[part 6 of 23: package /Cluster]
AUTOSAR XML (schema 4-3-0)
package /Cluster  (continued)
  can cluster E3V_EVCANFD: baudrate=500000, protocol-name=CAN, protocol-version=2.0, bus-off-recovery={bor-counter-l-1-to-l-2=1, bor-time-l-1=0.05, bor-time-l-2=0.2}, can-fd-baudrate=2000000  (continued)
    can physical channel CHNL: comm-connectors=CN_E3V_EVCANFD  (continued)
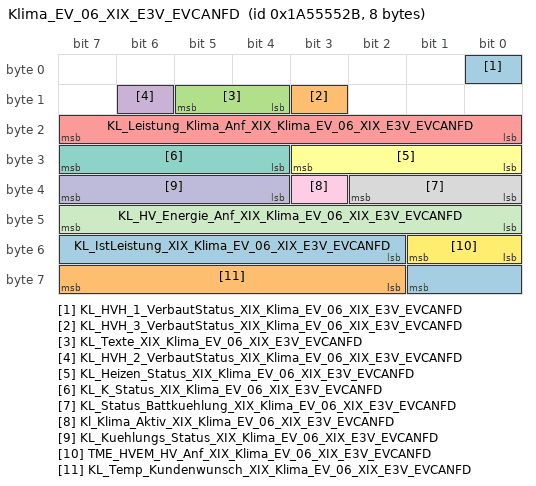
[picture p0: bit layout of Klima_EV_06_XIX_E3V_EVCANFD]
      frame Klima_EV_06_XIX_E3V_EVCANFD: id 0x1A55552B, from Klima, frame-length=8, can-addressing-mode=EXTENDED, can-frame-rx-behavior=CAN-FD, can-frame-tx-behavior=CAN-FD
        pdu Klima_EV_06_XIX_E3V_EVCANFD: length=8, transmission-mode-true-timing=cyclic-timing={time-offset=0.0, time-period=0.5}, unused-bit-pattern=0
          signal KL_HVH_1_VerbautStatus_XIX_Klima_EV_06_XIX_E3V_EVCANFD: start 0, 1 bit, little-endian, data-type-policy=OVERRIDE, i-signal-type=PRIMITIVE, init-value=0, base-type=BT_KL_HVH_1_VerbautStatus, compu {0=Cx0_nicht_verbaut (CM_KL_HVH_1_VerbautStatus_Cx0_nicht_verbaut), 1=Cx1_verbaut (CM_KL_HVH_1_VerbautStatus_Cx1_verbaut)}, range raw 0..1, transfer-property=PENDING  # Verbau Information HV_Heizer1
          signal KL_HVH_3_VerbautStatus_XIX_Klima_EV_06_XIX_E3V_EVCANFD: start 11, 1 bit, little-endian, data-type-policy=OVERRIDE, i-signal-type=PRIMITIVE, base-type=BT_KL_HVH_3_VerbautStatus, compu {0=Cx0_nicht_verbaut (CM_KL_HVH_3_VerbautStatus_Cx0_nicht_verbaut), 1=Cx1_verbaut (CM_KL_HVH_3_VerbautStatus_Cx1_verbaut)}, range raw 0..1, transfer-property=PENDING  # Verbauinformation für 3. HV-Heizer (Wasserheizer im MEB)
          signal KL_Texte_XIX_Klima_EV_06_XIX_E3V_EVCANFD: start 12, 2 bit, little-endian, data-type-policy=OVERRIDE, i-signal-type=PRIMITIVE, base-type=BT_KL_Texte, compu {0=Cx0_keine_Anzeige (CM_KL_Texte_Cx0_keine_Anzeige), 1=Cx1_Heizleistung_zu_gering (CM_KL_Texte_Cx1_Heizleistung_zu_gering), 2=Cx2_Kuehlleistung_zu_gering (CM_KL_Texte_Cx2_Kuehlleistung_zu_gering), 3=Cx3_Text_3 (CM_KL_Texte_Cx3_Text_3)}, range raw 0..3, transfer-property=PENDING  # Ein Defizit in Heizleistung bzw. Kühlleistung soll dem Kunden angezeigt werden
          signal KL_HVH_2_VerbautStatus_XIX_Klima_EV_06_XIX_E3V_EVCANFD: start 14, 1 bit, little-endian, data-type-policy=OVERRIDE, i-signal-type=PRIMITIVE, init-value=0, base-type=BT_KL_HVH_2_VerbautStatus, compu {0=Cx0_nicht_verbaut (CM_KL_HVH_2_VerbautStatus_Cx0_nicht_verbaut), 1=Cx1_verbaut (CM_KL_HVH_2_VerbautStatus_Cx1_verbaut)}, range raw 0..1, transfer-property=PENDING  # Verbau Information zusaetzlicher Heizer
          signal KL_Leistung_Klima_Anf_XIX_Klima_EV_06_XIX_E3V_EVCANFD: start 16, 8 bit, little-endian, data-type-policy=OVERRIDE, i-signal-type=PRIMITIVE, init-value=254, base-type=BT_KL_Leistung_Klima_Anf, compu {phys=raw*50 for raw 0..253, 254=Cxfe_Init (CM_KL_Leistung_Klima_Anf_Cxfe_Init); unit Unit_Watt}, range phys 0..12650 Unit_Watt, raw 0..254, unit=Unit_Watt, transfer-property=PENDING  # Leistungsanforderung ans HVEM von Klima
          signal KL_Heizen_Status_XIX_Klima_EV_06_XIX_E3V_EVCANFD: start 24, 4 bit, little-endian, data-type-policy=OVERRIDE, i-signal-type=PRIMITIVE, init-value=14, base-type=BT_KL_Heizen_Status, invalid-value=Invalid_KL_Heizen_Status_XIX_Klima_EV_06_XIX_E3V_EVCANFD:15, compu {0=Cx0_Keine_Heizleistung_Anfgefordert (CM_KL_Heizen_Status_Cx0_Keine_Heizleistung_Anfgefordert), 1=Cx1_Max_Defrost (CM_KL_Heizen_Status_Cx1_Max_Defrost), 2=Cx2_Kaltstart (CM_KL_Heizen_Status_Cx2_Kaltstart), 3=Cx3_Eingeschwungen_hohe_Last (CM_KL_Heizen_Status_Cx3_Eingeschwungen_hohe_Last), 4=Cx4_Eingeschwungen_niedrige_Last (CM_KL_Heizen_Status_Cx4_Eingeschwungen_niedrige_Last), 14=Cxe_Init (CM_KL_Heizen_Status_Cxe_Init), 15=Cxf_Fehler (CM_KL_Heizen_Status_Cxf_Fehler)}, range raw 0..15, transfer-property=PENDING  # Anforderungspriorität Unterkomponente zur Priorisierung und Leistungsverteilung im HV-EM
          signal KL_K_Status_XIX_Klima_EV_06_XIX_E3V_EVCANFD: start 28, 4 bit, little-endian, data-type-policy=OVERRIDE, i-signal-type=PRIMITIVE, init-value=0, base-type=BT_KL_K_Status, invalid-value=Invalid_KL_K_Status_XIX_Klima_EV_06_XIX_E3V_EVCANFD:14, compu {0=Cx0_Init (CM_KL_K_Status_Cx0_Init), 1=Cx1_Lueften (CM_KL_K_Status_Cx1_Lueften), 2=Cx2_Kuehlen_Innenraum (CM_KL_K_Status_Cx2_Kuehlen_Innenraum), 3=Cx3_Kuehlen_Chiller (CM_KL_K_Status_Cx3_Kuehlen_Chiller), 4=Cx4_Kuehlen_kombiniert (CM_KL_K_Status_Cx4_Kuehlen_kombiniert), 5=Cx5_Heizen_Luft_WP (CM_KL_K_Status_Cx5_Heizen_Luft_WP), 6=Cx6_Heizen_kombiniert_WP (CM_KL_K_Status_Cx6_Heizen_kombiniert_WP), 7=Cx7_Kuehlen_Innenraum_mit_HGK (CM_KL_K_Status_Cx7_Kuehlen_Innenraum_mit_HGK), 8=Cx8_Kuehlen_kombiniert_mit_HGK (CM_KL_K_Status_Cx8_Kuehlen_kombiniert_mit_HGK), 9=Cx9_Heizen_Wasser_WP (CM_KL_K_Status_Cx9_Heizen_Wasser_WP), 10=Cxa_Shutdown (CM_KL_K_Status_Cxa_Shutdown), 11=Cxb_Enteisen (CM_KL_K_Status_Cxb_Enteisen), 14=Cxe_Fehler (CM_KL_K_Status_Cxe_Fehler)}, range raw 0..14, transfer-property=PENDING  # Satus der Klimatisierung und Wärmepumpe wird ausgegeben.
          signal KL_Status_Battkuehlung_XIX_Klima_EV_06_XIX_E3V_EVCANFD: start 32, 3 bit, little-endian, data-type-policy=OVERRIDE, i-signal-type=PRIMITIVE, init-value=0, base-type=BT_KL_Status_Battkuehlung, compu {0=Cx0_Init (CM_KL_Status_Battkuehlung_Cx0_Init), 1=Cx1_Keine_Kuehlanforderung (CM_KL_Status_Battkuehlung_Cx1_Keine_Kuehlanforderung), 2=Cx2_Kuehlung_in_Ordnung (CM_KL_Status_Battkuehlung_Cx2_Kuehlung_in_Ordnung), 3=Cx3_Kuehlung_temporaer_nicht_aktiv (CM_KL_Status_Battkuehlung_Cx3_Kuehlung_temporaer_nicht_aktiv), 4=Cx4_Kuehlung_inaktiv_fuer_Komfort (CM_KL_Status_Battkuehlung_Cx4_Kuehlung_inaktiv_fuer_Komfort), 5=Cx5_Kuehlung_nicht_moeglich (CM_KL_Status_Battkuehlung_Cx5_Kuehlung_nicht_moeglich)}, range raw 0..5, transfer-property=PENDING  # Statusinformation über den akuellen Zustand der aktiven Batteriekühlung durch die Klimaanlage
          signal Kl_Klima_Aktiv_XIX_Klima_EV_06_XIX_E3V_EVCANFD: start 35, 1 bit, little-endian, data-type-policy=OVERRIDE, i-signal-type=PRIMITIVE, init-value=0, base-type=BT_Kl_Klima_Aktiv, compu {0=Cx0_Nicht_aktiv_oder_Init (CM_Kl_Klima_Aktiv_Cx0_Nicht_aktiv_oder_Init), 1=Cx1_Klima_aktiv (CM_Kl_Klima_Aktiv_Cx1_Klima_aktiv)}, range raw 0..1, transfer-property=PENDING  # Rückmeldung über HV Klimaaktivität durch Klimasteuergerät für BEV/PHEV
          signal KL_Kuehlungs_Status_XIX_Klima_EV_06_XIX_E3V_EVCANFD: start 36, 4 bit, little-endian, data-type-policy=OVERRIDE, i-signal-type=PRIMITIVE, init-value=14, base-type=BT_KL_Kuehlungs_Status, invalid-value=Invalid_KL_Kuehlungs_Status_XIX_Klima_EV_06_XIX_E3V_EVCANFD:15, compu {0=Cx0_Klimatisierung_ausgeschaltet (CM_KL_Kuehlungs_Status_Cx0_Klimatisierung_ausgeschaltet), 1=Cx1_Pulldown (CM_KL_Kuehlungs_Status_Cx1_Pulldown), 2=Cx2_Eingeschwungen_hohe_Last (CM_KL_Kuehlungs_Status_Cx2_Eingeschwungen_hohe_Last), 3=Cx3_Eingeschwungen_niedrige_Last (CM_KL_Kuehlungs_Status_Cx3_Eingeschwungen_niedrige_Last), 4=Cx4_Eingeschwungen_mit_Drehzahlbegre (CM_KL_Kuehlungs_Status_Cx4_Eingeschwungen_mit_Drehzahlbegre), 5=Cx5_BattK_nicht_moeglich (CM_KL_Kuehlungs_Status_Cx5_BattK_nicht_moeglich), 6=Cx6_BattK_temporaer_nicht_moeglich (CM_KL_Kuehlungs_Status_Cx6_BattK_temporaer_nicht_moeglich), 14=Cxe_Init (CM_KL_Kuehlungs_Status_Cxe_Init), 15=Cxf_Fehler (CM_KL_Kuehlungs_Status_Cxf_Fehler)}, range raw 0..15, transfer-property=PENDING  # Anforderungspriorität Unterkomponente zur Priorisierung und Leistungsverteilung im HV-EM
          signal KL_HV_Energie_Anf_XIX_Klima_EV_06_XIX_E3V_EVCANFD: start 40, 8 bit, little-endian, data-type-policy=OVERRIDE, i-signal-type=PRIMITIVE, init-value=254, base-type=BT_KL_HV_Energie_Anf, invalid-value=Invalid_KL_HV_Energie_Anf_XIX_Klima_EV_06_XIX_E3V_EVCANFD:255, compu {phys=raw*50 for raw 0..252, 253=Cxfd_nicht_berechnet (CM_KL_HV_Energie_Anf_Cxfd_nicht_berechnet), 254=Cxfe_Init (CM_KL_HV_Energie_Anf_Cxfe_Init), 255=Cxff_Fehler (CM_KL_HV_Energie_Anf_Cxff_Fehler); unit Unit_WattHour}, range phys 0..12600 Unit_WattHour, raw 0..255, unit=Unit_WattHour, transfer-property=PENDING  # Anforderung HV - Energiebedarf, für VoKo
          signal TME_HVEM_HV_Anf_XIX_Klima_EV_06_XIX_E3V_EVCANFD: start 48, 2 bit, little-endian, data-type-policy=OVERRIDE, i-signal-type=PRIMITIVE, init-value=0, base-type=BT_TME_HVEM_HV_Anf, invalid-value=Invalid_TME_HVEM_HV_Anf_XIX_Klima_EV_06_XIX_E3V_EVCANFD:3, compu {0=Cx0_INIT (CM_TME_HVEM_HV_Anf_Cx0_INIT), 1=Cx1_HV_Netz_nicht_angefordert (CM_TME_HVEM_HV_Anf_Cx1_HV_Netz_nicht_angefordert), 2=Cx2_HV_Netz_angefordert (CM_TME_HVEM_HV_Anf_Cx2_HV_Netz_angefordert), 3=Cx3_Fehler (CM_TME_HVEM_HV_Anf_Cx3_Fehler)}, range raw 0..3, transfer-property=PENDING  # Anforderung "HV-Netz aktivieren" wegen Innenraumkonditionierung mit HV-Komponente
          signal KL_IstLeistung_XIX_Klima_EV_06_XIX_E3V_EVCANFD: start 50, 8 bit, little-endian, data-type-policy=OVERRIDE, i-signal-type=PRIMITIVE, init-value=254, base-type=BT_KL_IstLeistung, invalid-value=Invalid_KL_IstLeistung_XIX_Klima_EV_06_XIX_E3V_EVCANFD:255, compu {phys=raw*50 for raw 0..253, 254=Cxfe_Init (CM_KL_IstLeistung_Cxfe_Init), 255=Cxff_Fehler (CM_KL_IstLeistung_Cxff_Fehler); unit Unit_Watt}, range phys 0..12650 Unit_Watt, raw 0..255, unit=Unit_Watt, transfer-property=PENDING  # Gesamt-Ist-Leistung für Komfort- und Thermomanagement
          signal KL_Temp_Kundenwunsch_XIX_Klima_EV_06_XIX_E3V_EVCANFD: start 58, 6 bit, little-endian, data-type-policy=OVERRIDE, i-signal-type=PRIMITIVE, init-value=0, base-type=BT_KL_Temp_Kundenwunsch, invalid-value=Invalid_KL_Temp_Kundenwunsch_XIX_Klima_EV_06_XIX_E3V_EVCANFD:63, compu {0=Cx0_Init (CM_KL_Temp_Kundenwunsch_Cx0_Init), 1=Cx1_LO (CM_KL_Temp_Kundenwunsch_Cx1_LO), phys=raw*0.5+15 for raw 2..29, 30=Cx1e_HI (CM_KL_Temp_Kundenwunsch_Cx1e_HI), 63=Cx3f_Fehler (CM_KL_Temp_Kundenwunsch_Cx3f_Fehler); unit Unit_DegreCelsi}, range phys 16..29.5 Unit_DegreCelsi, raw 0..63, unit=Unit_DegreCelsi, transfer-property=PENDING  # Temeratur, die auf der Fahrerseite der Climatronic vom Kunden vorgegeben wird.
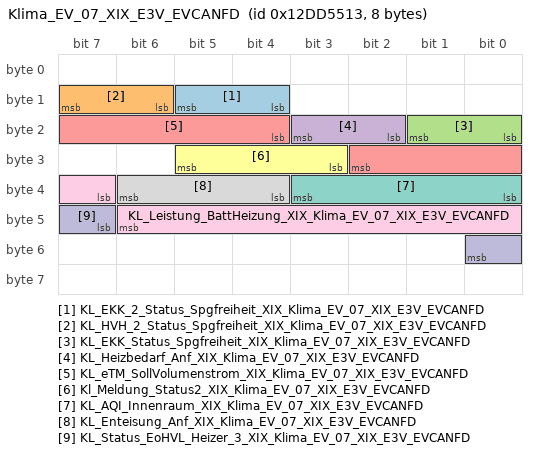
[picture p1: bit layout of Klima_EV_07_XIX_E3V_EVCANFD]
      frame Klima_EV_07_XIX_E3V_EVCANFD: id 0x12DD5513, from Klima, frame-length=8, can-addressing-mode=EXTENDED, can-frame-rx-behavior=CAN-FD, can-frame-tx-behavior=CAN-FD
        pdu Klima_EV_07_XIX_E3V_EVCANFD: length=8, transmission-mode-true-timing=cyclic-timing={time-offset=0.0, time-period=0.1}, unused-bit-pattern=0
          signal KL_EKK_2_Status_Spgfreiheit_XIX_Klima_EV_07_XIX_E3V_EVCANFD: start 12, 2 bit, little-endian, data-type-policy=OVERRIDE, i-signal-type=PRIMITIVE, init-value=0, base-type=BT_KL_EKK_2_Status_Spgfreiheit, invalid-value=Invalid_KL_EKK_2_Status_Spgfreiheit_XIX_Klima_EV_07_XIX_E3V_EVCANFD:3, compu {0=Cx0_Init (CM_KL_EKK_2_Status_Spgfreiheit_Cx0_Init), 1=Cx1_Komponente_spannungsfrei (CM_KL_EKK_2_Status_Spgfreiheit_Cx1_Komponente_spannungsfrei), 2=Cx2_Kompomente_nicht_spannungsfrei (CM_KL_EKK_2_Status_Spgfreiheit_Cx2_Kompomente_nicht_spannungsfrei), 3=Cx3_Fehler (CM_KL_EKK_2_Status_Spgfreiheit_Cx3_Fehler)}, range raw 0..3, transfer-property=PENDING  # Status Spannungsfreiheit des EKK
          signal KL_HVH_2_Status_Spgfreiheit_XIX_Klima_EV_07_XIX_E3V_EVCANFD: start 14, 2 bit, little-endian, data-type-policy=OVERRIDE, i-signal-type=PRIMITIVE, init-value=0, base-type=BT_KL_HVH_2_Status_Spgfreiheit, invalid-value=Invalid_KL_HVH_2_Status_Spgfreiheit_XIX_Klima_EV_07_XIX_E3V_EVCANFD:3, compu {0=Cx0_Init (CM_KL_HVH_2_Status_Spgfreiheit_Cx0_Init), 1=Cx1_Komponente_spannungsfrei (CM_KL_HVH_2_Status_Spgfreiheit_Cx1_Komponente_spannungsfrei), 2=Cx2_Kompomente_nicht_spannungsfrei (CM_KL_HVH_2_Status_Spgfreiheit_Cx2_Kompomente_nicht_spannungsfrei), 3=Cx3_Fehler (CM_KL_HVH_2_Status_Spgfreiheit_Cx3_Fehler)}, range raw 0..3, transfer-property=PENDING  # Status Spannungsfreiheit des zusätzlichen PTC Heizer
          signal KL_EKK_Status_Spgfreiheit_XIX_Klima_EV_07_XIX_E3V_EVCANFD: start 16, 2 bit, little-endian, data-type-policy=OVERRIDE, i-signal-type=PRIMITIVE, init-value=0, base-type=BT_KL_EKK_Status_Spgfreiheit, invalid-value=Invalid_KL_EKK_Status_Spgfreiheit_XIX_Klima_EV_07_XIX_E3V_EVCANFD:3, compu {0=Cx0_Init (CM_KL_EKK_Status_Spgfreiheit_Cx0_Init), 1=Cx1_Komponente_spannungsfrei (CM_KL_EKK_Status_Spgfreiheit_Cx1_Komponente_spannungsfrei), 2=Cx2_Kompomente_nicht_spannungsfrei (CM_KL_EKK_Status_Spgfreiheit_Cx2_Kompomente_nicht_spannungsfrei), 3=Cx3_Fehler (CM_KL_EKK_Status_Spgfreiheit_Cx3_Fehler)}, range raw 0..3, transfer-property=PENDING  # Status Spannungsfreiheit des EKK1
          signal KL_Heizbedarf_Anf_XIX_Klima_EV_07_XIX_E3V_EVCANFD: start 18, 2 bit, little-endian, data-type-policy=OVERRIDE, i-signal-type=PRIMITIVE, init-value=2, base-type=BT_KL_Heizbedarf_Anf, invalid-value=Invalid_KL_Heizbedarf_Anf_XIX_Klima_EV_07_XIX_E3V_EVCANFD:3, compu {0=Cx0_keine_Anforderung (CM_KL_Heizbedarf_Anf_Cx0_keine_Anforderung), 1=Cx1_Anforderung (CM_KL_Heizbedarf_Anf_Cx1_Anforderung), 2=Cx2_Init (CM_KL_Heizbedarf_Anf_Cx2_Init), 3=Cx3_Fehler (CM_KL_Heizbedarf_Anf_Cx3_Fehler)}, range raw 0..3, transfer-property=PENDING  # Das Klima SG fordert von der Batterie Heizbedarf aus dem Kühlkreislauf an
          signal KL_eTM_SollVolumenstrom_XIX_Klima_EV_07_XIX_E3V_EVCANFD: start 20, 7 bit, little-endian, data-type-policy=OVERRIDE, i-signal-type=PRIMITIVE, init-value=127, base-type=BT_KL_eTM_SollVolumenstrom, compu {phys=raw*0.125 for raw 0..120, 127=Cx7f_Init (CM_KL_eTM_SollVolumenstrom_Cx7f_Init); unit Unit_LiterPerMinut}, range phys 0..15 Unit_LiterPerMinut, raw 0..127, unit=Unit_LiterPerMinut, transfer-property=PENDING  # Wasservolumenstrom Anforderung von Klima an das ASG
          signal Kl_Meldung_Status2_XIX_Klima_EV_07_XIX_E3V_EVCANFD: start 27, 3 bit, little-endian, data-type-policy=OVERRIDE, i-signal-type=PRIMITIVE, init-value=0, base-type=BT_Kl_Meldung_Status2, compu {0=Cx0_Klima_funktioniert (CM_Kl_Meldung_Status2_Cx0_Klima_funktioniert), 1=Cx1_Klima_eingeschraenkt (CM_Kl_Meldung_Status2_Cx1_Klima_eingeschraenkt), 2=Cx2_Klima_defekt (CM_Kl_Meldung_Status2_Cx2_Klima_defekt), 3=Cx3_Klima_Reserve (CM_Kl_Meldung_Status2_Cx3_Klima_Reserve), 7=Cx7_Init (CM_Kl_Meldung_Status2_Cx7_Init)}, range raw 0..7, transfer-property=PENDING  # Meldung zum Zustand des Klima Systems
          signal KL_AQI_Innenraum_XIX_Klima_EV_07_XIX_E3V_EVCANFD: start 32, 4 bit, little-endian, data-type-policy=OVERRIDE, i-signal-type=PRIMITIVE, init-value=14, base-type=BT_KL_AQI_Innenraum, invalid-value=Invalid_KL_AQI_Innenraum_XIX_Klima_EV_07_XIX_E3V_EVCANFD:15, compu {0=Cx0_Saubere_Luft (CM_KL_AQI_Innenraum_Cx0_Saubere_Luft), 1=Cx1_Luftverschmutzung_10_Prozent (CM_KL_AQI_Innenraum_Cx1_Luftverschmutzung_10_Prozent), 2=Cx2_Luftverschmutzung_20_Prozent (CM_KL_AQI_Innenraum_Cx2_Luftverschmutzung_20_Prozent), 3=Cx3_Luftverschmutzung_30_Prozent (CM_KL_AQI_Innenraum_Cx3_Luftverschmutzung_30_Prozent), 4=Cx4_Luftverschmutzung_40_Prozent (CM_KL_AQI_Innenraum_Cx4_Luftverschmutzung_40_Prozent), 5=Cx5_Luftverschmutzung_50_Prozent (CM_KL_AQI_Innenraum_Cx5_Luftverschmutzung_50_Prozent), 6=Cx6_Luftverschmutzung_60_Prozent (CM_KL_AQI_Innenraum_Cx6_Luftverschmutzung_60_Prozent), 7=Cx7_Luftverschmutzung_70_Prozent (CM_KL_AQI_Innenraum_Cx7_Luftverschmutzung_70_Prozent), 8=Cx8_Luftverschmutzung_80_Prozent (CM_KL_AQI_Innenraum_Cx8_Luftverschmutzung_80_Prozent), 9=Cx9_Luftverschmutzung_90_Prozent (CM_KL_AQI_Innenraum_Cx9_Luftverschmutzung_90_Prozent), 10=Cxa_Luftverschmutzung_100_Prozent (CM_KL_AQI_Innenraum_Cxa_Luftverschmutzung_100_Prozent), 14=Cxe_Init (CM_KL_AQI_Innenraum_Cxe_Init), 15=Cxf_Fehler (CM_KL_AQI_Innenraum_Cxf_Fehler)}, range raw 0..15, transfer-property=PENDING  # Weiterleitung der Luftgüte im Innenraum auf den CAN
          signal KL_Enteisung_Anf_XIX_Klima_EV_07_XIX_E3V_EVCANFD: start 36, 3 bit, little-endian, data-type-policy=OVERRIDE, i-signal-type=PRIMITIVE, init-value=6, base-type=BT_KL_Enteisung_Anf, invalid-value=Invalid_KL_Enteisung_Anf_XIX_Klima_EV_07_XIX_E3V_EVCANFD:7, compu {0=Cx0_Keine_Enteisung_angefordert (CM_KL_Enteisung_Anf_Cx0_Keine_Enteisung_angefordert), 1=Cx1_Enteisung_UmgWT_angefordert (CM_KL_Enteisung_Anf_Cx1_Enteisung_UmgWT_angefordert), 2=Cx2_Enteisung_NTK_angefordert (CM_KL_Enteisung_Anf_Cx2_Enteisung_NTK_angefordert), 6=Cx6_Init (CM_KL_Enteisung_Anf_Cx6_Init), 7=Cx7_Fehler (CM_KL_Enteisung_Anf_Cx7_Fehler)}, range raw 0..7, transfer-property=PENDING  # Enteisung des NTK/WT von Klima angefordert
          signal KL_Leistung_BattHeizung_XIX_Klima_EV_07_XIX_E3V_EVCANFD: start 39, 8 bit, little-endian, data-type-policy=OVERRIDE, i-signal-type=PRIMITIVE, init-value=254, base-type=BT_KL_Leistung_BattHeizung, invalid-value=Invalid_KL_Leistung_BattHeizung_XIX_Klima_EV_07_XIX_E3V_EVCANFD:255, compu {phys=raw*50 for raw 0..250, 253=Cxfd_nicht_verbaut (CM_KL_Leistung_BattHeizung_Cxfd_nicht_verbaut), 254=Cxfe_Init (CM_KL_Leistung_BattHeizung_Cxfe_Init), 255=Cxff_Fehler (CM_KL_Leistung_BattHeizung_Cxff_Fehler); unit Unit_Watt}, range phys 0..12500 Unit_Watt, raw 0..255, unit=Unit_Watt, transfer-property=PENDING  # aktuelle elektrische Leistung des vom CCM angesteuerten Batterieheizers
          signal KL_Status_EoHVL_Heizer_3_XIX_Klima_EV_07_XIX_E3V_EVCANFD: start 47, 2 bit, little-endian, data-type-policy=OVERRIDE, i-signal-type=PRIMITIVE, init-value=0, base-type=BT_KL_Status_EoHVL_Heizer_3, invalid-value=Invalid_KL_Status_EoHVL_Heizer_3_XIX_Klima_EV_07_XIX_E3V_EVCANFD:3, compu {0=Cx0_Init (CM_KL_Status_EoHVL_Heizer_3_Cx0_Init), 1=Cx1_Keine_offene_HV_Leitung_erkannt (CM_KL_Status_EoHVL_Heizer_3_Cx1_Keine_offene_HV_Leitung_erkannt), 2=Cx2_offene_HV_Leitung_erkannt (CM_KL_Status_EoHVL_Heizer_3_Cx2_offene_HV_Leitung_erkannt), 3=Cx3_Fehler (CM_KL_Status_EoHVL_Heizer_3_Cx3_Fehler)}, range raw 0..3, transfer-property=PENDING  # Erkennung einer offenen HV-Leitung (EoHVL) für 3. HV-Heizer (Wasserheizer im MEB). Bewertet anhand einer Spannungsgrenze.
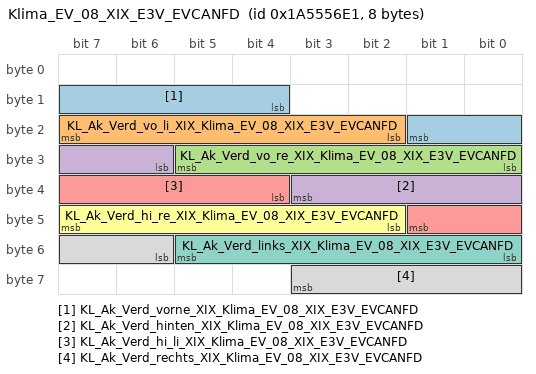
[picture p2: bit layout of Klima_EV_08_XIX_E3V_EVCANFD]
      frame Klima_EV_08_XIX_E3V_EVCANFD: id 0x1A5556E1, from Klima, frame-length=8, can-addressing-mode=EXTENDED, can-frame-rx-behavior=CAN-FD, can-frame-tx-behavior=CAN-FD
        pdu Klima_EV_08_XIX_E3V_EVCANFD: length=8, transmission-mode-true-timing=cyclic-timing={time-offset=0.0, time-period=1.0}, unused-bit-pattern=0  # Akustikgrenze Verdampfer
          signal KL_Ak_Verd_vorne_XIX_Klima_EV_08_XIX_E3V_EVCANFD: start 12, 6 bit, little-endian, data-type-policy=OVERRIDE, i-signal-type=PRIMITIVE, init-value=0, base-type=BT_KL_Ak_Verd_vorne, compu {phys=raw+20 for raw 0..63; unit Unit_DeziBel}, range phys 20..83 Unit_DeziBel, raw 0..63, unit=Unit_DeziBel, transfer-property=PENDING  # Akustik Grenze Verdampfer
          signal KL_Ak_Verd_vo_li_XIX_Klima_EV_08_XIX_E3V_EVCANFD: start 18, 6 bit, little-endian, data-type-policy=OVERRIDE, i-signal-type=PRIMITIVE, init-value=0, base-type=BT_KL_Ak_Verd_vo_li, compu {phys=raw+20 for raw 0..63; unit Unit_DeziBel}, range phys 20..83 Unit_DeziBel, raw 0..63, unit=Unit_DeziBel, transfer-property=PENDING  # Akustik Grenze Verdampfer
          signal KL_Ak_Verd_vo_re_XIX_Klima_EV_08_XIX_E3V_EVCANFD: start 24, 6 bit, little-endian, data-type-policy=OVERRIDE, i-signal-type=PRIMITIVE, init-value=0, base-type=BT_KL_Ak_Verd_vo_re, compu {phys=raw+20 for raw 0..63; unit Unit_DeziBel}, range phys 20..83 Unit_DeziBel, raw 0..63, unit=Unit_DeziBel, transfer-property=PENDING  # Akustik Grenze Verdampfer
          signal KL_Ak_Verd_hinten_XIX_Klima_EV_08_XIX_E3V_EVCANFD: start 30, 6 bit, little-endian, data-type-policy=OVERRIDE, i-signal-type=PRIMITIVE, init-value=0, base-type=BT_KL_Ak_Verd_hinten, compu {phys=raw+20 for raw 0..63; unit Unit_DeziBel}, range phys 20..83 Unit_DeziBel, raw 0..63, unit=Unit_DeziBel, transfer-property=PENDING  # Akustik Grenze Verdampfer
          signal KL_Ak_Verd_hi_li_XIX_Klima_EV_08_XIX_E3V_EVCANFD: start 36, 6 bit, little-endian, data-type-policy=OVERRIDE, i-signal-type=PRIMITIVE, init-value=0, base-type=BT_KL_Ak_Verd_hi_li, compu {phys=raw+20 for raw 0..63; unit Unit_DeziBel}, range phys 20..83 Unit_DeziBel, raw 0..63, unit=Unit_DeziBel, transfer-property=PENDING  # Akustik Grenze Verdampfer
          signal KL_Ak_Verd_hi_re_XIX_Klima_EV_08_XIX_E3V_EVCANFD: start 42, 6 bit, little-endian, data-type-policy=OVERRIDE, i-signal-type=PRIMITIVE, init-value=0, base-type=BT_KL_Ak_Verd_hi_re, compu {phys=raw+20 for raw 0..63; unit Unit_DeziBel}, range phys 20..83 Unit_DeziBel, raw 0..63, unit=Unit_DeziBel, transfer-property=PENDING  # Akustik Grenze Verdampfer
          signal KL_Ak_Verd_links_XIX_Klima_EV_08_XIX_E3V_EVCANFD: start 48, 6 bit, little-endian, data-type-policy=OVERRIDE, i-signal-type=PRIMITIVE, init-value=0, base-type=BT_KL_Ak_Verd_links, compu {phys=raw+20 for raw 0..63; unit Unit_DeziBel}, range phys 20..83 Unit_DeziBel, raw 0..63, unit=Unit_DeziBel, transfer-property=PENDING  # Akustik Grenze Verdampfer
          signal KL_Ak_Verd_rechts_XIX_Klima_EV_08_XIX_E3V_EVCANFD: start 54, 6 bit, little-endian, data-type-policy=OVERRIDE, i-signal-type=PRIMITIVE, init-value=0, base-type=BT_KL_Ak_Verd_rechts, compu {phys=raw+20 for raw 0..63; unit Unit_DeziBel}, range phys 20..83 Unit_DeziBel, raw 0..63, unit=Unit_DeziBel, transfer-property=PENDING  # Akustik Grenze Verdampfer
      frame Klima_EV_09_XIX_E3V_EVCANFD: id 0x16A955D9, from Klima, frame-length=16, can-addressing-mode=EXTENDED, can-frame-rx-behavior=CAN-FD, can-frame-tx-behavior=CAN-FD
        pdu Klima_EV_09_XIX_E3V_EVCANFD: length=16, transmission-mode-true-timing=cyclic-timing={time-offset=0, time-period=0.2}, unused-bit-pattern=0
          signal KL_Wasserheizer_Ansteuerung_XIX_Klima_EV_09_XIX_E3V_EVCANFD: start 16, 8 bit, little-endian, data-type-policy=OVERRIDE, i-signal-type=PRIMITIVE, init-value=254, base-type=BT_KL_Wasserheizer_Ansteuerung, invalid-value=Invalid_KL_Wasserheizer_Ansteuerung_XIX_Klima_EV_09_XIX_E3V_EVCANFD:255, compu {phys=raw for raw 0..100, 254=Cxfe_Init (CM_KL_Wasserheizer_Ansteuerung_Cxfe_Init), 255=Cxff_Fehler (CM_KL_Wasserheizer_Ansteuerung_Cxff_Fehler); unit Unit_PerCent}, range phys 0..100 Unit_PerCent, raw 0..255, unit=Unit_PerCent, transfer-property=PENDING  # Ansteuerung des HV-Wasserheizers HVH6 in %
          signal KL_Wasserheizer_Status_XIX_Klima_EV_09_XIX_E3V_EVCANFD: start 24, 3 bit, little-endian, data-type-policy=OVERRIDE, i-signal-type=PRIMITIVE, init-value=6, base-type=BT_KL_Wasserheizer_Status, invalid-value=Invalid_KL_Wasserheizer_Status_XIX_Klima_EV_09_XIX_E3V_EVCANFD:7, compu {0=Cx0_Aus (CM_KL_Wasserheizer_Status_Cx0_Aus), 1=Cx1_Volle_Heizleistung (CM_KL_Wasserheizer_Status_Cx1_Volle_Heizleistung), 2=Cx2_Mangel_Energiekontingent (CM_KL_Wasserheizer_Status_Cx2_Mangel_Energiekontingent), 3=Cx3_reserved (CM_KL_Wasserheizer_Status_Cx3_reserved), 4=Cx4_reserved (CM_KL_Wasserheizer_Status_Cx4_reserved), 5=Cx5_reserved (CM_KL_Wasserheizer_Status_Cx5_reserved), 6=Cx6_Init (CM_KL_Wasserheizer_Status_Cx6_Init), 7=Cx7_Fehler (CM_KL_Wasserheizer_Status_Cx7_Fehler)}, range raw 0..7, transfer-property=PENDING  # Zustand des von Klima angesteuerten Wasserheizers
          signal KL_Batterieheizen_Freigabe_XIX_Klima_EV_09_XIX_E3V_EVCANFD: start 27, 3 bit, little-endian, data-type-policy=OVERRIDE, i-signal-type=PRIMITIVE, init-value=6, base-type=BT_KL_Batterieheizen_Freigabe, invalid-value=Invalid_KL_Batterieheizen_Freigabe_XIX_Klima_EV_09_XIX_E3V_EVCANFD:7, compu {0=Cx0_Keine_Freigabe (CM_KL_Batterieheizen_Freigabe_Cx0_Keine_Freigabe), 1=Cx1_Freigabe (CM_KL_Batterieheizen_Freigabe_Cx1_Freigabe), 2=Cx2_Leistungsreserve_Stufe_1 (CM_KL_Batterieheizen_Freigabe_Cx2_Leistungsreserve_Stufe_1), 3=Cx3_Leistungsreserve_Stufe_2 (CM_KL_Batterieheizen_Freigabe_Cx3_Leistungsreserve_Stufe_2), 4=Cx4_Leistungsreserve_Stufe_3 (CM_KL_Batterieheizen_Freigabe_Cx4_Leistungsreserve_Stufe_3), 5=Cx5_PTC_Leistungsgrenze_erreicht (CM_KL_Batterieheizen_Freigabe_Cx5_PTC_Leistungsgrenze_erreicht), 6=Cx6_Init (CM_KL_Batterieheizen_Freigabe_Cx6_Init), 7=Cx7_Fehler (CM_KL_Batterieheizen_Freigabe_Cx7_Fehler)}, range raw 0..7, transfer-property=PENDING  # Freigabe für Batterieheizen und Heizleistungserhöhung für Batterie in einem gemeinsamen von Batterie und Klima genutzten HV-Wasserheizer.
          signal KL_Reheat_Innenraum_XIX_Klima_EV_09_XIX_E3V_EVCANFD: start 30, 2 bit, little-endian, data-type-policy=OVERRIDE, i-signal-type=PRIMITIVE, init-value=2, base-type=BT_KL_Reheat_Innenraum, invalid-value=Invalid_KL_Reheat_Innenraum_XIX_Klima_EV_09_XIX_E3V_EVCANFD:3, compu {0=Cx0_off (CM_KL_Reheat_Innenraum_Cx0_off), 1=Cx1_Reheat_angefordert (CM_KL_Reheat_Innenraum_Cx1_Reheat_angefordert), 2=Cx2_Init (CM_KL_Reheat_Innenraum_Cx2_Init), 3=Cx3_Fehler (CM_KL_Reheat_Innenraum_Cx3_Fehler)}, range raw 0..3, transfer-property=PENDING  # Mitteilung zum Betriebsmodus Reheat für die Innenraumklimatisierung
          signal KL_Temp_vor_NTK_XIX_Klima_EV_09_XIX_E3V_EVCANFD: start 32, 8 bit, little-endian, data-type-policy=OVERRIDE, i-signal-type=PRIMITIVE, init-value=254, base-type=BT_KL_Temp_vor_NTK, invalid-value=Invalid_KL_Temp_vor_NTK_XIX_Klima_EV_09_XIX_E3V_EVCANFD:255, compu {phys=raw-50 for raw 0..220, 253=Cxfd_Sensor_nicht_verbaut (CM_KL_Temp_vor_NTK_Cxfd_Sensor_nicht_verbaut), 254=Cxfe_Init (CM_KL_Temp_vor_NTK_Cxfe_Init), 255=Cxff_Fehler (CM_KL_Temp_vor_NTK_Cxff_Fehler); unit Unit_DegreCelsi}, range phys -50..170 Unit_DegreCelsi, raw 0..255, unit=Unit_DegreCelsi, transfer-property=PENDING  # Messwert der Wassertemperatur vor dem NTK
          signal KL_Wasserheizer_IstTemp_Ausgang_XIX_Klima_EV_09_XIX_E3V_EVCANFD: start 40, 8 bit, little-endian, data-type-policy=OVERRIDE, i-signal-type=PRIMITIVE, init-value=254, base-type=BT_KL_Wasserheizer_IstTemp_Ausgang, invalid-value=Invalid_KL_Wasserheizer_IstTemp_Ausgang_XIX_Klima_EV_09_XIX_E3V_EVCANFD:255, compu {phys=raw-50 for raw 0..220, 254=Cxfe_Init (CM_KL_Wasserheizer_IstTemp_Ausgang_Cxfe_Init), 255=Cxff_Fehler (CM_KL_Wasserheizer_IstTemp_Ausgang_Cxff_Fehler); unit Unit_DegreCelsi}, range phys -50..170 Unit_DegreCelsi, raw 0..255, unit=Unit_DegreCelsi, transfer-property=PENDING  # Vom Wasserheizer gemessene Ausgangstemperatur (in Standard Durchflussrichtung)
          signal KL_Wasserheizer_IstTemp_Eingang_XIX_Klima_EV_09_XIX_E3V_EVCANFD: start 48, 8 bit, little-endian, data-type-policy=OVERRIDE, i-signal-type=PRIMITIVE, init-value=254, base-type=BT_KL_Wasserheizer_IstTemp_Eingang, invalid-value=Invalid_KL_Wasserheizer_IstTemp_Eingang_XIX_Klima_EV_09_XIX_E3V_EVCANFD:255, compu {phys=raw-50 for raw 0..220, 254=Cxfe_Init (CM_KL_Wasserheizer_IstTemp_Eingang_Cxfe_Init), 255=Cxff_Fehler (CM_KL_Wasserheizer_IstTemp_Eingang_Cxff_Fehler); unit Unit_DegreCelsi}, range phys -50..170 Unit_DegreCelsi, raw 0..255, unit=Unit_DegreCelsi, transfer-property=PENDING  # Vom Wasserheizer gemessene Eingangstemperatur (in Standard Durchflussrichtung)
          signal KL_Wasserheizer_SollTemp_Ausgang_XIX_Klima_EV_09_XIX_E3V_EVCANFD: start 56, 8 bit, little-endian, data-type-policy=OVERRIDE, i-signal-type=PRIMITIVE, init-value=254, base-type=BT_KL_Wasserheizer_SollTemp_Ausgang, invalid-value=Invalid_KL_Wasserheizer_SollTemp_Ausgang_XIX_Klima_EV_09_XIX_E3V_EVCANFD:255, compu {phys=raw-50 for raw 0..220, 254=Cxfe_Init (CM_KL_Wasserheizer_SollTemp_Ausgang_Cxfe_Init), 255=Cxff_Fehler (CM_KL_Wasserheizer_SollTemp_Ausgang_Cxff_Fehler); unit Unit_DegreCelsi}, range phys -50..170 Unit_DegreCelsi, raw 0..255, unit=Unit_DegreCelsi, transfer-property=PENDING  # Von Klima angestrebte Sollwassertemperatur nach dem HV-Wasserheizer
          signal KL_Anf_rLM_XIX_Klima_EV_09_XIX_E3V_EVCANFD: start 64, 7 bit, little-endian, data-type-policy=OVERRIDE, i-signal-type=PRIMITIVE, init-value=126, base-type=BT_KL_Anf_rLM, invalid-value=Invalid_KL_Anf_rLM_XIX_Klima_EV_09_XIX_E3V_EVCANFD:127, compu {phys=raw for raw 0..100, 126=Cx7e_Init (CM_KL_Anf_rLM_Cx7e_Init), 127=Cx7f_Fehler (CM_KL_Anf_rLM_Cx7f_Fehler); unit Unit_PerCent}, range phys 0..100 Unit_PerCent, raw 0..127, unit=Unit_PerCent, transfer-property=PENDING  # Durch Klima angeforderter relativer Luftmassenstrom über Kühlerpaket
          signal KL_HWT_Sollvolumenstrom_XIX_Klima_EV_09_XIX_E3V_EVCANFD: start 71, 7 bit, little-endian, data-type-policy=OVERRIDE, i-signal-type=PRIMITIVE, init-value=126, base-type=BT_KL_HWT_Sollvolumenstrom, invalid-value=Invalid_KL_HWT_Sollvolumenstrom_XIX_Klima_EV_09_XIX_E3V_EVCANFD:127, compu {phys=raw*0.1 for raw 0..100, 126=Cx7e_Init (CM_KL_HWT_Sollvolumenstrom_Cx7e_Init), 127=Cx7f_Fehler (CM_KL_HWT_Sollvolumenstrom_Cx7f_Fehler); unit Unit_LiterPerMinut}, range phys 0..10 Unit_LiterPerMinut, raw 0..127, unit=Unit_LiterPerMinut, transfer-property=PENDING  # Sollvolumenstrom über den Heizungswärmetauscher für das Erwärmen des Innenraums.
      frame Klima_EV_10_SOK_XIX_E3V_EVCANFD: id 0x1A5554F6, from Klima, frame-length=16, can-addressing-mode=EXTENDED, can-frame-rx-behavior=CAN-FD, can-frame-tx-behavior=CAN-FD
        secured i pdu Klima_EV_10_SOK_XIX_E3V_EVCANFD:
          length=16
          authentication-props=SecureCommunicationAuthenticationProps_XIX_64
          freshness-props=SecureCommunicationFreshnessProps
          payload=PT_Klima_EV_10
          secure-communication-props={auth-data-freshness-length=0, auth-data-freshness-start-position=0, auth-info-tx-length=64, authentication-build-attempts=1, authentication-retries=4, data-id=842, freshness-value-id=1, freshness-value-length=64, freshness-value-tx-length=0}
          use-as-cryptographic-i-pdu=false
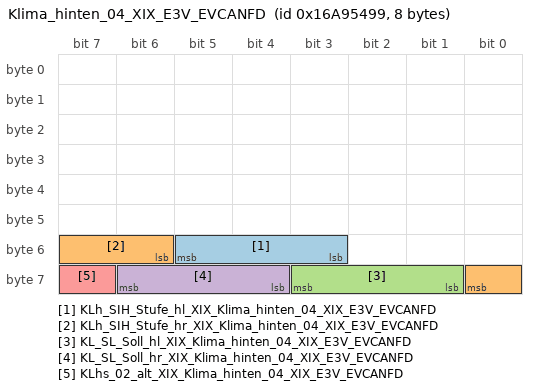
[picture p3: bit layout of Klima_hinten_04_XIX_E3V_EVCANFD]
      frame Klima_hinten_04_XIX_E3V_EVCANFD: id 0x16A95499, from Klima, frame-length=8, can-addressing-mode=EXTENDED, can-frame-rx-behavior=CAN-FD, can-frame-tx-behavior=CAN-FD
        pdu Klima_hinten_04_XIX_E3V_EVCANFD: length=8, minimum-delay=0.1, transmission-mode-true-timing={cyclic-timing={time-offset=0.0, time-period=1.0}, event-controlled-timing={number-of-repetitions=0, repetition-period=0.0}}, unused-bit-pattern=0
          signal KLh_SIH_Stufe_hl_XIX_Klima_hinten_04_XIX_E3V_EVCANFD: start 51, 3 bit, little-endian, data-type-policy=OVERRIDE, i-signal-type=PRIMITIVE, base-type=BT_KLh_SIH_Stufe_hl, compu {0=Cx0_Stufe_0 (CM_KLh_SIH_Stufe_hl_Cx0_Stufe_0), 1=Cx1_Stufe_1 (CM_KLh_SIH_Stufe_hl_Cx1_Stufe_1), 2=Cx2_Stufe_2 (CM_KLh_SIH_Stufe_hl_Cx2_Stufe_2), 3=Cx3_Stufe_3 (CM_KLh_SIH_Stufe_hl_Cx3_Stufe_3), 4=Cx4_Stufe_4 (CM_KLh_SIH_Stufe_hl_Cx4_Stufe_4), 5=Cx5_Stufe_5 (CM_KLh_SIH_Stufe_hl_Cx5_Stufe_5), 6=Cx6_Stufe_6 (CM_KLh_SIH_Stufe_hl_Cx6_Stufe_6)}, range raw 0..6, transfer-property=TRIGGERED-ON-CHANGE-WITHOUT-REPETITION  # Aktive Stufe Sitzheizung Heck links, auf deren Basis die Sitzheizungsmatten bestromt werden. Bei dreistufigen Sitzheizungen wird Stufe 0/2/4/6 verwendet.
          signal KLh_SIH_Stufe_hr_XIX_Klima_hinten_04_XIX_E3V_EVCANFD: start 54, 3 bit, little-endian, data-type-policy=OVERRIDE, i-signal-type=PRIMITIVE, base-type=BT_KLh_SIH_Stufe_hr, compu {0=Cx0_Stufe_0 (CM_KLh_SIH_Stufe_hr_Cx0_Stufe_0), 1=Cx1_Stufe_1 (CM_KLh_SIH_Stufe_hr_Cx1_Stufe_1), 2=Cx2_Stufe_2 (CM_KLh_SIH_Stufe_hr_Cx2_Stufe_2), 3=Cx3_Stufe_3 (CM_KLh_SIH_Stufe_hr_Cx3_Stufe_3), 4=Cx4_Stufe_4 (CM_KLh_SIH_Stufe_hr_Cx4_Stufe_4), 5=Cx5_Stufe_5 (CM_KLh_SIH_Stufe_hr_Cx5_Stufe_5), 6=Cx6_Stufe_6 (CM_KLh_SIH_Stufe_hr_Cx6_Stufe_6)}, range raw 0..6, transfer-property=TRIGGERED-ON-CHANGE-WITHOUT-REPETITION  # Aktive Stufe Sitzheizung Heck rechts, auf deren Basis die Sitzheizungsmatten bestromt werden. Bei dreistufigen Sitzheizungen wird Stufe 0/2/4/6 verwendet.
          signal KL_SL_Soll_hl_XIX_Klima_hinten_04_XIX_E3V_EVCANFD: start 57, 3 bit, little-endian, data-type-policy=OVERRIDE, i-signal-type=PRIMITIVE, init-value=0, base-type=BT_KL_SL_Soll_hl, compu {0=Cx0_Stufe_0 (CM_KL_SL_Soll_hl_Cx0_Stufe_0), 1=Cx1_Stufe_1 (CM_KL_SL_Soll_hl_Cx1_Stufe_1), 2=Cx2_Stufe_2 (CM_KL_SL_Soll_hl_Cx2_Stufe_2), 3=Cx3_Stufe_3 (CM_KL_SL_Soll_hl_Cx3_Stufe_3), 4=Cx4_Stufe_4 (CM_KL_SL_Soll_hl_Cx4_Stufe_4), 5=Cx5_Stufe_5 (CM_KL_SL_Soll_hl_Cx5_Stufe_5), 6=Cx6_Stufe_6 (CM_KL_SL_Soll_hl_Cx6_Stufe_6)}, range raw 0..6, transfer-property=TRIGGERED-ON-CHANGE-WITHOUT-REPETITION  # Einstellung Sitzlüftung hinten links (0...6)
          signal KL_SL_Soll_hr_XIX_Klima_hinten_04_XIX_E3V_EVCANFD: start 60, 3 bit, little-endian, data-type-policy=OVERRIDE, i-signal-type=PRIMITIVE, init-value=0, base-type=BT_KL_SL_Soll_hr, compu {0=Cx0_Stufe_0 (CM_KL_SL_Soll_hr_Cx0_Stufe_0), 1=Cx1_Stufe_1 (CM_KL_SL_Soll_hr_Cx1_Stufe_1), 2=Cx2_Stufe_2 (CM_KL_SL_Soll_hr_Cx2_Stufe_2), 3=Cx3_Stufe_3 (CM_KL_SL_Soll_hr_Cx3_Stufe_3), 4=Cx4_Stufe_4 (CM_KL_SL_Soll_hr_Cx4_Stufe_4), 5=Cx5_Stufe_5 (CM_KL_SL_Soll_hr_Cx5_Stufe_5), 6=Cx6_Stufe_6 (CM_KL_SL_Soll_hr_Cx6_Stufe_6)}, range raw 0..6, transfer-property=TRIGGERED-ON-CHANGE-WITHOUT-REPETITION  # Einstellung Sitzlüftung hinten rechts (0...6)
          signal KLhs_02_alt_XIX_Klima_hinten_04_XIX_E3V_EVCANFD: start 63, 1 bit, little-endian, data-type-policy=OVERRIDE, i-signal-type=PRIMITIVE, init-value=1, base-type=BT_KLhs_02_alt, compu {0=Cx0_aktuell (CM_KLhs_02_alt_Cx0_aktuell), 1=Cx1_veraltet (CM_KLhs_02_alt_Cx1_veraltet)}, range raw 0..1, transfer-property=PENDING  # Veraltet Bit für die LIN-Botschaft KLhs_02
      frame Klima_SDA_01_XIX_E3V_EVCANFD: id 0x1A555590, from Klima, frame-length=8, can-addressing-mode=EXTENDED, can-frame-rx-behavior=CAN-FD, can-frame-tx-behavior=CAN-FD
        pdu Klima_SDA_01_XIX_E3V_EVCANFD: length=8, transmission-mode-true-timing=cyclic-timing={time-offset=0.0, time-period=1.0}, unused-bit-pattern=0
          signal KL_SDA_Sonderfunktionen_Sprache_XIX_Klima_SDA_01_XIX_E3V_EVCANFD: start 0, 5 bit, little-endian, data-type-policy=OVERRIDE, i-signal-type=PRIMITIVE, init-value=30, base-type=BT_KL_SDA_Sonderfunktionen_Sprache, invalid-value=Invalid_KL_SDA_Sonderfunktionen_Sprache_XIX_Klima_SDA_01_XIX_E3V_EVCANFD:31, compu {0=Cx0_Befehl_1 (CM_KL_SDA_Sonderfunktionen_Sprache_Cx0_Befehl_1), 1=Cx1_Befehl_2 (CM_KL_SDA_Sonderfunktionen_Sprache_Cx1_Befehl_2), 2=Cx2_Befehl_3 (CM_KL_SDA_Sonderfunktionen_Sprache_Cx2_Befehl_3), 3=Cx3_Befehl_4 (CM_KL_SDA_Sonderfunktionen_Sprache_Cx3_Befehl_4), 4=Cx4_Befehl_5 (CM_KL_SDA_Sonderfunktionen_Sprache_Cx4_Befehl_5), 5=Cx5_Befehl_6 (CM_KL_SDA_Sonderfunktionen_Sprache_Cx5_Befehl_6), 6=Cx6_Befehl_7 (CM_KL_SDA_Sonderfunktionen_Sprache_Cx6_Befehl_7), 7=Cx7_Befehl_8 (CM_KL_SDA_Sonderfunktionen_Sprache_Cx7_Befehl_8), 8=Cx8_Befehl_9 (CM_KL_SDA_Sonderfunktionen_Sprache_Cx8_Befehl_9), 9=Cx9_Befehl_10 (CM_KL_SDA_Sonderfunktionen_Sprache_Cx9_Befehl_10), 10=Cxa_Befehl_11 (CM_KL_SDA_Sonderfunktionen_Sprache_Cxa_Befehl_11), 11=Cxb_Befehl_12 (CM_KL_SDA_Sonderfunktionen_Sprache_Cxb_Befehl_12), 12=Cxc_Befehl_13 (CM_KL_SDA_Sonderfunktionen_Sprache_Cxc_Befehl_13), 13=Cxd_Befehl_14 (CM_KL_SDA_Sonderfunktionen_Sprache_Cxd_Befehl_14), 14=Cxe_Befehl_15 (CM_KL_SDA_Sonderfunktionen_Sprache_Cxe_Befehl_15), 15=Cxf_Befehl_16 (CM_KL_SDA_Sonderfunktionen_Sprache_Cxf_Befehl_16), 16=Cx10_Befehl_17 (CM_KL_SDA_Sonderfunktionen_Sprache_Cx10_Befehl_17), 17=Cx11_Befehl_18 (CM_KL_SDA_Sonderfunktionen_Sprache_Cx11_Befehl_18), 18=Cx12_Befehl_19 (CM_KL_SDA_Sonderfunktionen_Sprache_Cx12_Befehl_19), 19=Cx13_Befehl_20 (CM_KL_SDA_Sonderfunktionen_Sprache_Cx13_Befehl_20), 20=Cx14_Befehl_21 (CM_KL_SDA_Sonderfunktionen_Sprache_Cx14_Befehl_21), 21=Cx15_Befehl_22 (CM_KL_SDA_Sonderfunktionen_Sprache_Cx15_Befehl_22), 22=Cx16_Befehl_23 (CM_KL_SDA_Sonderfunktionen_Sprache_Cx16_Befehl_23), 23=Cx17_Befehl_24 (CM_KL_SDA_Sonderfunktionen_Sprache_Cx17_Befehl_24), 24=Cx18_Befehl_25 (CM_KL_SDA_Sonderfunktionen_Sprache_Cx18_Befehl_25), 25=Cx19_Befehl_26 (CM_KL_SDA_Sonderfunktionen_Sprache_Cx19_Befehl_26), 26=Cx1a_Befehl_27 (CM_KL_SDA_Sonderfunktionen_Sprache_Cx1a_Befehl_27), 27=Cx1b_Befehl_28 (CM_KL_SDA_Sonderfunktionen_Sprache_Cx1b_Befehl_28), 28=Cx1c_Befehl_29 (CM_KL_SDA_Sonderfunktionen_Sprache_Cx1c_Befehl_29), 29=Cx1d_Befehl_30 (CM_KL_SDA_Sonderfunktionen_Sprache_Cx1d_Befehl_30), 30=Cx1e_Init (CM_KL_SDA_Sonderfunktionen_Sprache_Cx1e_Init), 31=Cx1f_Fehler (CM_KL_SDA_Sonderfunktionen_Sprache_Cx1f_Fehler)}, range raw 0..31, transfer-property=PENDING  # Sprachbefehle und Funktionen für Klimasteuerung
          signal KL_SDA_Menutaste_XIX_Klima_SDA_01_XIX_E3V_EVCANFD: start 5, 1 bit, little-endian, data-type-policy=OVERRIDE, i-signal-type=PRIMITIVE, init-value=0, base-type=BT_KL_SDA_Menutaste, compu {0=Cx0_nicht_aktiv (CM_KL_SDA_Menutaste_Cx0_nicht_aktiv), 1=Cx1_aktiv (CM_KL_SDA_Menutaste_Cx1_aktiv)}, range raw 0..1, transfer-property=PENDING  # Tasten Status
          signal KL_SDA_Luft_Qualitaet_XIX_Klima_SDA_01_XIX_E3V_EVCANFD: start 6, 4 bit, little-endian, data-type-policy=OVERRIDE, i-signal-type=PRIMITIVE, init-value=14, base-type=BT_KL_SDA_Luft_Qualitaet, invalid-value=Invalid_KL_SDA_Luft_Qualitaet_XIX_Klima_SDA_01_XIX_E3V_EVCANFD:15, compu {0=Cx0_Level0 (CM_KL_SDA_Luft_Qualitaet_Cx0_Level0), 1=Cx1_Level1 (CM_KL_SDA_Luft_Qualitaet_Cx1_Level1), 2=Cx2_Level2 (CM_KL_SDA_Luft_Qualitaet_Cx2_Level2), 3=Cx3_Level3 (CM_KL_SDA_Luft_Qualitaet_Cx3_Level3), 4=Cx4_Level4 (CM_KL_SDA_Luft_Qualitaet_Cx4_Level4), 5=Cx5_Level5 (CM_KL_SDA_Luft_Qualitaet_Cx5_Level5), 6=Cx6_Level6 (CM_KL_SDA_Luft_Qualitaet_Cx6_Level6), 7=Cx7_Level7 (CM_KL_SDA_Luft_Qualitaet_Cx7_Level7), 8=Cx8_Level8 (CM_KL_SDA_Luft_Qualitaet_Cx8_Level8), 9=Cx9_Level9 (CM_KL_SDA_Luft_Qualitaet_Cx9_Level9), 10=Cxa_Level10 (CM_KL_SDA_Luft_Qualitaet_Cxa_Level10), 13=Cxd_nicht_verbaut (CM_KL_SDA_Luft_Qualitaet_Cxd_nicht_verbaut), 14=Cxe_Init (CM_KL_SDA_Luft_Qualitaet_Cxe_Init), 15=Cxf_Fehler (CM_KL_SDA_Luft_Qualitaet_Cxf_Fehler)}, range raw 0..15, transfer-property=PENDING  # Qualität der Luft
          signal KL_SDA_Luft_Feinstaub_XIX_Klima_SDA_01_XIX_E3V_EVCANFD: start 10, 8 bit, little-endian, data-type-policy=OVERRIDE, i-signal-type=PRIMITIVE, init-value=254, base-type=BT_KL_SDA_Luft_Feinstaub, invalid-value=Invalid_KL_SDA_Luft_Feinstaub_XIX_Klima_SDA_01_XIX_E3V_EVCANFD:255, compu {phys=raw*5 for raw 0..240, 254=Cxfe_Init (CM_KL_SDA_Luft_Feinstaub_Cxfe_Init), 255=Cxff_Fehler (CM_KL_SDA_Luft_Feinstaub_Cxff_Fehler)}, range phys 0..1200, raw 0..255, transfer-property=PENDING  # Feinstaubbelastung der Luft (ug/m3)
          signal KL_SDA_AQS_VOZBereich_XIX_Klima_SDA_01_XIX_E3V_EVCANFD: start 18, 2 bit, little-endian, data-type-policy=OVERRIDE, i-signal-type=PRIMITIVE, init-value=0, base-type=BT_KL_SDA_AQS_VOZBereich, compu {0=Cx0_Messbereich_0 (CM_KL_SDA_AQS_VOZBereich_Cx0_Messbereich_0), 1=Cx1_Messbereich_1 (CM_KL_SDA_AQS_VOZBereich_Cx1_Messbereich_1), 2=Cx2_Messbereich_2 (CM_KL_SDA_AQS_VOZBereich_Cx2_Messbereich_2), 3=Cx3_Messbereich_3 (CM_KL_SDA_AQS_VOZBereich_Cx3_Messbereich_3)}, range raw 0..3, transfer-property=PENDING  # VOZ-Bereich (Alle Werte möglich, auch in der INIT-Phase)
          signal KL_SDA_AQS_Traffic_XIX_Klima_SDA_01_XIX_E3V_EVCANFD: start 20, 2 bit, little-endian, data-type-policy=OVERRIDE, i-signal-type=PRIMITIVE, init-value=0, base-type=BT_KL_SDA_AQS_Traffic, compu {0=Cx0_unbekannt (CM_KL_SDA_AQS_Traffic_Cx0_unbekannt), 1=Cx1_City_Mode (CM_KL_SDA_AQS_Traffic_Cx1_City_Mode), 2=Cx2_Country_Mode (CM_KL_SDA_AQS_Traffic_Cx2_Country_Mode), 3=Cx3_Highway_Mode (CM_KL_SDA_AQS_Traffic_Cx3_Highway_Mode)}, range raw 0..3, transfer-property=PENDING  # Rückgegebener Wert des Signals Navigationsattribute des Frames AQSe
          signal KL_SDA_AQS_NoxBereich_XIX_Klima_SDA_01_XIX_E3V_EVCANFD: start 22, 2 bit, little-endian, data-type-policy=OVERRIDE, i-signal-type=PRIMITIVE, init-value=0, base-type=BT_KL_SDA_AQS_NoxBereich, compu {0=Cx0_Messbereich_0 (CM_KL_SDA_AQS_NoxBereich_Cx0_Messbereich_0), 1=Cx1_Messbereich_1 (CM_KL_SDA_AQS_NoxBereich_Cx1_Messbereich_1), 2=Cx2_Messbereich_2 (CM_KL_SDA_AQS_NoxBereich_Cx2_Messbereich_2), 3=Cx3_Messbereich_3 (CM_KL_SDA_AQS_NoxBereich_Cx3_Messbereich_3)}, range raw 0..3, transfer-property=PENDING  # Nox-Bereich (Alle Werte möglich, auch in der INIT-Phase)
          signal KL_SDA_AQS_COBereich_XIX_Klima_SDA_01_XIX_E3V_EVCANFD: start 24, 2 bit, little-endian, data-type-policy=OVERRIDE, i-signal-type=PRIMITIVE, init-value=0, base-type=BT_KL_SDA_AQS_COBereich, compu {0=Cx0_Messbereich_0 (CM_KL_SDA_AQS_COBereich_Cx0_Messbereich_0), 1=Cx1_Messbereich_1 (CM_KL_SDA_AQS_COBereich_Cx1_Messbereich_1), 2=Cx2_Messbereich_2 (CM_KL_SDA_AQS_COBereich_Cx2_Messbereich_2), 3=Cx3_Messbereich_3 (CM_KL_SDA_AQS_COBereich_Cx3_Messbereich_3)}, range raw 0..3, transfer-property=PENDING  # CO-Bereich (Alle Werte möglich, auch in der INIT-Phase)
          signal KL_SDA_AQS_COStatus_XIX_Klima_SDA_01_XIX_E3V_EVCANFD: start 26, 4 bit, little-endian, data-type-policy=OVERRIDE, i-signal-type=PRIMITIVE, init-value=0, base-type=BT_KL_SDA_AQS_COStatus, invalid-value=Invalid_KL_SDA_AQS_COStatus_XIX_Klima_SDA_01_XIX_E3V_EVCANFD:15, compu {0=Cx0_nicht_aktiv (CM_KL_SDA_AQS_COStatus_Cx0_nicht_aktiv), 1=Cx1_Luftguetestufe_1 (CM_KL_SDA_AQS_COStatus_Cx1_Luftguetestufe_1), 2=Cx2_Luftguetestufe_2 (CM_KL_SDA_AQS_COStatus_Cx2_Luftguetestufe_2), 3=Cx3_Luftguetestufe_3 (CM_KL_SDA_AQS_COStatus_Cx3_Luftguetestufe_3), 4=Cx4_Luftguetestufe_4 (CM_KL_SDA_AQS_COStatus_Cx4_Luftguetestufe_4), 5=Cx5_Luftguetestufe_5 (CM_KL_SDA_AQS_COStatus_Cx5_Luftguetestufe_5), 6=Cx6_Luftguetestufe_6 (CM_KL_SDA_AQS_COStatus_Cx6_Luftguetestufe_6), 7=Cx7_Luftguetestufe_7 (CM_KL_SDA_AQS_COStatus_Cx7_Luftguetestufe_7), 8=Cx8_Luftguetestufe_8 (CM_KL_SDA_AQS_COStatus_Cx8_Luftguetestufe_8), 9=Cx9_Luftguetestufe_9 (CM_KL_SDA_AQS_COStatus_Cx9_Luftguetestufe_9), 10=Cxa_Luftguetestufe_10 (CM_KL_SDA_AQS_COStatus_Cxa_Luftguetestufe_10), 15=Cxf_Fehler (CM_KL_SDA_AQS_COStatus_Cxf_Fehler)}, range raw 0..15, transfer-property=PENDING  # Luftgütestufe
          signal KL_SDA_AQS_NoxStatus_XIX_Klima_SDA_01_XIX_E3V_EVCANFD: start 30, 4 bit, little-endian, data-type-policy=OVERRIDE, i-signal-type=PRIMITIVE, init-value=0, base-type=BT_KL_SDA_AQS_NoxStatus, invalid-value=Invalid_KL_SDA_AQS_NoxStatus_XIX_Klima_SDA_01_XIX_E3V_EVCANFD:15, compu {0=Cx0_nicht_aktiv (CM_KL_SDA_AQS_NoxStatus_Cx0_nicht_aktiv), 1=Cx1_Luftguetestufe_1 (CM_KL_SDA_AQS_NoxStatus_Cx1_Luftguetestufe_1), 2=Cx2_Luftguetestufe_2 (CM_KL_SDA_AQS_NoxStatus_Cx2_Luftguetestufe_2), 3=Cx3_Luftguetestufe_3 (CM_KL_SDA_AQS_NoxStatus_Cx3_Luftguetestufe_3), 4=Cx4_Luftguetestufe_4 (CM_KL_SDA_AQS_NoxStatus_Cx4_Luftguetestufe_4), 5=Cx5_Luftguetestufe_5 (CM_KL_SDA_AQS_NoxStatus_Cx5_Luftguetestufe_5), 6=Cx6_Luftguetestufe_6 (CM_KL_SDA_AQS_NoxStatus_Cx6_Luftguetestufe_6), 7=Cx7_Luftguetestufe_7 (CM_KL_SDA_AQS_NoxStatus_Cx7_Luftguetestufe_7), 8=Cx8_Luftguetestufe_8 (CM_KL_SDA_AQS_NoxStatus_Cx8_Luftguetestufe_8), 9=Cx9_Luftguetestufe_9 (CM_KL_SDA_AQS_NoxStatus_Cx9_Luftguetestufe_9), 10=Cxa_Luftguetestufe_10 (CM_KL_SDA_AQS_NoxStatus_Cxa_Luftguetestufe_10), 15=Cxf_Fehler (CM_KL_SDA_AQS_NoxStatus_Cxf_Fehler)}, range raw 0..15, transfer-property=PENDING  # Ist die Luftgüte "Init", ist der AQS-Nox-Status auf "nicht geschaltet" (Wert 0). Im Anschluß sind die Werte 0 bis 10 für normale Luftgütestufen in Abhänigkeit der Außenluft. Wert 15 für Nox- Sensor- Fehler ist z. Zt. nicht implementiert.
          signal KL_SDA_AQS_VOZStatus_XIX_Klima_SDA_01_XIX_E3V_EVCANFD: start 34, 4 bit, little-endian, data-type-policy=OVERRIDE, i-signal-type=PRIMITIVE, init-value=0, base-type=BT_KL_SDA_AQS_VOZStatus, invalid-value=Invalid_KL_SDA_AQS_VOZStatus_XIX_Klima_SDA_01_XIX_E3V_EVCANFD:15, compu {0=Cx0_nicht_aktiv (CM_KL_SDA_AQS_VOZStatus_Cx0_nicht_aktiv), 1=Cx1_Luftguetestufe_1 (CM_KL_SDA_AQS_VOZStatus_Cx1_Luftguetestufe_1), 2=Cx2_Luftguetestufe_2 (CM_KL_SDA_AQS_VOZStatus_Cx2_Luftguetestufe_2), 3=Cx3_Luftguetestufe_3 (CM_KL_SDA_AQS_VOZStatus_Cx3_Luftguetestufe_3), 4=Cx4_Luftguetestufe_4 (CM_KL_SDA_AQS_VOZStatus_Cx4_Luftguetestufe_4), 5=Cx5_Luftguetestufe_5 (CM_KL_SDA_AQS_VOZStatus_Cx5_Luftguetestufe_5), 6=Cx6_Luftguetestufe_6 (CM_KL_SDA_AQS_VOZStatus_Cx6_Luftguetestufe_6), 7=Cx7_Luftguetestufe_7 (CM_KL_SDA_AQS_VOZStatus_Cx7_Luftguetestufe_7), 8=Cx8_Luftguetestufe_8 (CM_KL_SDA_AQS_VOZStatus_Cx8_Luftguetestufe_8), 9=Cx9_Luftguetestufe_9 (CM_KL_SDA_AQS_VOZStatus_Cx9_Luftguetestufe_9), 10=Cxa_Luftguetestufe_10 (CM_KL_SDA_AQS_VOZStatus_Cxa_Luftguetestufe_10), 15=Cxf_Fehler (CM_KL_SDA_AQS_VOZStatus_Cxf_Fehler)}, range raw 0..15, transfer-property=PENDING  # VOZ Status Information
          signal KL_SDA_Klima_Automatik_XIX_Klima_SDA_01_XIX_E3V_EVCANFD: start 38, 1 bit, little-endian, data-type-policy=OVERRIDE, i-signal-type=PRIMITIVE, init-value=0, base-type=BT_KL_SDA_Klima_Automatik, compu {0=Cx0_nicht_aktiv (CM_KL_SDA_Klima_Automatik_Cx0_nicht_aktiv), 1=Cx1_aktiv (CM_KL_SDA_Klima_Automatik_Cx1_aktiv)}, range raw 0..1, transfer-property=PENDING  # Status Schalter Klimaautomatik (aus/an)
          signal KL_SDA_Luftverteilung_Person_XIX_Klima_SDA_01_XIX_E3V_EVCANFD: start 39, 1 bit, little-endian, data-type-policy=OVERRIDE, i-signal-type=PRIMITIVE, init-value=0, base-type=BT_KL_SDA_Luftverteilung_Person, compu {0=Cx0_nicht_aktiv (CM_KL_SDA_Luftverteilung_Person_Cx0_nicht_aktiv), 1=Cx1_aktiv (CM_KL_SDA_Luftverteilung_Person_Cx1_aktiv)}, range raw 0..1, transfer-property=PENDING  # Status Luftverteilung Amaturenbrett
          signal KL_SDA_Luftverteilung_Scheibe_XIX_Klima_SDA_01_XIX_E3V_EVCANFD: start 40, 1 bit, little-endian, data-type-policy=OVERRIDE, i-signal-type=PRIMITIVE, init-value=0, base-type=BT_KL_SDA_Luftverteilung_Scheibe, compu {0=Cx0_nicht_aktiv (CM_KL_SDA_Luftverteilung_Scheibe_Cx0_nicht_aktiv), 1=Cx1_aktiv (CM_KL_SDA_Luftverteilung_Scheibe_Cx1_aktiv)}, range raw 0..1, transfer-property=PENDING  # Status Luftverteilung auf die Frontscheibe
          signal KL_SDA_Luftverteilung_Unten_XIX_Klima_SDA_01_XIX_E3V_EVCANFD: start 41, 1 bit, little-endian, data-type-policy=OVERRIDE, i-signal-type=PRIMITIVE, init-value=0, base-type=BT_KL_SDA_Luftverteilung_Unten, compu {0=Cx0_nicht_aktiv (CM_KL_SDA_Luftverteilung_Unten_Cx0_nicht_aktiv), 1=Cx1_aktiv (CM_KL_SDA_Luftverteilung_Unten_Cx1_aktiv)}, range raw 0..1, transfer-property=PENDING  # Status Luftverteilung Fußraum
          signal KL_SDA_Sitzheizung_VL_XIX_Klima_SDA_01_XIX_E3V_EVCANFD: start 42, 2 bit, little-endian, data-type-policy=OVERRIDE, i-signal-type=PRIMITIVE, init-value=0, base-type=BT_KL_SDA_Sitzheizung_VL, compu {0=Cx0_nicht_aktiv (CM_KL_SDA_Sitzheizung_VL_Cx0_nicht_aktiv), 1=Cx1_Stufe_1 (CM_KL_SDA_Sitzheizung_VL_Cx1_Stufe_1), 2=Cx2_Stufe_2 (CM_KL_SDA_Sitzheizung_VL_Cx2_Stufe_2), 3=Cx3_Stufe_3 (CM_KL_SDA_Sitzheizung_VL_Cx3_Stufe_3)}, range raw 0..3, transfer-property=PENDING  # Intensität der Sitzheizung des Fahrersitzes.
          signal KL_SDA_Sitzheizung_VR_XIX_Klima_SDA_01_XIX_E3V_EVCANFD: start 44, 2 bit, little-endian, data-type-policy=OVERRIDE, i-signal-type=PRIMITIVE, init-value=0, base-type=BT_KL_SDA_Sitzheizung_VR, compu {0=Cx0_nicht_aktiv (CM_KL_SDA_Sitzheizung_VR_Cx0_nicht_aktiv), 1=Cx1_Stufe_1 (CM_KL_SDA_Sitzheizung_VR_Cx1_Stufe_1), 2=Cx2_Stufe_2 (CM_KL_SDA_Sitzheizung_VR_Cx2_Stufe_2), 3=Cx3_Stufe_3 (CM_KL_SDA_Sitzheizung_VR_Cx3_Stufe_3)}, range raw 0..3, transfer-property=PENDING  # Intensität der Sitzheizung des Beifahrersitzes.
          signal KL_SDA_Sitzlueftung_VL_XIX_Klima_SDA_01_XIX_E3V_EVCANFD: start 46, 2 bit, little-endian, data-type-policy=OVERRIDE, i-signal-type=PRIMITIVE, init-value=0, base-type=BT_KL_SDA_Sitzlueftung_VL, compu {0=Cx0_nicht_aktiv (CM_KL_SDA_Sitzlueftung_VL_Cx0_nicht_aktiv), 1=Cx1_Stufe_1 (CM_KL_SDA_Sitzlueftung_VL_Cx1_Stufe_1), 2=Cx2_Stufe_2 (CM_KL_SDA_Sitzlueftung_VL_Cx2_Stufe_2), 3=Cx3_Stufe_3 (CM_KL_SDA_Sitzlueftung_VL_Cx3_Stufe_3)}, range raw 0..3, transfer-property=PENDING  # Intensität der Sitzlüftung des Fahrersitzes.
          signal KL_SDA_Sitzlueftung_VR_XIX_Klima_SDA_01_XIX_E3V_EVCANFD: start 48, 2 bit, little-endian, data-type-policy=OVERRIDE, i-signal-type=PRIMITIVE, init-value=0, base-type=BT_KL_SDA_Sitzlueftung_VR, compu {0=Cx0_nicht_aktiv (CM_KL_SDA_Sitzlueftung_VR_Cx0_nicht_aktiv), 1=Cx1_Stufe_1 (CM_KL_SDA_Sitzlueftung_VR_Cx1_Stufe_1), 2=Cx2_Stufe_2 (CM_KL_SDA_Sitzlueftung_VR_Cx2_Stufe_2), 3=Cx3_Stufe_3 (CM_KL_SDA_Sitzlueftung_VR_Cx3_Stufe_3)}, range raw 0..3, transfer-property=PENDING  # Intensität der Sitzlüftung des Beifahrersitzes.
          signal KL_SDA_Sonderfkt_AirCare_XIX_Klima_SDA_01_XIX_E3V_EVCANFD: start 50, 1 bit, little-endian, data-type-policy=OVERRIDE, i-signal-type=PRIMITIVE, init-value=0, base-type=BT_KL_SDA_Sonderfkt_AirCare, compu {0=Cx0_nicht_aktiv (CM_KL_SDA_Sonderfkt_AirCare_Cx0_nicht_aktiv), 1=Cx1_aktiv (CM_KL_SDA_Sonderfkt_AirCare_Cx1_aktiv)}, range raw 0..1, transfer-property=PENDING  # Status Schalter Klimaregulierung aktiv/nicht aktiv.
          signal KL_SDA_Sonderfkt_HSH_XIX_Klima_SDA_01_XIX_E3V_EVCANFD: start 51, 1 bit, little-endian, data-type-policy=OVERRIDE, i-signal-type=PRIMITIVE, init-value=0, base-type=BT_KL_SDA_Sonderfkt_HSH, compu {0=Cx0_nicht_aktiv (CM_KL_SDA_Sonderfkt_HSH_Cx0_nicht_aktiv), 1=Cx1_aktiv (CM_KL_SDA_Sonderfkt_HSH_Cx1_aktiv)}, range raw 0..1, transfer-property=PENDING  # Status Schalter Scheibenheizung der Heckscheibe aktiv/nicht aktiv.
          signal KL_SDA_Sonderfkt_MaxAC_XIX_Klima_SDA_01_XIX_E3V_EVCANFD: start 52, 1 bit, little-endian, data-type-policy=OVERRIDE, i-signal-type=PRIMITIVE, init-value=0, base-type=BT_KL_SDA_Sonderfkt_MaxAC, compu {0=Cx0_nicht_aktiv (CM_KL_SDA_Sonderfkt_MaxAC_Cx0_nicht_aktiv), 1=Cx1_aktiv (CM_KL_SDA_Sonderfkt_MaxAC_Cx1_aktiv)}, range raw 0..1, transfer-property=PENDING  # Status Schalter maximale Klimaregulierung aktiv/nicht aktiv.
          signal KL_SDA_Sonderfkt_MaxDefrost_XIX_Klima_SDA_01_XIX_E3V_EVCANFD: start 53, 1 bit, little-endian, data-type-policy=OVERRIDE, i-signal-type=PRIMITIVE, init-value=0, base-type=BT_KL_SDA_Sonderfkt_MaxDefrost, compu {0=Cx0_nicht_aktiv (CM_KL_SDA_Sonderfkt_MaxDefrost_Cx0_nicht_aktiv), 1=Cx1_aktiv (CM_KL_SDA_Sonderfkt_MaxDefrost_Cx1_aktiv)}, range raw 0..1, transfer-property=PENDING  # Status Schalter maximaler Defrost aktiv/nicht aktiv.
          signal KL_SDA_Temp_Kundenwunsch_2_XIX_Klima_SDA_01_XIX_E3V_EVCANFD: start 54, 5 bit, little-endian, data-type-policy=OVERRIDE, i-signal-type=PRIMITIVE, init-value=16, base-type=BT_KL_SDA_Temp_Kundenwunsch_2, compu {0=Cx0_Min (CM_KL_SDA_Temp_Kundenwunsch_2_Cx0_Min), 1=Cx1_Stufe_1 (CM_KL_SDA_Temp_Kundenwunsch_2_Cx1_Stufe_1), 2=Cx2_Stufe_2 (CM_KL_SDA_Temp_Kundenwunsch_2_Cx2_Stufe_2), 3=Cx3_Stufe_3 (CM_KL_SDA_Temp_Kundenwunsch_2_Cx3_Stufe_3), 4=Cx4_Stufe_4 (CM_KL_SDA_Temp_Kundenwunsch_2_Cx4_Stufe_4), 5=Cx5_Stufe_5 (CM_KL_SDA_Temp_Kundenwunsch_2_Cx5_Stufe_5), 6=Cx6_Stufe_6 (CM_KL_SDA_Temp_Kundenwunsch_2_Cx6_Stufe_6), 7=Cx7_Stufe_7 (CM_KL_SDA_Temp_Kundenwunsch_2_Cx7_Stufe_7), 8=Cx8_Stufe_8 (CM_KL_SDA_Temp_Kundenwunsch_2_Cx8_Stufe_8), 9=Cx9_Stufe_9 (CM_KL_SDA_Temp_Kundenwunsch_2_Cx9_Stufe_9), 10=Cxa_Stufe_10 (CM_KL_SDA_Temp_Kundenwunsch_2_Cxa_Stufe_10), 11=Cxb_Stufe_11 (CM_KL_SDA_Temp_Kundenwunsch_2_Cxb_Stufe_11), 12=Cxc_Stufe_12 (CM_KL_SDA_Temp_Kundenwunsch_2_Cxc_Stufe_12), 13=Cxd_Stufe_13 (CM_KL_SDA_Temp_Kundenwunsch_2_Cxd_Stufe_13), 14=Cxe_Stufe_14 (CM_KL_SDA_Temp_Kundenwunsch_2_Cxe_Stufe_14), 15=Cxf_Stufe_15 (CM_KL_SDA_Temp_Kundenwunsch_2_Cxf_Stufe_15), 16=Cx10_Stufe_16 (CM_KL_SDA_Temp_Kundenwunsch_2_Cx10_Stufe_16), 17=Cx11_Stufe_17 (CM_KL_SDA_Temp_Kundenwunsch_2_Cx11_Stufe_17), 18=Cx12_Stufe_18 (CM_KL_SDA_Temp_Kundenwunsch_2_Cx12_Stufe_18), 19=Cx13_Stufe_19 (CM_KL_SDA_Temp_Kundenwunsch_2_Cx13_Stufe_19), 20=Cx14_Stufe_20 (CM_KL_SDA_Temp_Kundenwunsch_2_Cx14_Stufe_20), 21=Cx15_Stufe_21 (CM_KL_SDA_Temp_Kundenwunsch_2_Cx15_Stufe_21), 22=Cx16_Stufe_22 (CM_KL_SDA_Temp_Kundenwunsch_2_Cx16_Stufe_22), 23=Cx17_Stufe_23 (CM_KL_SDA_Temp_Kundenwunsch_2_Cx17_Stufe_23), 24=Cx18_Stufe_24 (CM_KL_SDA_Temp_Kundenwunsch_2_Cx18_Stufe_24), 25=Cx19_Stufe_25 (CM_KL_SDA_Temp_Kundenwunsch_2_Cx19_Stufe_25), 26=Cx1a_Stufe_26 (CM_KL_SDA_Temp_Kundenwunsch_2_Cx1a_Stufe_26), 27=Cx1b_Stufe_27 (CM_KL_SDA_Temp_Kundenwunsch_2_Cx1b_Stufe_27), 28=Cx1c_Stufe_28 (CM_KL_SDA_Temp_Kundenwunsch_2_Cx1c_Stufe_28), 29=Cx1d_Stufe_29 (CM_KL_SDA_Temp_Kundenwunsch_2_Cx1d_Stufe_29), 30=Cx1e_Stufe_30 (CM_KL_SDA_Temp_Kundenwunsch_2_Cx1e_Stufe_30), 31=Cx1f_Max (CM_KL_SDA_Temp_Kundenwunsch_2_Cx1f_Max)}, range raw 0..31, transfer-property=PENDING  # Eingestellte Solltemperatur des Beifahrers.
          signal KL_SDA_Temp_Kundenwunsch_3_XIX_Klima_SDA_01_XIX_E3V_EVCANFD: start 59, 5 bit, little-endian, data-type-policy=OVERRIDE, i-signal-type=PRIMITIVE, init-value=16, base-type=BT_KL_SDA_Temp_Kundenwunsch_3, compu {0=Cx0_Min (CM_KL_SDA_Temp_Kundenwunsch_3_Cx0_Min), 1=Cx1_Stufe_1 (CM_KL_SDA_Temp_Kundenwunsch_3_Cx1_Stufe_1), 2=Cx2_Stufe_2 (CM_KL_SDA_Temp_Kundenwunsch_3_Cx2_Stufe_2), 3=Cx3_Stufe_3 (CM_KL_SDA_Temp_Kundenwunsch_3_Cx3_Stufe_3), 4=Cx4_Stufe_4 (CM_KL_SDA_Temp_Kundenwunsch_3_Cx4_Stufe_4), 5=Cx5_Stufe_5 (CM_KL_SDA_Temp_Kundenwunsch_3_Cx5_Stufe_5), 6=Cx6_Stufe_6 (CM_KL_SDA_Temp_Kundenwunsch_3_Cx6_Stufe_6), 7=Cx7_Stufe_7 (CM_KL_SDA_Temp_Kundenwunsch_3_Cx7_Stufe_7), 8=Cx8_Stufe_8 (CM_KL_SDA_Temp_Kundenwunsch_3_Cx8_Stufe_8), 9=Cx9_Stufe_9 (CM_KL_SDA_Temp_Kundenwunsch_3_Cx9_Stufe_9), 10=Cxa_Stufe_10 (CM_KL_SDA_Temp_Kundenwunsch_3_Cxa_Stufe_10), 11=Cxb_Stufe_11 (CM_KL_SDA_Temp_Kundenwunsch_3_Cxb_Stufe_11), 12=Cxc_Stufe_12 (CM_KL_SDA_Temp_Kundenwunsch_3_Cxc_Stufe_12), 13=Cxd_Stufe_13 (CM_KL_SDA_Temp_Kundenwunsch_3_Cxd_Stufe_13), 14=Cxe_Stufe_14 (CM_KL_SDA_Temp_Kundenwunsch_3_Cxe_Stufe_14), 15=Cxf_Stufe_15 (CM_KL_SDA_Temp_Kundenwunsch_3_Cxf_Stufe_15), 16=Cx10_Stufe_16 (CM_KL_SDA_Temp_Kundenwunsch_3_Cx10_Stufe_16), 17=Cx11_Stufe_17 (CM_KL_SDA_Temp_Kundenwunsch_3_Cx11_Stufe_17), 18=Cx12_Stufe_18 (CM_KL_SDA_Temp_Kundenwunsch_3_Cx12_Stufe_18), 19=Cx13_Stufe_19 (CM_KL_SDA_Temp_Kundenwunsch_3_Cx13_Stufe_19), 20=Cx14_Stufe_20 (CM_KL_SDA_Temp_Kundenwunsch_3_Cx14_Stufe_20), 21=Cx15_Stufe_21 (CM_KL_SDA_Temp_Kundenwunsch_3_Cx15_Stufe_21), 22=Cx16_Stufe_22 (CM_KL_SDA_Temp_Kundenwunsch_3_Cx16_Stufe_22), 23=Cx17_Stufe_23 (CM_KL_SDA_Temp_Kundenwunsch_3_Cx17_Stufe_23), 24=Cx18_Stufe_24 (CM_KL_SDA_Temp_Kundenwunsch_3_Cx18_Stufe_24), 25=Cx19_Stufe_25 (CM_KL_SDA_Temp_Kundenwunsch_3_Cx19_Stufe_25), 26=Cx1a_Stufe_26 (CM_KL_SDA_Temp_Kundenwunsch_3_Cx1a_Stufe_26), 27=Cx1b_Stufe_27 (CM_KL_SDA_Temp_Kundenwunsch_3_Cx1b_Stufe_27), 28=Cx1c_Stufe_28 (CM_KL_SDA_Temp_Kundenwunsch_3_Cx1c_Stufe_28), 29=Cx1d_Stufe_29 (CM_KL_SDA_Temp_Kundenwunsch_3_Cx1d_Stufe_29), 30=Cx1e_Stufe_30 (CM_KL_SDA_Temp_Kundenwunsch_3_Cx1e_Stufe_30), 31=Cx1f_Max (CM_KL_SDA_Temp_Kundenwunsch_3_Cx1f_Max)}, range raw 0..31, transfer-property=PENDING  # Eingestellte Solltemperatur des Rückbank.
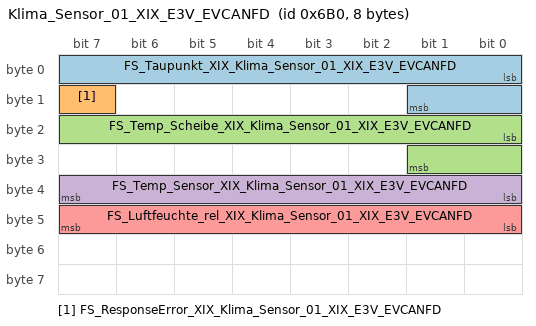
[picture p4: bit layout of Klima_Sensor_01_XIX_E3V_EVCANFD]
      frame Klima_Sensor_01_XIX_E3V_EVCANFD: id 0x6B0, to Klima, frame-length=8, can-addressing-mode=STANDARD, can-frame-rx-behavior=CAN-FD, can-frame-tx-behavior=CAN-FD
        pdu Klima_Sensor_01_XIX_E3V_EVCANFD: length=8, transmission-mode-true-timing=cyclic-timing={time-offset=0.0, time-period=0.5}, unused-bit-pattern=0  # 1:1 LIN-CAN Botschaft, Originalsender ist Regen-/Licht-/Feuchtesensor auf dem BCM-LIN1
          signal FS_Taupunkt_XIX_Klima_Sensor_01_XIX_E3V_EVCANFD: start 0, 10 bit, little-endian, data-type-policy=OVERRIDE, i-signal-type=PRIMITIVE, init-value=0, base-type=BT_FS_Taupunkt, invalid-value=Invalid_FS_Taupunkt_XIX_Klima_Sensor_01_XIX_E3V_EVCANFD:1023, compu {0=Cx0_nicht_verfuegbar (CM_FS_Taupunkt_Cx0_nicht_verfuegbar) (nicht verfuegbar), phys=raw*0.1-39.6 for raw 1..1000, 1023=Cx3ff_Fehler (CM_FS_Taupunkt_Cx3ff_Fehler); unit Unit_DegreCelsi}, range phys -39.5..60.4 Unit_DegreCelsi, raw 0..1023, unit=Unit_DegreCelsi, transfer-property=PENDING, to Klima(timeout 5 s)  # berechneter Taupunkt
          signal FS_ResponseError_XIX_Klima_Sensor_01_XIX_E3V_EVCANFD: start 15, 1 bit, little-endian, data-type-policy=OVERRIDE, i-signal-type=PRIMITIVE, init-value=0, base-type=BT_FS_ResponseError, invalid-value=Invalid_FS_ResponseError_XIX_Klima_Sensor_01_XIX_E3V_EVCANFD:1, compu {0=Cx0_normal (CM_FS_ResponseError_Cx0_normal), 1=Cx1_Fehler (CM_FS_ResponseError_Cx1_Fehler)}, range raw 0..1, transfer-property=PENDING, to Klima(timeout 5 s)  # siehe LIN2.0-Specification (Darf nicht über ein Fehlergueltigkeitsbit abgesichtert werden!)
          signal FS_Temp_Scheibe_XIX_Klima_Sensor_01_XIX_E3V_EVCANFD: start 16, 10 bit, little-endian, data-type-policy=OVERRIDE, i-signal-type=PRIMITIVE, init-value=0, base-type=BT_FS_Temp_Scheibe, invalid-value=Invalid_FS_Temp_Scheibe_XIX_Klima_Sensor_01_XIX_E3V_EVCANFD:1023, compu {0=Cx0_nicht_verfuegbar (CM_FS_Temp_Scheibe_Cx0_nicht_verfuegbar) (nicht verfuegbar), phys=raw*0.1-39.6 for raw 1..1000, 1023=Cx3ff_Fehler (CM_FS_Temp_Scheibe_Cx3ff_Fehler); unit Unit_DegreCelsi}, range phys -39.5..60.4 Unit_DegreCelsi, raw 0..1023, unit=Unit_DegreCelsi, transfer-property=PENDING, to Klima(timeout 5 s)  # gemessene Frontscheibentemperatur
          signal FS_Temp_Sensor_XIX_Klima_Sensor_01_XIX_E3V_EVCANFD: start 32, 8 bit, little-endian, data-type-policy=OVERRIDE, i-signal-type=PRIMITIVE, init-value=0, base-type=BT_FS_Temp_Sensor, invalid-value=Invalid_FS_Temp_Sensor_XIX_Klima_Sensor_01_XIX_E3V_EVCANFD:255, compu {0=Cx0_nicht_verfuegbar (CM_FS_Temp_Sensor_Cx0_nicht_verfuegbar) (nicht verfuegbar), phys=raw*0.5-40 for raw 1..254, 255=Cxff_Fehler (CM_FS_Temp_Sensor_Cxff_Fehler); unit Unit_DegreCelsi}, range phys -39.5..87 Unit_DegreCelsi, raw 0..255, unit=Unit_DegreCelsi, transfer-property=PENDING, to Klima(timeout 5 s)  # gemessene Sensortemperatur
          signal FS_Luftfeuchte_rel_XIX_Klima_Sensor_01_XIX_E3V_EVCANFD: start 40, 8 bit, little-endian, data-type-policy=OVERRIDE, i-signal-type=PRIMITIVE, init-value=0, base-type=BT_FS_Luftfeuchte_rel, invalid-value=Invalid_FS_Luftfeuchte_rel_XIX_Klima_Sensor_01_XIX_E3V_EVCANFD:255, compu {0=Cx0_nicht_verfuegbar (CM_FS_Luftfeuchte_rel_Cx0_nicht_verfuegbar) (nicht verfuegbar), phys=raw*0.5-0.5 for raw 1..201, 255=Cxff_Fehler (CM_FS_Luftfeuchte_rel_Cxff_Fehler); unit Unit_PerCent}, range phys 0..100 Unit_PerCent, raw 0..255, unit=Unit_PerCent, transfer-property=PENDING, to Klima(timeout 5 s)  # gemessene relative Luftfeuchte
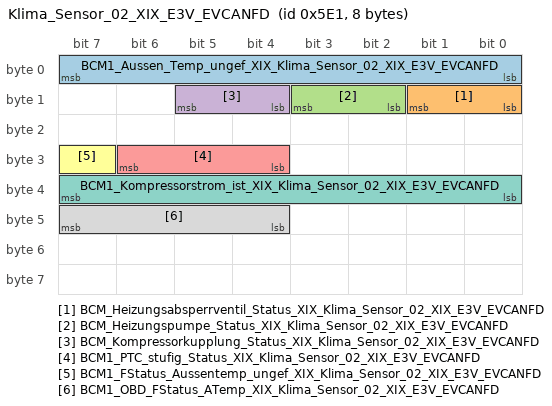
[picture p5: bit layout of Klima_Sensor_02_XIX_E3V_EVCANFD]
      frame Klima_Sensor_02_XIX_E3V_EVCANFD: id 0x5E1, to Klima, frame-length=8, can-addressing-mode=STANDARD, can-frame-rx-behavior=CAN-FD, can-frame-tx-behavior=CAN-FD
        pdu Klima_Sensor_02_XIX_E3V_EVCANFD: length=8, transmission-mode-true-timing=cyclic-timing={time-offset=0.0, time-period=0.2}, unused-bit-pattern=0  # ab MQB 7.3
          signal BCM1_Aussen_Temp_ungef_XIX_Klima_Sensor_02_XIX_E3V_EVCANFD: start 0, 8 bit, little-endian, data-type-policy=OVERRIDE, i-signal-type=PRIMITIVE, init-value=254, base-type=BT_BCM1_Aussen_Temp_ungef, invalid-value=Invalid_BCM1_Aussen_Temp_ungef_XIX_Klima_Sensor_02_XIX_E3V_EVCANFD:255, compu {phys=raw*0.5-50 for raw 0..252, 253=Cxfd_nicht_verbaut (CM_BCM1_Aussen_Temp_ungef_Cxfd_nicht_verbaut), 254=Cxfe_Initwert (CM_BCM1_Aussen_Temp_ungef_Cxfe_Initwert), 255=Cxff_Fehler (CM_BCM1_Aussen_Temp_ungef_Cxff_Fehler); unit Unit_DegreCelsi}, range phys -50..76 Unit_DegreCelsi, raw 0..255, unit=Unit_DegreCelsi, transfer-property=PENDING, to Klima(timeout 2 s)  # ungefilterter Wert des Aussentemperatursensors
          signal BCM_Heizungsabsperrventil_Status_XIX_Klima_Sensor_02_XIX_E3V_EVCANFD: start 8, 2 bit, little-endian, data-type-policy=OVERRIDE, i-signal-type=PRIMITIVE, init-value=2, base-type=BT_BCM_Heizungsabsperrventil_Status, invalid-value=Invalid_BCM_Heizungsabsperrventil_Status_XIX_Klima_Sensor_02_XIX_E3V_EVCANFD:3, compu {0=Cx0_HAV_offen (CM_BCM_Heizungsabsperrventil_Status_Cx0_HAV_offen), 1=Cx1_HAV_geschlossen (CM_BCM_Heizungsabsperrventil_Status_Cx1_HAV_geschlossen), 2=Cx2_Init_oder_nicht_verbaut (CM_BCM_Heizungsabsperrventil_Status_Cx2_Init_oder_nicht_verbaut), 3=Cx3_Fehler (CM_BCM_Heizungsabsperrventil_Status_Cx3_Fehler)}, range raw 0..3, transfer-property=PENDING  # Das Signal beschreibt den Zustand des Heizungsabsperrventils, welches als Portexpander vom BCM1 elektrisch angesteuert wird.
          signal BCM_Heizungspumpe_Status_XIX_Klima_Sensor_02_XIX_E3V_EVCANFD: start 10, 2 bit, little-endian, data-type-policy=OVERRIDE, i-signal-type=PRIMITIVE, init-value=2, base-type=BT_BCM_Heizungspumpe_Status, invalid-value=Invalid_BCM_Heizungspumpe_Status_XIX_Klima_Sensor_02_XIX_E3V_EVCANFD:3, compu {0=Cx0_Pumpe_aus (CM_BCM_Heizungspumpe_Status_Cx0_Pumpe_aus), 1=Cx1_Pumpe_aktiv_und_Stauts_iO (CM_BCM_Heizungspumpe_Status_Cx1_Pumpe_aktiv_und_Stauts_iO), 2=Cx2_Init_oder_nicht_verbaut (CM_BCM_Heizungspumpe_Status_Cx2_Init_oder_nicht_verbaut), 3=Cx3_Fehler (CM_BCM_Heizungspumpe_Status_Cx3_Fehler)}, range raw 0..3, transfer-property=PENDING  # Das Signal beschreibt den Zustand der Heizungspumpe, welche als Portexpander vom BCM1 elektrisch angesteuert wird.
          signal BCM_Kompressorkupplung_Status_XIX_Klima_Sensor_02_XIX_E3V_EVCANFD: start 12, 2 bit, little-endian, data-type-policy=OVERRIDE, i-signal-type=PRIMITIVE, init-value=2, base-type=BT_BCM_Kompressorkupplung_Status, invalid-value=Invalid_BCM_Kompressorkupplung_Status_XIX_Klima_Sensor_02_XIX_E3V_EVCANFD:3, compu {0=Cx0_Kupplung_offen (CM_BCM_Kompressorkupplung_Status_Cx0_Kupplung_offen), 1=Cx1_Kupplung_geschlossen (CM_BCM_Kompressorkupplung_Status_Cx1_Kupplung_geschlossen), 2=Cx2_Init_oder_nicht_verbaut (CM_BCM_Kompressorkupplung_Status_Cx2_Init_oder_nicht_verbaut), 3=Cx3_Fehler (CM_BCM_Kompressorkupplung_Status_Cx3_Fehler)}, range raw 0..3, transfer-property=PENDING  # Das Signal beschreibt den Zustand der Klimakompressorkupplung, welche als Portexpander vom BCM1 elektrisch angesteuert wird.
          signal BCM1_PTC_stufig_Status_XIX_Klima_Sensor_02_XIX_E3V_EVCANFD: start 28, 3 bit, little-endian, data-type-policy=OVERRIDE, i-signal-type=PRIMITIVE, init-value=6, base-type=BT_BCM1_PTC_stufig_Status, invalid-value=Invalid_BCM1_PTC_stufig_Status_XIX_Klima_Sensor_02_XIX_E3V_EVCANFD:7, compu {0=Cx0_Aus (CM_BCM1_PTC_stufig_Status_Cx0_Aus), 1=Cx1_Stufe_1_aktiv (CM_BCM1_PTC_stufig_Status_Cx1_Stufe_1_aktiv), 2=Cx2_Stufe_2_aktiv (CM_BCM1_PTC_stufig_Status_Cx2_Stufe_2_aktiv), 3=Cx3_Stufe_3_aktiv (CM_BCM1_PTC_stufig_Status_Cx3_Stufe_3_aktiv), 6=Cx6_Init_oder_nicht_verbaut (CM_BCM1_PTC_stufig_Status_Cx6_Init_oder_nicht_verbaut), 7=Cx7_Fehler (CM_BCM1_PTC_stufig_Status_Cx7_Fehler)}, range raw 0..7, transfer-property=PENDING  # Status des BCM1-Heizverbrauchers PTC (stufig)
          signal BCM1_FStatus_Aussentemp_ungef_XIX_Klima_Sensor_02_XIX_E3V_EVCANFD: start 31, 1 bit, little-endian, data-type-policy=OVERRIDE, i-signal-type=PRIMITIVE, init-value=1, base-type=BT_BCM1_FStatus_Aussentemp_ungef, compu {0=Cx0_iO (CM_BCM1_FStatus_Aussentemp_ungef_Cx0_iO), 1=Cx1_niO (CM_BCM1_FStatus_Aussentemp_ungef_Cx1_niO)}, range raw 0..1, transfer-property=PENDING, to Klima(timeout 2 s)  # Fehlerstatus für Aussentemperatur (Kombianzeige)
          signal BCM1_Kompressorstrom_ist_XIX_Klima_Sensor_02_XIX_E3V_EVCANFD: start 32, 8 bit, little-endian, data-type-policy=OVERRIDE, i-signal-type=PRIMITIVE, init-value=254, base-type=BT_BCM1_Kompressorstrom_ist, invalid-value=Invalid_BCM1_Kompressorstrom_ist_XIX_Klima_Sensor_02_XIX_E3V_EVCANFD:255, compu {phys=raw*4 for raw 0..250, 254=Cxfe_Init_bzw_nicht_verfuegbar (CM_BCM1_Kompressorstrom_ist_Cxfe_Init_bzw_nicht_verfuegbar) (Init, bzw. nicht verfuegbar), 255=Cxff_Fehler (CM_BCM1_Kompressorstrom_ist_Cxff_Fehler); unit Unit_MilliAmper}, range phys 0..1000 Unit_MilliAmper, raw 0..255, unit=Unit_MilliAmper, transfer-property=PENDING  # IST-Strom vom Klima-Kompressor
          signal BCM1_OBD_FStatus_ATemp_XIX_Klima_Sensor_02_XIX_E3V_EVCANFD: start 44, 4 bit, little-endian, data-type-policy=OVERRIDE, i-signal-type=PRIMITIVE, init-value=0, base-type=BT_BCM1_OBD_FStatus_ATemp, compu {0=Cx0_kein_Fehler_Init_nicht_verbaut (CM_BCM1_OBD_FStatus_ATemp_Cx0_kein_Fehler_Init_nicht_verbaut) (kein Fehler / Init / nicht verbaut), 1=Cx1_KS_Kurzschluss_nach_minus (CM_BCM1_OBD_FStatus_ATemp_Cx1_KS_Kurzschluss_nach_minus) (KS- (Kurzschluss nach minus)), 2=Cx2_KS_Kurzschluss_nach_plus (CM_BCM1_OBD_FStatus_ATemp_Cx2_KS_Kurzschluss_nach_plus) (KS+ (Kurzschluss nach plus)), 3=Cx3_OC_Leitungsunterbrechung (CM_BCM1_OBD_FStatus_ATemp_Cx3_OC_Leitungsunterbrechung) (OC (Leitungsunterbrechung)), 4=Cx4_OOR_Signal_zu_gross (CM_BCM1_OBD_FStatus_ATemp_Cx4_OOR_Signal_zu_gross) (OOR+ (Signal zu gross)), 5=Cx5_OOR_Signal_zu_klein (CM_BCM1_OBD_FStatus_ATemp_Cx5_OOR_Signal_zu_klein) (OOR- (Signal zu klein)), 6=Cx6_RC_Signal_unplausibel_zu_gross (CM_BCM1_OBD_FStatus_ATemp_Cx6_RC_Signal_unplausibel_zu_gross) (RC+ (Signal unplausibel zu gross)), 7=Cx7_RC_Signal_unplausibel_zu_klein (CM_BCM1_OBD_FStatus_ATemp_Cx7_RC_Signal_unplausibel_zu_klein) (RC- (Signal unplausibel zu klein)), 8=Cx8_KS_OC_Kurzschluss_nach_plus_Unterbrechung (CM_BCM1_OBD_FStatus_ATemp_Cx8_KS_OC_Kurzschluss_nach_plus_Unterbrechung) (KS+/OC (Kurzschluss nach plus/Unterbrechung)), 9=Cx9_KS_OC_Kurzschluss_nach_minus_Unterbrechung (CM_BCM1_OBD_FStatus_ATemp_Cx9_KS_OC_Kurzschluss_nach_minus_Unterbrechung) (KS-/OC (Kurzschluss nach minus/Unterbrechung)), 10=Cxa_KS_KS_Kurzschluss_nach_minus_plus (CM_BCM1_OBD_FStatus_ATemp_Cxa_KS_KS_Kurzschluss_nach_minus_plus) (KS-/KS+ (Kurzschluss nach minus/plus)), 11=Cxb_KS_KS_OC_Kurzschluss_nach_minus_plus_Unterbrechung (CM_BCM1_OBD_FStatus_ATemp_Cxb_KS_KS_OC_Kurzschluss_nach_minus_plus_Unterbrechung) (KS-/KS+/OC (Kurzschluss nach minus/plus/Unterbrechung)), 12=Cxc_frei (CM_BCM1_OBD_FStatus_ATemp_Cxc_frei), 13=Cxd_frei (CM_BCM1_OBD_FStatus_ATemp_Cxd_frei), 14=Cxe_frei (CM_BCM1_OBD_FStatus_ATemp_Cxe_frei), 15=Cxf_frei (CM_BCM1_OBD_FStatus_ATemp_Cxf_frei)}, range raw 0..15, transfer-property=PENDING, to Klima(timeout 2 s)  # Fehlerstatus Umgebungstemperatursensor (OBD relevanter Sensor)
      frame Klima_Sensor_03_XIX_E3V_EVCANFD: id 0x6B5, from Klima, frame-length=8, can-addressing-mode=STANDARD, can-frame-rx-behavior=CAN-FD, can-frame-tx-behavior=CAN-FD
        pdu Klima_Sensor_03_XIX_E3V_EVCANFD: length=8, transmission-mode-true-timing=cyclic-timing={time-offset=0.0, time-period=0.5}, unused-bit-pattern=0  # ab D4 gültig -- geänderter Wertebereich und Signalnamen 1:1 LIN-CAN Botschaft vom BCM1, nur bei Kl.15 EIN gesendet
          signal FSA_Taupunkt_XIX_Klima_Sensor_03_XIX_E3V_EVCANFD: start 0, 10 bit, little-endian, data-type-policy=OVERRIDE, i-signal-type=PRIMITIVE, init-value=1022, base-type=BT_FSA_Taupunkt, invalid-value=Invalid_FSA_Taupunkt_XIX_Klima_Sensor_03_XIX_E3V_EVCANFD:1023, compu {phys=raw*0.1-40 for raw 0..1000, 1021=Cx3fd_nicht_verbaut (CM_FSA_Taupunkt_Cx3fd_nicht_verbaut), 1022=Cx3fe_Init (CM_FSA_Taupunkt_Cx3fe_Init), 1023=Cx3ff_Fehler (CM_FSA_Taupunkt_Cx3ff_Fehler); unit Unit_DegreCelsi}, range phys -40..60 Unit_DegreCelsi, raw 0..1023, unit=Unit_DegreCelsi, transfer-property=PENDING  # 'Init' falls nicht verbaut
          signal FSA_Err_Defekt_Tsens_TF_XIX_Klima_Sensor_03_XIX_E3V_EVCANFD: start 10, 1 bit, little-endian, data-type-policy=OVERRIDE, i-signal-type=PRIMITIVE, init-value=0, base-type=BT_FSA_Err_Defekt_Tsens_TF, compu {0=Cx0_inaktiv (CM_FSA_Err_Defekt_Tsens_TF_Cx0_inaktiv), 1=Cx1_aktiv (CM_FSA_Err_Defekt_Tsens_TF_Cx1_aktiv)}, range raw 0..1, transfer-property=PENDING  # OBD TestFailed Flag, Statusbotschaft für diden Feuchtesensor, testFailed (TF)
          signal FSA_Luftfeuchte_TNCTOC_XIX_Klima_Sensor_03_XIX_E3V_EVCANFD: start 11, 1 bit, little-endian, data-type-policy=OVERRIDE, i-signal-type=PRIMITIVE, init-value=1, base-type=BT_FSA_Luftfeuchte_TNCTOC, compu {0=Cx0_Test_Completed_TOC (CM_FSA_Luftfeuchte_TNCTOC_Cx0_Test_Completed_TOC), 1=Cx1_Test_Not_Completed_TOC (CM_FSA_Luftfeuchte_TNCTOC_Cx1_Test_Not_Completed_TOC)}, range raw 0..1, transfer-property=PENDING  # Signal meldet den Status der Diagnosen nach OBD LIN-LAH, testNotCompletedThisOperationCycle (TNCTOC)
          signal FSA_Luftfeuchte_TF_XIX_Klima_Sensor_03_XIX_E3V_EVCANFD: start 12, 1 bit, little-endian, data-type-policy=OVERRIDE, i-signal-type=PRIMITIVE, init-value=0, base-type=BT_FSA_Luftfeuchte_TF, compu {0=Cx0_inaktiv (CM_FSA_Luftfeuchte_TF_Cx0_inaktiv), 1=Cx1_aktiv (CM_FSA_Luftfeuchte_TF_Cx1_aktiv)}, range raw 0..1, transfer-property=PENDING  # OBD TestFailed Flag, Statusbotschaft für den Feuchtesensor, testFailed (TF)
          signal FSA_Err_Unterspannung_TF_XIX_Klima_Sensor_03_XIX_E3V_EVCANFD: start 13, 1 bit, little-endian, data-type-policy=OVERRIDE, i-signal-type=PRIMITIVE, init-value=0, base-type=BT_FSA_Err_Unterspannung_TF, compu {0=Cx0_inaktiv (CM_FSA_Err_Unterspannung_TF_Cx0_inaktiv), 1=Cx1_aktiv (CM_FSA_Err_Unterspannung_TF_Cx1_aktiv)}, range raw 0..1, transfer-property=PENDING  # OBD TestFailed Flag, Statusbotschaft für den Feuchtesensor, testFailed (TF)
          signal FSA_Err_RAMROM_Check_TF_XIX_Klima_Sensor_03_XIX_E3V_EVCANFD: start 14, 1 bit, little-endian, data-type-policy=OVERRIDE, i-signal-type=PRIMITIVE, init-value=0, base-type=BT_FSA_Err_RAMROM_Check_TF, compu {0=Cx0_inaktiv (CM_FSA_Err_RAMROM_Check_TF_Cx0_inaktiv), 1=Cx1_aktiv (CM_FSA_Err_RAMROM_Check_TF_Cx1_aktiv)}, range raw 0..1, transfer-property=PENDING  # OBD TestFailed Flag, Statusbotschaft für den Feuchtesensor, testFailed (TF)
          signal FSA_ResponseError_XIX_Klima_Sensor_03_XIX_E3V_EVCANFD: start 15, 1 bit, little-endian, data-type-policy=OVERRIDE, i-signal-type=PRIMITIVE, init-value=0, base-type=BT_FSA_ResponseError, invalid-value=Invalid_FSA_ResponseError_XIX_Klima_Sensor_03_XIX_E3V_EVCANFD:1, compu {0=Cx0_normal (CM_FSA_ResponseError_Cx0_normal), 1=Cx1_Fehler (CM_FSA_ResponseError_Cx1_Fehler)}, range raw 0..1, transfer-property=PENDING  # siehe LIN2.0-Specification (Darf nicht über ein Fehlergueltigkeitsbit abgesichtert werden!)
          signal FSA_Temp_Luft_XIX_Klima_Sensor_03_XIX_E3V_EVCANFD: start 16, 10 bit, little-endian, data-type-policy=OVERRIDE, i-signal-type=PRIMITIVE, init-value=1022, base-type=BT_FSA_Temp_Luft, invalid-value=Invalid_FSA_Temp_Luft_XIX_Klima_Sensor_03_XIX_E3V_EVCANFD:1023, compu {phys=raw*0.1-40 for raw 0..1010, 1021=Cx3fd_nicht_verbaut (CM_FSA_Temp_Luft_Cx3fd_nicht_verbaut), 1022=Cx3fe_Init (CM_FSA_Temp_Luft_Cx3fe_Init), 1023=Cx3ff_Fehler (CM_FSA_Temp_Luft_Cx3ff_Fehler); unit Unit_DegreCelsi}, range phys -40..61 Unit_DegreCelsi, raw 0..1023, unit=Unit_DegreCelsi, transfer-property=PENDING  # gemessene Temperatur im Luftstrom (z.B. NTC am Sensor) 'Init' falls nicht verbaut (+61°C bedeutet: Temp_Luft > 60,9°C !)
          signal FSA_Err_RAMROM_Check_TNCTOC_XIX_Klima_Sensor_03_XIX_E3V_EVCANFD: start 26, 1 bit, little-endian, data-type-policy=OVERRIDE, i-signal-type=PRIMITIVE, init-value=1, base-type=BT_FSA_Err_RAMROM_Check_TNCTOC, compu {0=Cx0_Test_Completed_TOC (CM_FSA_Err_RAMROM_Check_TNCTOC_Cx0_Test_Completed_TOC), 1=Cx1_Test_Not_Completed_TOC (CM_FSA_Err_RAMROM_Check_TNCTOC_Cx1_Test_Not_Completed_TOC)}, range raw 0..1, transfer-property=PENDING  # Signal meldet den Status der Diagnosen nach OBD LIN-LAH, testNotCompletedThisOperationCycle (TNCTOC)
          signal FSA_Err_Ueberspannung_TF_XIX_Klima_Sensor_03_XIX_E3V_EVCANFD: start 30, 1 bit, little-endian, data-type-policy=OVERRIDE, i-signal-type=PRIMITIVE, init-value=0, base-type=BT_FSA_Err_Ueberspannung_TF, compu {0=Cx0_inaktiv (CM_FSA_Err_Ueberspannung_TF_Cx0_inaktiv), 1=Cx1_aktiv (CM_FSA_Err_Ueberspannung_TF_Cx1_aktiv)}, range raw 0..1, transfer-property=PENDING  # OBD TestFailed Flag, Statusbotschaft für den Feuchtesensor Außen, testFailed (TF)
          signal FSA_Luftfeuchte_rel_XIX_Klima_Sensor_03_XIX_E3V_EVCANFD: start 32, 8 bit, little-endian, data-type-policy=OVERRIDE, i-signal-type=PRIMITIVE, init-value=254, base-type=BT_FSA_Luftfeuchte_rel, invalid-value=Invalid_FSA_Luftfeuchte_rel_XIX_Klima_Sensor_03_XIX_E3V_EVCANFD:255, compu {phys=raw*0.5 for raw 0..252, 253=Cxfd_nicht_verbaut (CM_FSA_Luftfeuchte_rel_Cxfd_nicht_verbaut), 254=Cxfe_Init (CM_FSA_Luftfeuchte_rel_Cxfe_Init), 255=Cxff_Fehler (CM_FSA_Luftfeuchte_rel_Cxff_Fehler); unit Unit_PerCent}, range phys 0..126 Unit_PerCent, raw 0..255, unit=Unit_PerCent, transfer-property=PENDING  # Maximaler Feuchtebereich bis 126% für theoretisch errechnete Feuchtewerte des Sensors. Signalwerte >100% bedeuten rel. Feuchte = 100%
          signal FSA_HW_XIX_Klima_Sensor_03_XIX_E3V_EVCANFD: start 40, 4 bit, little-endian, data-type-policy=OVERRIDE, i-signal-type=PRIMITIVE, init-value=0, base-type=BT_FSA_HW, compu {phys=raw for raw 0..15}, range phys 0..15, raw 0..15, transfer-property=PENDING  # Hardwarestand
          signal FSA_SW_XIX_Klima_Sensor_03_XIX_E3V_EVCANFD: start 44, 4 bit, little-endian, data-type-policy=OVERRIDE, i-signal-type=PRIMITIVE, init-value=0, base-type=BT_FSA_SW, compu {phys=raw for raw 0..15}, range phys 0..15, raw 0..15, transfer-property=PENDING  # Softwarestand
          signal FSA_Temp_Sensor_XIX_Klima_Sensor_03_XIX_E3V_EVCANFD: start 48, 11 bit, little-endian, data-type-policy=OVERRIDE, i-signal-type=PRIMITIVE, init-value=2046, base-type=BT_FSA_Temp_Sensor, invalid-value=Invalid_FSA_Temp_Sensor_XIX_Klima_Sensor_03_XIX_E3V_EVCANFD:2047, compu {phys=raw*0.1-40 for raw 0..1300, 2045=Cx7fd_nicht_verbaut (CM_FSA_Temp_Sensor_Cx7fd_nicht_verbaut), 2046=Cx7fe_Init (CM_FSA_Temp_Sensor_Cx7fe_Init), 2047=Cx7ff_Fehler (CM_FSA_Temp_Sensor_Cx7ff_Fehler); unit Unit_DegreCelsi}, range phys -40..90 Unit_DegreCelsi, raw 0..2047, unit=Unit_DegreCelsi, transfer-property=PENDING
          signal FSA_Sensorheizung_Status_XIX_Klima_Sensor_03_XIX_E3V_EVCANFD: start 59, 1 bit, little-endian, data-type-policy=OVERRIDE, i-signal-type=PRIMITIVE, init-value=0, base-type=BT_FSA_Sensorheizung_Status, compu {0=Cx0_inaktiv (CM_FSA_Sensorheizung_Status_Cx0_inaktiv), 1=Cx1_aktiv (CM_FSA_Sensorheizung_Status_Cx1_aktiv)}, range raw 0..1, transfer-property=PENDING  # Status der Heizung im Feuchteelement (z.B. SHT10). 0 (=inaktiv) auch bei nicht verbaut
          signal FSA_Err_Defekt_HumSense_TF_XIX_Klima_Sensor_03_XIX_E3V_EVCANFD: start 60, 1 bit, little-endian, data-type-policy=OVERRIDE, i-signal-type=PRIMITIVE, init-value=0, base-type=BT_FSA_Err_Defekt_HumSense_TF, compu {0=Cx0_inaktiv (CM_FSA_Err_Defekt_HumSense_TF_Cx0_inaktiv), 1=Cx1_aktiv (CM_FSA_Err_Defekt_HumSense_TF_Cx1_aktiv)}, range raw 0..1, transfer-property=PENDING  # OBD TestFailed Flag, Statusbotschaft für Feuchtesensor außen, testFailed (TF)
          signal FSA_Err_Defekt_HumSens_TNCTOC_XIX_Klima_Sensor_03_XIX_E3V_EVCANFD: start 61, 1 bit, little-endian, data-type-policy=OVERRIDE, i-signal-type=PRIMITIVE, init-value=1, base-type=BT_FSA_Err_Defekt_HumSens_TNCTOC, compu {0=Cx0_Test_Completed_TOC (CM_FSA_Err_Defekt_HumSens_TNCTOC_Cx0_Test_Completed_TOC), 1=Cx1_Test_Not_Completed_TOC (CM_FSA_Err_Defekt_HumSens_TNCTOC_Cx1_Test_Not_Completed_TOC)}, range raw 0..1, transfer-property=PENDING  # OBD TestNotCompletedThisOperationCycle nach LIN LAH für Feuchteelement, testNotCompletedThisOperationCycle (TNCTOC)
          signal FSA_ErrMemState_XIX_Klima_Sensor_03_XIX_E3V_EVCANFD: start 62, 2 bit, little-endian, data-type-policy=OVERRIDE, i-signal-type=PRIMITIVE, init-value=0, base-type=BT_FSA_ErrMemState, compu {0=Cx0_Init_Default (CM_FSA_ErrMemState_Cx0_Init_Default), 1=Cx1_ErrMem_Active_State (CM_FSA_ErrMemState_Cx1_ErrMem_Active_State), 2=Cx2_ErrMem_InitProgress (CM_FSA_ErrMemState_Cx2_ErrMem_InitProgress), 3=Cx3_ErrMem_Init_done (CM_FSA_ErrMemState_Cx3_ErrMem_Init_done)}, range raw 0..3, transfer-property=PENDING  # OBD Signal statusbotschaft für den Feuchtesensor außen
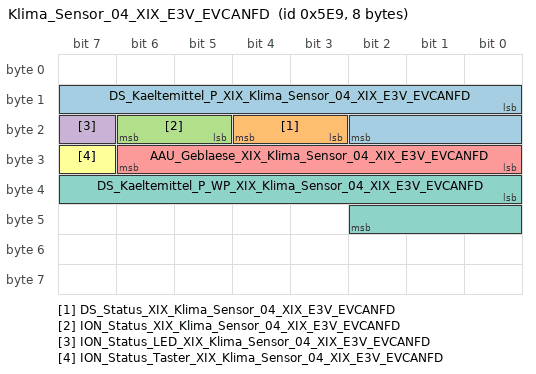
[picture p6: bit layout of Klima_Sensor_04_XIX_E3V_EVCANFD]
      frame Klima_Sensor_04_XIX_E3V_EVCANFD: id 0x5E9, from Klima, frame-length=8, can-addressing-mode=STANDARD, can-frame-rx-behavior=CAN-FD, can-frame-tx-behavior=CAN-FD
        pdu Klima_Sensor_04_XIX_E3V_EVCANFD: length=8, transmission-mode-true-timing=cyclic-timing={time-offset=0.0, time-period=0.2}, unused-bit-pattern=0
          signal DS_Kaeltemittel_P_XIX_Klima_Sensor_04_XIX_E3V_EVCANFD: start 8, 11 bit, little-endian, data-type-policy=OVERRIDE, i-signal-type=PRIMITIVE, init-value=2046, base-type=BT_DS_Kaeltemittel_P, invalid-value=Invalid_DS_Kaeltemittel_P_XIX_Klima_Sensor_04_XIX_E3V_EVCANFD:2047, compu {phys=raw*0.0161 for raw 0..2045, 2046=Cx7fe_Init (CM_DS_Kaeltemittel_P_Cx7fe_Init), 2047=Cx7ff_Fehler (CM_DS_Kaeltemittel_P_Cx7ff_Fehler); unit Unit_Bar}, range phys 0..32.9245 Unit_Bar, raw 0..2047, unit=Unit_Bar, transfer-property=PENDING  # Drucksensor Kältemittel Druck, das Signal wird bei Kl.15 AUS mit dem letzten empfangenen Wert gesendet
          signal DS_Status_XIX_Klima_Sensor_04_XIX_E3V_EVCANFD: start 19, 2 bit, little-endian, data-type-policy=OVERRIDE, i-signal-type=PRIMITIVE, init-value=2, base-type=BT_DS_Status, invalid-value=Invalid_DS_Status_XIX_Klima_Sensor_04_XIX_E3V_EVCANFD:3, compu {0=Cx0_i_O (CM_DS_Status_Cx0_i_O) (i.O.), 1=Cx1_t_b_d (CM_DS_Status_Cx1_t_b_d) (t.b.d.), 2=Cx2_Init_bzw_nicht_verfuegbar (CM_DS_Status_Cx2_Init_bzw_nicht_verfuegbar) (Init bzw. nicht verfügbar), 3=Cx3_Fehler (CM_DS_Status_Cx3_Fehler)}, range raw 0..3, transfer-property=PENDING  # Status des Drucksensors (= LIN-Slave BCM1); bei Kl.15 AUS wird für 4s noch der letzte Wert gesendet, danach wird das Signal mit dem Wert 3 (= Fehler) gesendet
          signal ION_Status_XIX_Klima_Sensor_04_XIX_E3V_EVCANFD: start 21, 2 bit, little-endian, data-type-policy=OVERRIDE, i-signal-type=PRIMITIVE, init-value=2, base-type=BT_ION_Status, compu {0=Cx0_Hochspannung_ausgeschaltet (CM_ION_Status_Cx0_Hochspannung_ausgeschaltet), 1=Cx1_Hochspannung_eingeschaltet (CM_ION_Status_Cx1_Hochspannung_eingeschaltet), 2=Cx2_Init (CM_ION_Status_Cx2_Init)}, range raw 0..2, transfer-property=PENDING  # Status Hochspannung Ionisator
          signal ION_Status_LED_XIX_Klima_Sensor_04_XIX_E3V_EVCANFD: start 23, 1 bit, little-endian, data-type-policy=OVERRIDE, i-signal-type=PRIMITIVE, init-value=0, base-type=BT_ION_Status_LED, compu {0=Cx0_Aus (CM_ION_Status_LED_Cx0_Aus), 1=Cx1_Ein (CM_ION_Status_LED_Cx1_Ein)}, range raw 0..1, transfer-property=PENDING  # Status Funktions LED
          signal AAU_Geblaese_XIX_Klima_Sensor_04_XIX_E3V_EVCANFD: start 24, 7 bit, little-endian, data-type-policy=OVERRIDE, i-signal-type=PRIMITIVE, init-value=126, base-type=BT_AAU_Geblaese, invalid-value=Invalid_AAU_Geblaese_XIX_Klima_Sensor_04_XIX_E3V_EVCANFD:127, compu {phys=raw for raw 0..100, 126=Cx7e_Init (CM_AAU_Geblaese_Cx7e_Init), 127=Cx7f_Fehler (CM_AAU_Geblaese_Cx7f_Fehler); unit Unit_PerCent}, range phys 0..100 Unit_PerCent, raw 0..127, unit=Unit_PerCent, transfer-property=PENDING  # Ansteuergrad des Gebläses
          signal ION_Status_Taster_XIX_Klima_Sensor_04_XIX_E3V_EVCANFD: start 31, 1 bit, little-endian, data-type-policy=OVERRIDE, i-signal-type=PRIMITIVE, init-value=0, base-type=BT_ION_Status_Taster, compu {0=Cx0_nicht_betaetigt (CM_ION_Status_Taster_Cx0_nicht_betaetigt), 1=Cx1_betaetigt (CM_ION_Status_Taster_Cx1_betaetigt)}, range raw 0..1, transfer-property=PENDING  # Status Kundenwunsch (Bedientaster) Ionisator
          signal DS_Kaeltemittel_P_WP_XIX_Klima_Sensor_04_XIX_E3V_EVCANFD: start 32, 11 bit, little-endian, data-type-policy=OVERRIDE, i-signal-type=PRIMITIVE, init-value=2046, base-type=BT_DS_Kaeltemittel_P_WP, invalid-value=Invalid_DS_Kaeltemittel_P_WP_XIX_Klima_Sensor_04_XIX_E3V_EVCANFD:2047, compu {phys=raw*0.5 for raw 0..360, 2046=Cx7fe_Init (CM_DS_Kaeltemittel_P_WP_Cx7fe_Init), 2047=Cx7ff_Fehler (CM_DS_Kaeltemittel_P_WP_Cx7ff_Fehler); unit Unit_Bar}, range phys 0..180 Unit_Bar, raw 0..2047, unit=Unit_Bar, transfer-property=PENDING  # Drucksensor Kältemittel Druck, das Signal wird bei Kl.15 AUS mit dem letzten empfangenen Wert gesendet für die Wärmepumpe
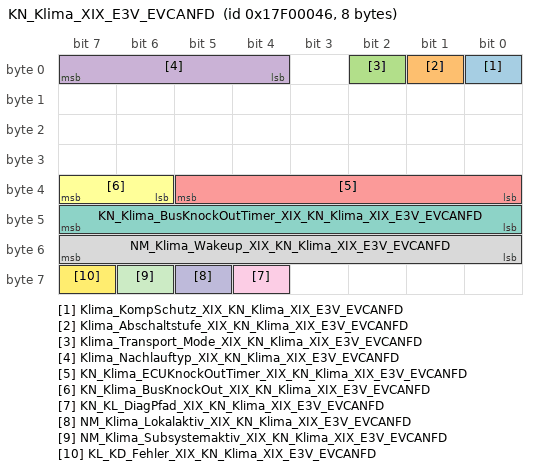
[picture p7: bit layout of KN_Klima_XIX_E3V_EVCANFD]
      frame KN_Klima_XIX_E3V_EVCANFD: id 0x17F00046, from Klima, frame-length=8, can-addressing-mode=EXTENDED, can-frame-rx-behavior=CAN-FD, can-frame-tx-behavior=CAN-FD
        pdu KN_Klima_XIX_E3V_EVCANFD: length=8, transmission-mode-true-timing=cyclic-timing={time-offset=0.0, time-period=0.5}, unused-bit-pattern=0
          signal Klima_KompSchutz_XIX_KN_Klima_XIX_E3V_EVCANFD: start 0, 1 bit, little-endian, data-type-policy=OVERRIDE, i-signal-type=PRIMITIVE, init-value=0, base-type=BT_Klima_KompSchutz, compu {0=Cx0_inaktiv (CM_Klima_KompSchutz_Cx0_inaktiv), 1=Cx1_aktiv (CM_Klima_KompSchutz_Cx1_aktiv)}, range raw 0..1, transfer-property=PENDING  # Funktionseinschränkung aufgrund Komponentenschutz aktiv
          signal Klima_Abschaltstufe_XIX_KN_Klima_XIX_E3V_EVCANFD: start 1, 1 bit, little-endian, data-type-policy=OVERRIDE, i-signal-type=PRIMITIVE, init-value=0, base-type=BT_Klima_Abschaltstufe, compu {0=Cx0_keine_Einschraenkung (CM_Klima_Abschaltstufe_Cx0_keine_Einschraenkung), 1=Cx1_Funktionseinschraenkung (CM_Klima_Abschaltstufe_Cx1_Funktionseinschraenkung)}, range raw 0..1, transfer-property=PENDING  # Funktionseinschränkung aufgrund aktiver Abschaltstufe
          signal Klima_Transport_Mode_XIX_KN_Klima_XIX_E3V_EVCANFD: start 2, 1 bit, little-endian, data-type-policy=OVERRIDE, i-signal-type=PRIMITIVE, init-value=0, base-type=BT_Klima_Transport_Mode, compu {0=Cx0_keine_Einschraenkung (CM_Klima_Transport_Mode_Cx0_keine_Einschraenkung), 1=Cx1_Funktionseinschraenkung (CM_Klima_Transport_Mode_Cx1_Funktionseinschraenkung)}, range raw 0..1, transfer-property=PENDING  # Funktionseinschränkung aufgrund aktivem Transport Mode und/oder Transport Schutz
          signal Klima_Nachlauftyp_XIX_KN_Klima_XIX_E3V_EVCANFD: start 4, 4 bit, little-endian, data-type-policy=OVERRIDE, i-signal-type=PRIMITIVE, init-value=2, base-type=BT_Klima_Nachlauftyp, compu {0=Cx0_Komm_bei_KL15_EIN (CM_Klima_Nachlauftyp_Cx0_Komm_bei_KL15_EIN), 1=Cx1_Komm_nach_KL15_AUS (CM_Klima_Nachlauftyp_Cx1_Komm_nach_KL15_AUS), 2=Cx2_Komm_bei_KL15_AUS (CM_Klima_Nachlauftyp_Cx2_Komm_bei_KL15_AUS)}, range raw 0..2, transfer-property=PENDING  # Abgebildet wird die von der Hardware vorgegebene Möglichkeit, die Kommunikation nach Klemme 15 = AUS aufrecht zu erhalten. Es wird ein Init-Wert gesendet. 0 = Kommunikation nur bei KL15=EIN (kein Nachlauf, nicht weckfähig) 1 = Kommunikation nach KL15=AUS (Nachlauf, nicht weckfähig) 2 = Kommunikation bei KL15=AUS (Nachlauf, weckfähig) 3...15 = reserviert
          signal KN_Klima_ECUKnockOutTimer_XIX_KN_Klima_XIX_E3V_EVCANFD: start 32, 6 bit, little-endian, data-type-policy=OVERRIDE, i-signal-type=PRIMITIVE, init-value=0, base-type=BT_KN_Klima_ECUKnockOutTimer, compu {phys=raw for raw 0..62, 63=Cx3f_ECUKnockOut_deaktiviert (CM_KN_Klima_ECUKnockOutTimer_Cx3f_ECUKnockOut_deaktiviert); unit Unit_Minut}, range phys 0..62 Unit_Minut, raw 0..63, unit=Unit_Minut, transfer-property=PENDING  # Ausgabe des ECUKnockOut-Timer in der Knotenbotschaft
          signal KN_Klima_BusKnockOut_XIX_KN_Klima_XIX_E3V_EVCANFD: start 38, 2 bit, little-endian, data-type-policy=OVERRIDE, i-signal-type=PRIMITIVE, init-value=0, base-type=BT_KN_Klima_BusKnockOut, compu {0=Cx0_Funktion_nicht_ausgeloest (CM_KN_Klima_BusKnockOut_Cx0_Funktion_nicht_ausgeloest), 1=Cx1_Veto_aktiv (CM_KN_Klima_BusKnockOut_Cx1_Veto_aktiv), 2=Cx2_Funktion_ausgeloest (CM_KN_Klima_BusKnockOut_Cx2_Funktion_ausgeloest), 3=Cx3_Funktion_deaktiviert (CM_KN_Klima_BusKnockOut_Cx3_Funktion_deaktiviert)}, range raw 0..3, transfer-property=PENDING  # Ausgabe des BusKnockout-Status in der Knotenbotschaft
          signal KN_Klima_BusKnockOutTimer_XIX_KN_Klima_XIX_E3V_EVCANFD: start 40, 8 bit, little-endian, data-type-policy=OVERRIDE, i-signal-type=PRIMITIVE, init-value=0, base-type=BT_KN_Klima_BusKnockOutTimer, compu {phys=raw for raw 0..254, 255=Cxff_BusKnockOut_deaktiviert (CM_KN_Klima_BusKnockOutTimer_Cxff_BusKnockOut_deaktiviert)}, range phys 0..254, raw 0..255, transfer-property=PENDING  # Ausgabe des BusKnockOut-Timer in der Knotenbotschaft
          signal NM_Klima_Wakeup_XIX_KN_Klima_XIX_E3V_EVCANFD: start 48, 8 bit, little-endian, data-type-policy=OVERRIDE, i-signal-type=PRIMITIVE, init-value=0, base-type=BT_NM_Klima_Wakeup, compu {0=Cx0_Peripherie_Wakeup_Ursache_nicht_bekannt (CM_NM_Klima_Wakeup_Cx0_Peripherie_Wakeup_Ursache_nicht_bekannt) (Peripherie_Wakeup__Ursache_nicht_bekannt), 1=Cx1_Bus_Wakeup (CM_NM_Klima_Wakeup_Cx1_Bus_Wakeup), 2=Cx2_KL15_HW (CM_NM_Klima_Wakeup_Cx2_KL15_HW), 3=Cx3_KL30_Reset (CM_NM_Klima_Wakeup_Cx3_KL30_Reset), 4=Cx4_STH_Taste (CM_NM_Klima_Wakeup_Cx4_STH_Taste), 5=Cx5_Restwaerme_Menuauswahl (CM_NM_Klima_Wakeup_Cx5_Restwaerme_Menuauswahl), 128=Cx80_STH_Ein_Zielzeitlogik (CM_NM_Klima_Wakeup_Cx80_STH_Ein_Zielzeitlogik) (STH_Ein__Zielzeitlogik), 129=Cx81_Standfunktion_Funk_EIN (CM_NM_Klima_Wakeup_Cx81_Standfunktion_Funk_EIN), 130=Cx82_Umentscheidung_STL_nach_STH (CM_NM_Klima_Wakeup_Cx82_Umentscheidung_STL_nach_STH), 131=Cx83_Ablauf_der_max_Betriebsdauer (CM_NM_Klima_Wakeup_Cx83_Ablauf_der_max_Betriebsdauer), 132=Cx84_Geblaese_aus_ein (CM_NM_Klima_Wakeup_Cx84_Geblaese_aus_ein), 133=Cx85_CO2_Warnung (CM_NM_Klima_Wakeup_Cx85_CO2_Warnung)}, range raw 0..133, transfer-property=PENDING  # enthält die Weckursache; stehen mehrere Weckursachen parallel an, dann muss der kleinste Wert übertragen werden
          signal KN_KL_DiagPfad_XIX_KN_Klima_XIX_E3V_EVCANFD: start 60, 1 bit, little-endian, data-type-policy=OVERRIDE, i-signal-type=PRIMITIVE, base-type=BT_KN_KL_DiagPfad, compu {0=Cx0_aktiv (CM_KN_KL_DiagPfad_Cx0_aktiv), 1=Cx1_inaktiv (CM_KN_KL_DiagPfad_Cx1_inaktiv)}, range raw 0..1, transfer-property=PENDING  # Kennzeichnung der Diagnosefähigkeit des BusInterfaces eines Steuergerätes (Knoten) Umfang LAH 80127 Bei Nutzung des Signal explizit pro angebundenem BusInterface zu setzen: MQB auf K-CAN = 0 (aktiv) MQB2020 auf K-CAN = 0 (aktiv) MLBevoGen1 auf H-CAN = 0 (aktiv) MLBevoGen2 auf K2-CAN = 0 (aktiv) MQBw_Baseline auf EVCANFD = 0 (aktiv) E3_1_1_MEB auf EVCANFD = 0 (aktiv) E3_1_1_UNECE auf EVCANFD = 0 (aktiv)
          signal NM_Klima_Lokalaktiv_XIX_KN_Klima_XIX_E3V_EVCANFD: start 61, 1 bit, little-endian, data-type-policy=OVERRIDE, i-signal-type=PRIMITIVE, init-value=0, base-type=BT_NM_Klima_Lokalaktiv, compu {0=Cx0_war_nicht_lokal_aktiv (CM_NM_Klima_Lokalaktiv_Cx0_war_nicht_lokal_aktiv), 1=Cx1_war_lokal_aktiv (CM_NM_Klima_Lokalaktiv_Cx1_war_lokal_aktiv)}, range raw 0..1, transfer-property=PENDING  # Zeigt an ob das SG nach Klemme15 AUS und nach entsprechender MAX Aktivzeit noch aktiv war
          signal NM_Klima_Subsystemaktiv_XIX_KN_Klima_XIX_E3V_EVCANFD: start 62, 1 bit, little-endian, data-type-policy=OVERRIDE, i-signal-type=PRIMITIVE, init-value=0, base-type=BT_NM_Klima_Subsystemaktiv, compu {0=Cx0_Subsystem_war_nicht_lokalaktiv (CM_NM_Klima_Subsystemaktiv_Cx0_Subsystem_war_nicht_lokalaktiv), 1=Cx1_war_lokalaktiv (CM_NM_Klima_Subsystemaktiv_Cx1_war_lokalaktiv)}, range raw 0..1, transfer-property=PENDING  # Zeigt an ob ein Subsystem des SGs nach Klemme15 AUS und nach entsprechender MAX Aktivzeit noch aktiv war
          signal KL_KD_Fehler_XIX_KN_Klima_XIX_E3V_EVCANFD: start 63, 1 bit, little-endian, data-type-policy=OVERRIDE, i-signal-type=PRIMITIVE, init-value=0, base-type=BT_KL_KD_Fehler, compu {0=Cx0_kein_KD_Fehler (CM_KL_KD_Fehler_Cx0_kein_KD_Fehler), 1=Cx1_KD_Fehler (CM_KL_KD_Fehler_Cx1_KD_Fehler)}, range raw 0..1, transfer-property=PENDING  # Status Kundendienstfehlerspeichereinträge
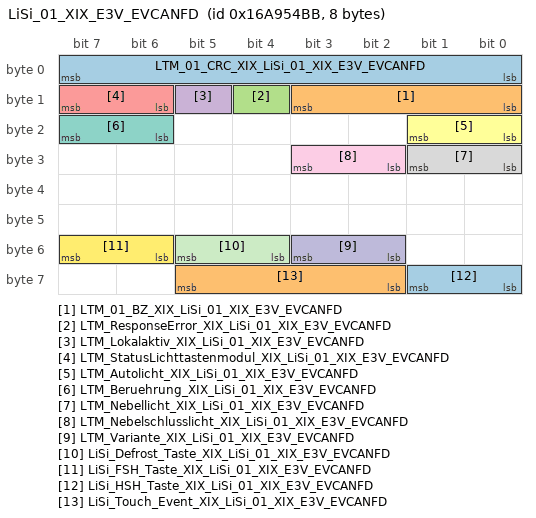
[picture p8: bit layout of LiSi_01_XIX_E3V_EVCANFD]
      frame LiSi_01_XIX_E3V_EVCANFD: id 0x16A954BB, to Klima, frame-length=8, can-addressing-mode=EXTENDED, can-frame-rx-behavior=CAN-FD, can-frame-tx-behavior=CAN-FD
        pdu LiSi_01_XIX_E3V_EVCANFD: length=8, transmission-mode-true-timing=cyclic-timing={time-offset=0.0, time-period=0.04}, unused-bit-pattern=0
          signal LTM_01_CRC_XIX_LiSi_01_XIX_E3V_EVCANFD: start 0, 8 bit, little-endian, data-type-policy=OVERRIDE, i-signal-type=PRIMITIVE, base-type=BT_LTM_01_CRC, compu {phys=raw for raw 0..255}, range phys 0..255, raw 0..255, transfer-property=PENDING  # Ab MQB und MLBevo: "Berechnung siehe Lastenheft "End-to-End Kommunikationsabsicherung"" Endwerte siehe Begleitdokument "S-PDU Kennungsfolgen"
          signal LTM_01_BZ_XIX_LiSi_01_XIX_E3V_EVCANFD: start 8, 4 bit, little-endian, data-type-policy=OVERRIDE, i-signal-type=PRIMITIVE, base-type=BT_LTM_01_BZ, compu {phys=raw for raw 0..15}, range phys 0..15, raw 0..15, transfer-property=PENDING  # 4bit Botschaftszähler
          signal LTM_ResponseError_XIX_LiSi_01_XIX_E3V_EVCANFD: start 12, 1 bit, little-endian, data-type-policy=OVERRIDE, i-signal-type=PRIMITIVE, init-value=0, base-type=BT_LTM_ResponseError, invalid-value=Invalid_LTM_ResponseError_XIX_LiSi_01_XIX_E3V_EVCANFD:1, compu {0=Cx0_normal (CM_LTM_ResponseError_Cx0_normal), 1=Cx1_Fehler (CM_LTM_ResponseError_Cx1_Fehler)}, range raw 0..1, transfer-property=PENDING  # siehe LIN2.0-Specification (Darf nicht über ein Fehlergueltigkeitsbit abgesichtert werden!)
          signal LTM_Lokalaktiv_XIX_LiSi_01_XIX_E3V_EVCANFD: start 13, 1 bit, little-endian, data-type-policy=OVERRIDE, i-signal-type=PRIMITIVE, init-value=0, base-type=BT_LTM_Lokalaktiv, compu {0=Cx0_war_nicht_lokal_aktiv (CM_LTM_Lokalaktiv_Cx0_war_nicht_lokal_aktiv), 1=Cx1_war_lokal_aktiv (CM_LTM_Lokalaktiv_Cx1_war_lokal_aktiv)}, range raw 0..1, transfer-property=PENDING  # Lokalaktiv Statusbit
          signal LTM_StatusLichttastenmodul_XIX_LiSi_01_XIX_E3V_EVCANFD: start 14, 2 bit, little-endian, data-type-policy=OVERRIDE, i-signal-type=PRIMITIVE, init-value=2, base-type=BT_LTM_StatusLichttastenmodul, compu {0=Cx0_Lichttastenmodul_betriebsbereit (CM_LTM_StatusLichttastenmodul_Cx0_Lichttastenmodul_betriebsbereit), 2=Cx2_Init (CM_LTM_StatusLichttastenmodul_Cx2_Init), 3=Cx3_Fehler_oder_defekt (CM_LTM_StatusLichttastenmodul_Cx3_Fehler_oder_defekt)}, range raw 0..3, transfer-property=PENDING  # Betriebszustand Lichttastenmodul
          signal LTM_Autolicht_XIX_LiSi_01_XIX_E3V_EVCANFD: start 16, 2 bit, little-endian, data-type-policy=OVERRIDE, i-signal-type=PRIMITIVE, init-value=0, base-type=BT_LTM_Autolicht, compu {0=Cx0_Taste_unbetaetigt (CM_LTM_Autolicht_Cx0_Taste_unbetaetigt), 1=Cx1_Taste_betaetigt (CM_LTM_Autolicht_Cx1_Taste_betaetigt), 2=Cx2_Taste_nicht_verbaut (CM_LTM_Autolicht_Cx2_Taste_nicht_verbaut)}, range raw 0..2, transfer-property=PENDING  # Status Autolicht-Taste
          signal LTM_Beruehrung_XIX_LiSi_01_XIX_E3V_EVCANFD: start 22, 2 bit, little-endian, data-type-policy=OVERRIDE, i-signal-type=PRIMITIVE, base-type=BT_LTM_Beruehrung, compu {0=Cx0_Beruehrung_inaktiv (CM_LTM_Beruehrung_Cx0_Beruehrung_inaktiv), 1=Cx1_Beruehrung_aktiv (CM_LTM_Beruehrung_Cx1_Beruehrung_aktiv), 2=Cx2_Beruehrungssensor_nicht_verbaut (CM_LTM_Beruehrung_Cx2_Beruehrungssensor_nicht_verbaut)}, range raw 0..2, transfer-property=PENDING  # Status für Berührung der Auto-Taste im Lichttastenmodul (LTM)
          signal LTM_Nebellicht_XIX_LiSi_01_XIX_E3V_EVCANFD: start 24, 2 bit, little-endian, data-type-policy=OVERRIDE, i-signal-type=PRIMITIVE, init-value=0, base-type=BT_LTM_Nebellicht, compu {0=Cx0_Taste_unbetaetigt (CM_LTM_Nebellicht_Cx0_Taste_unbetaetigt), 1=Cx1_Taste_betaetigt (CM_LTM_Nebellicht_Cx1_Taste_betaetigt), 2=Cx2_Taste_nicht_verbaut (CM_LTM_Nebellicht_Cx2_Taste_nicht_verbaut)}, range raw 0..2, transfer-property=PENDING  # Status Nebellicht-Taste
          signal LTM_Nebelschlusslicht_XIX_LiSi_01_XIX_E3V_EVCANFD: start 26, 2 bit, little-endian, data-type-policy=OVERRIDE, i-signal-type=PRIMITIVE, init-value=0, base-type=BT_LTM_Nebelschlusslicht, compu {0=Cx0_Taste_unbetaetigt (CM_LTM_Nebelschlusslicht_Cx0_Taste_unbetaetigt), 1=Cx1_Taste_betaetigt (CM_LTM_Nebelschlusslicht_Cx1_Taste_betaetigt), 2=Cx2_Taste_nicht_verbaut (CM_LTM_Nebelschlusslicht_Cx2_Taste_nicht_verbaut)}, range raw 0..2, transfer-property=PENDING  # Status Nebelschlusslicht-Taste
          signal LTM_Variante_XIX_LiSi_01_XIX_E3V_EVCANFD: start 50, 2 bit, little-endian, data-type-policy=OVERRIDE, i-signal-type=PRIMITIVE, init-value=0, base-type=BT_LTM_Variante, compu {0=Cx0_Ein_Tasten_Bedienung (CM_LTM_Variante_Cx0_Ein_Tasten_Bedienung), 1=Cx1_Drei_Tasten_Bedienung (CM_LTM_Variante_Cx1_Drei_Tasten_Bedienung), 2=Cx2_Variante_3 (CM_LTM_Variante_Cx2_Variante_3), 3=Cx3_Variante_4 (CM_LTM_Variante_Cx3_Variante_4)}, range raw 0..3, transfer-property=PENDING  # LTM_Variante dient zur Unterscheidung, welche Variante des Lichttastenmoduls verbaut ist: 0x00 1-Tasten-Bedienung (LTM mit 1-Hauptlichttaste) 0x01 3-Tasten-Bedienung (LTM mit 3-Hauptlichttasten) 0x02 Variante 3 0x03 Variante 4
          signal LiSi_Defrost_Taste_XIX_LiSi_01_XIX_E3V_EVCANFD: start 52, 2 bit, little-endian, data-type-policy=OVERRIDE, i-signal-type=PRIMITIVE, init-value=3, base-type=BT_LiSi_Defrost_Taste, invalid-value=Invalid_LiSi_Defrost_Taste_XIX_LiSi_01_XIX_E3V_EVCANFD:2, compu {0=Cx0_Taste_nicht_betaetigt (CM_LiSi_Defrost_Taste_Cx0_Taste_nicht_betaetigt), 1=Cx1_Taste_betaetigt (CM_LiSi_Defrost_Taste_Cx1_Taste_betaetigt), 2=Cx2_Fehler (CM_LiSi_Defrost_Taste_Cx2_Fehler), 3=Cx3_Init_oder_nicht_verbaut (CM_LiSi_Defrost_Taste_Cx3_Init_oder_nicht_verbaut)}, range raw 0..3, transfer-property=PENDING, to Klima(timeout 0.5 s)  # Defrost AN/AUS und Status
          signal LiSi_FSH_Taste_XIX_LiSi_01_XIX_E3V_EVCANFD: start 54, 2 bit, little-endian, data-type-policy=OVERRIDE, i-signal-type=PRIMITIVE, init-value=3, base-type=BT_LiSi_FSH_Taste, invalid-value=Invalid_LiSi_FSH_Taste_XIX_LiSi_01_XIX_E3V_EVCANFD:2, compu {0=Cx0_Taste_nicht_betaetigt (CM_LiSi_FSH_Taste_Cx0_Taste_nicht_betaetigt), 1=Cx1_Taste_betaetigt (CM_LiSi_FSH_Taste_Cx1_Taste_betaetigt), 2=Cx2_Fehler (CM_LiSi_FSH_Taste_Cx2_Fehler), 3=Cx3_Init_oder_nicht_verbaut (CM_LiSi_FSH_Taste_Cx3_Init_oder_nicht_verbaut)}, range raw 0..3, transfer-property=PENDING, to Klima(timeout 0.5 s)  # Frontscheibenheizung AN/AUS und Status
          signal LiSi_HSH_Taste_XIX_LiSi_01_XIX_E3V_EVCANFD: start 56, 2 bit, little-endian, data-type-policy=OVERRIDE, i-signal-type=PRIMITIVE, init-value=3, base-type=BT_LiSi_HSH_Taste, invalid-value=Invalid_LiSi_HSH_Taste_XIX_LiSi_01_XIX_E3V_EVCANFD:2, compu {0=Cx0_Taste_nicht_betaetigt (CM_LiSi_HSH_Taste_Cx0_Taste_nicht_betaetigt), 1=Cx1_Taste_betaetigt (CM_LiSi_HSH_Taste_Cx1_Taste_betaetigt), 2=Cx2_Fehler (CM_LiSi_HSH_Taste_Cx2_Fehler), 3=Cx3_Init_oder_nicht_verbaut (CM_LiSi_HSH_Taste_Cx3_Init_oder_nicht_verbaut)}, range raw 0..3, transfer-property=PENDING, to Klima(timeout 0.5 s)  # Heckscheibenheizung AN/AUS
          signal LiSi_Touch_Event_XIX_LiSi_01_XIX_E3V_EVCANFD: start 58, 4 bit, little-endian, data-type-policy=OVERRIDE, i-signal-type=PRIMITIVE, init-value=0, base-type=BT_LiSi_Touch_Event, invalid-value=Invalid_LiSi_Touch_Event_XIX_LiSi_01_XIX_E3V_EVCANFD:15, compu {0=Cx0_nicht_betaetigt (CM_LiSi_Touch_Event_Cx0_nicht_betaetigt), 1=Cx1_Tippen (CM_LiSi_Touch_Event_Cx1_Tippen), 2=Cx2_Wischen_Slide (CM_LiSi_Touch_Event_Cx2_Wischen_Slide), 3=Cx3_Geste (CM_LiSi_Touch_Event_Cx3_Geste), 4=Cx4_Doppeltippen (CM_LiSi_Touch_Event_Cx4_Doppeltippen), 5=Cx5_Longpress_1 (CM_LiSi_Touch_Event_Cx5_Longpress_1), 6=Cx6_Longpress_2 (CM_LiSi_Touch_Event_Cx6_Longpress_2), 7=Cx7_Longpress_3 (CM_LiSi_Touch_Event_Cx7_Longpress_3), 8=Cx8_Press (CM_LiSi_Touch_Event_Cx8_Press), 9=Cx9_Strongpress (CM_LiSi_Touch_Event_Cx9_Strongpress), 10=Cxa_reserviert (CM_LiSi_Touch_Event_Cxa_reserviert), 11=Cxb_reserviert (CM_LiSi_Touch_Event_Cxb_reserviert), 12=Cxc_reserviert (CM_LiSi_Touch_Event_Cxc_reserviert), 13=Cxd_reserviert (CM_LiSi_Touch_Event_Cxd_reserviert), 14=Cxe_Taktgeber_Inkrement (CM_LiSi_Touch_Event_Cxe_Taktgeber_Inkrement), 15=Cxf_Fehler (CM_LiSi_Touch_Event_Cxf_Fehler)}, range raw 0..15, transfer-property=PENDING  # Touch_Events für Informationen einer Funktionsauslösung auf der LiSi, welches dann für bspw. ein akustiches Signal zentral umgesetzt werden können.
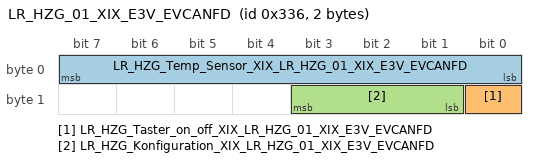
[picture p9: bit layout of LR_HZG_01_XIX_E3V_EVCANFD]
      frame LR_HZG_01_XIX_E3V_EVCANFD: id 0x336, to Klima, frame-length=2, can-addressing-mode=STANDARD, can-frame-rx-behavior=CAN-FD, can-frame-tx-behavior=CAN-FD
        pdu LR_HZG_01_XIX_E3V_EVCANFD: length=2, transmission-mode-true-timing=cyclic-timing={time-offset=0.0, time-period=0.12}, unused-bit-pattern=0
          signal LR_HZG_Temp_Sensor_XIX_LR_HZG_01_XIX_E3V_EVCANFD: start 0, 8 bit, little-endian, data-type-policy=OVERRIDE, i-signal-type=PRIMITIVE, init-value=254, base-type=BT_LR_HZG_Temp_Sensor, compu {phys=raw-50 for raw 0..154, 253=Cxfd_KS_Plus_Unterbrechung (CM_LR_HZG_Temp_Sensor_Cxfd_KS_Plus_Unterbrechung) (KS_Plus__Unterbrechung), 254=Cxfe_Init (CM_LR_HZG_Temp_Sensor_Cxfe_Init), 255=Cxff_Tempsensor_fehlerhaft_KS_GND (CM_LR_HZG_Temp_Sensor_Cxff_Tempsensor_fehlerhaft_KS_GND) (Tempsensor_fehlerhaft__KS_GND); unit Unit_DegreCelsi}, range phys -50..104 Unit_DegreCelsi, raw 0..255, unit=Unit_DegreCelsi, transfer-property=PENDING, to Klima(timeout 1.2 s)  # Temperaturwert Lenkradheizung
          signal LR_HZG_Taster_on_off_XIX_LR_HZG_01_XIX_E3V_EVCANFD: start 8, 1 bit, little-endian, data-type-policy=OVERRIDE, i-signal-type=PRIMITIVE, init-value=0, base-type=BT_LR_HZG_Taster_on_off, compu {0=Cx0_nicht_betaetigt (CM_LR_HZG_Taster_on_off_Cx0_nicht_betaetigt), 1=Cx1_betaetigt (CM_LR_HZG_Taster_on_off_Cx1_betaetigt)}, range raw 0..1, transfer-property=PENDING  # Anforderung des Schalters am MFL: Lenkradheizung aus/ein (Regelung der LR_HZG ist im SMLS)
          signal LR_HZG_Konfiguration_XIX_LR_HZG_01_XIX_E3V_EVCANFD: start 9, 3 bit, little-endian, data-type-policy=OVERRIDE, i-signal-type=PRIMITIVE, init-value=0, base-type=BT_LR_HZG_Konfiguration, compu {0=Cx0_Init (CM_LR_HZG_Konfiguration_Cx0_Init), 1=Cx1_Parametersatz_1 (CM_LR_HZG_Konfiguration_Cx1_Parametersatz_1), 2=Cx2_Parametersatz_2 (CM_LR_HZG_Konfiguration_Cx2_Parametersatz_2), 3=Cx3_Parametersatz_3 (CM_LR_HZG_Konfiguration_Cx3_Parametersatz_3), 4=Cx4_Parametersatz_4 (CM_LR_HZG_Konfiguration_Cx4_Parametersatz_4), 5=Cx5_Parametersatz_5 (CM_LR_HZG_Konfiguration_Cx5_Parametersatz_5), 6=Cx6_Parametersatz_6 (CM_LR_HZG_Konfiguration_Cx6_Parametersatz_6), 7=Cx7_Parametersatz_7 (CM_LR_HZG_Konfiguration_Cx7_Parametersatz_7)}, range raw 0..7, transfer-property=PENDING, to Klima(timeout 1.2 s)  # Konfiguration der Heizmatte der Lenkradheizung
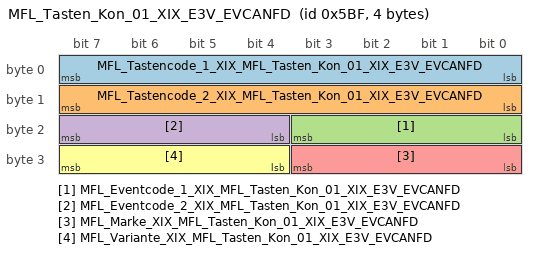
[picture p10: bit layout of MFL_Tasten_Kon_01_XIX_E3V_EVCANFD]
      frame MFL_Tasten_Kon_01_XIX_E3V_EVCANFD: id 0x5BF, to Klima, frame-length=4, can-addressing-mode=STANDARD, can-frame-rx-behavior=CAN-FD, can-frame-tx-behavior=CAN-FD
        pdu MFL_Tasten_Kon_01_XIX_E3V_EVCANFD: length=4, minimum-delay=0.01, transmission-mode-true-timing=event-controlled-timing={number-of-repetitions=0, repetition-period=0.0}, unused-bit-pattern=0
          signal MFL_Tastencode_1_XIX_MFL_Tasten_Kon_01_XIX_E3V_EVCANFD: start 0, 8 bit, little-endian, data-type-policy=OVERRIDE, i-signal-type=PRIMITIVE, init-value=0, base-type=BT_MFL_Tastencode_1, compu {0=Cx0_Key_Released_No_Key (CM_MFL_Tastencode_1_Cx0_Key_Released_No_Key) (Key_Released__No_Key), 1=Cx1_Context_Menu (CM_MFL_Tastencode_1_Cx1_Context_Menu), 2=Cx2_Menu_Up_Next_Screen (CM_MFL_Tastencode_1_Cx2_Menu_Up_Next_Screen) (Menu_Up__Next_Screen), 3=Cx3_Menu_Down_Previous_Screen (CM_MFL_Tastencode_1_Cx3_Menu_Down_Previous_Screen) (Menu_Down__Previous_Screen), 4=Cx4_Up (CM_MFL_Tastencode_1_Cx4_Up), 5=Cx5_Down (CM_MFL_Tastencode_1_Cx5_Down), 6=Cx6_Up_Down_ThumbWheel (CM_MFL_Tastencode_1_Cx6_Up_Down_ThumbWheel) (Up__Down_ThumbWheel), 7=Cx7_OK_ThumbWheel_Button (CM_MFL_Tastencode_1_Cx7_OK_ThumbWheel_Button) (OK__ThumbWheel_Button), 8=Cx8_Cancel_Escape (CM_MFL_Tastencode_1_Cx8_Cancel_Escape) (Cancel__Escape), 9=Cx9_Main_Menu (CM_MFL_Tastencode_1_Cx9_Main_Menu), 10=Cxa_Side_Menu_left (CM_MFL_Tastencode_1_Cxa_Side_Menu_left), 11=Cxb_Side_Menu_right (CM_MFL_Tastencode_1_Cxb_Side_Menu_right), 12=Cxc_FAS_Menu (CM_MFL_Tastencode_1_Cxc_FAS_Menu), 13=Cxd_Left_Right_ThumbWheel (CM_MFL_Tastencode_1_Cxd_Left_Right_ThumbWheel) (Left__Right_ThumbWheel), 14=Cxe_FAS_Menu_ThumbWheel (CM_MFL_Tastencode_1_Cxe_FAS_Menu_ThumbWheel), 16=Cx10_Volume_Up (CM_MFL_Tastencode_1_Cx10_Volume_Up), 17=Cx11_Volume_Down (CM_MFL_Tastencode_1_Cx11_Volume_Down), 18=Cx12_Volume_Up_Down_ThumbWheel (CM_MFL_Tastencode_1_Cx12_Volume_Up_Down_ThumbWheel) (Volume_Up__Down_ThumbWheel), 19=Cx13_Volume_ThumbWheel_Button (CM_MFL_Tastencode_1_Cx13_Volume_ThumbWheel_Button), 20=Cx14_Audio_Source (CM_MFL_Tastencode_1_Cx14_Audio_Source), 21=Cx15_Arrow_A_Up_Right (CM_MFL_Tastencode_1_Cx15_Arrow_A_Up_Right) (Arrow_A_Up__Right), 22=Cx16_Arrow_A_Down_Left (CM_MFL_Tastencode_1_Cx16_Arrow_A_Down_Left) (Arrow_A_Down__Left), 23=Cx17_Arrow_B_Up_Right (CM_MFL_Tastencode_1_Cx17_Arrow_B_Up_Right) (Arrow_B_Up__Right), 24=Cx18_Arrow_B_Down_Left (CM_MFL_Tastencode_1_Cx18_Arrow_B_Down_Left) (Arrow_B_Down__Left), 25=Cx19_PTT_PushToTalk (CM_MFL_Tastencode_1_Cx19_PTT_PushToTalk) (PTT__PushToTalk), 26=Cx1a_PTT_Cancel (CM_MFL_Tastencode_1_Cx1a_PTT_Cancel), 27=Cx1b_Route_Info (CM_MFL_Tastencode_1_Cx1b_Route_Info), 28=Cx1c_Hook (CM_MFL_Tastencode_1_Cx1c_Hook), 29=Cx1d_Hang_Up (CM_MFL_Tastencode_1_Cx1d_Hang_Up), 30=Cx1e_Off_Hook (CM_MFL_Tastencode_1_Cx1e_Off_Hook), 31=Cx1f_Light_On_Off (CM_MFL_Tastencode_1_Cx1f_Light_On_Off) (Light_On__Off), 32=Cx20_Mute (CM_MFL_Tastencode_1_Cx20_Mute), 33=Cx21_Joker1 (CM_MFL_Tastencode_1_Cx21_Joker1), 34=Cx22_Joker2 (CM_MFL_Tastencode_1_Cx22_Joker2), 35=Cx23_View (CM_MFL_Tastencode_1_Cx23_View), 36=Cx24_Arrow_A_Up_Down_ThumbWheel (CM_MFL_Tastencode_1_Cx24_Arrow_A_Up_Down_ThumbWheel) (Arrow_A_Up__Down_ThumbWheel), 37=Cx25_Lenkradheizung (CM_MFL_Tastencode_1_Cx25_Lenkradheizung), 38=Cx26_Rekuperation (CM_MFL_Tastencode_1_Cx26_Rekuperation), 39=Cx27_Tube_Toggle (CM_MFL_Tastencode_1_Cx27_Tube_Toggle), 40=Cx28_DRS_Drag_Reduction_System (CM_MFL_Tastencode_1_Cx28_DRS_Drag_Reduction_System), 41=Cx29_Stopwatch_Start_Stop (CM_MFL_Tastencode_1_Cx29_Stopwatch_Start_Stop), 42=Cx2a_Stopwatch_Nextlap (CM_MFL_Tastencode_1_Cx2a_Stopwatch_Nextlap), 43=Cx2b_HDF_High_Downforce (CM_MFL_Tastencode_1_Cx2b_HDF_High_Downforce), 100=Cx64_MAP (CM_MFL_Tastencode_1_Cx64_MAP), 101=Cx65_MAP_Boost (CM_MFL_Tastencode_1_Cx65_MAP_Boost), 102=Cx66_Turn_signal_left (CM_MFL_Tastencode_1_Cx66_Turn_signal_left), 103=Cx67_Turn_signal_right (CM_MFL_Tastencode_1_Cx67_Turn_signal_right), 104=Cx68_Turn_signal_off (CM_MFL_Tastencode_1_Cx68_Turn_signal_off), 105=Cx69_Flashlight (CM_MFL_Tastencode_1_Cx69_Flashlight), 106=Cx6a_Highbeam (CM_MFL_Tastencode_1_Cx6a_Highbeam), 107=Cx6b_Washer_button (CM_MFL_Tastencode_1_Cx6b_Washer_button), 108=Cx6c_Wiper_button_left (CM_MFL_Tastencode_1_Cx6c_Wiper_button_left), 109=Cx6d_Wiper_button_right (CM_MFL_Tastencode_1_Cx6d_Wiper_button_right), 110=Cx6e_Wiper_button_cancel (CM_MFL_Tastencode_1_Cx6e_Wiper_button_cancel), 111=Cx6f_Exhaust_Sound (CM_MFL_Tastencode_1_Cx6f_Exhaust_Sound), 112=Cx70_Drive_Select_button (CM_MFL_Tastencode_1_Cx70_Drive_Select_button), 113=Cx71_Sport_button (CM_MFL_Tastencode_1_Cx71_Sport_button), 114=Cx72_ESP_Drift_Selection_ThumbWheel (CM_MFL_Tastencode_1_Cx72_ESP_Drift_Selection_ThumbWheel), 115=Cx73_PTT_special_vehicle (CM_MFL_Tastencode_1_Cx73_PTT_special_vehicle), 116=Cx74_TravelAssist (CM_MFL_Tastencode_1_Cx74_TravelAssist), 117=Cx75_Launch_Control (CM_MFL_Tastencode_1_Cx75_Launch_Control), 118=Cx76_Drift_Mode_Button_Increase (CM_MFL_Tastencode_1_Cx76_Drift_Mode_Button_Increase), 119=Cx77_Drift_Mode_Button_Decrease (CM_MFL_Tastencode_1_Cx77_Drift_Mode_Button_Decrease), 120=Cx78_Drift_Mode_Button_Select (CM_MFL_Tastencode_1_Cx78_Drift_Mode_Button_Select), 121=Cx79_Drive_Mode_Button_Increase (CM_MFL_Tastencode_1_Cx79_Drive_Mode_Button_Increase), 122=Cx7a_Drive_Mode_Button_Decrease (CM_MFL_Tastencode_1_Cx7a_Drive_Mode_Button_Decrease), 123=Cx7b_Drive_Mode_Button_Select (CM_MFL_Tastencode_1_Cx7b_Drive_Mode_Button_Select), 124=Cx7c_E_Boost_Button_Increase (CM_MFL_Tastencode_1_Cx7c_E_Boost_Button_Increase), 125=Cx7d_E_Boost_Button_Decrease (CM_MFL_Tastencode_1_Cx7d_E_Boost_Button_Decrease), 126=Cx7e_E_Boost_Button_Select (CM_MFL_Tastencode_1_Cx7e_E_Boost_Button_Select), 127=Cx7f_PerformanceHybridButton_Increase (CM_MFL_Tastencode_1_Cx7f_PerformanceHybridButton_Increase), 128=Cx80_PerformanceHybridButton_Decrease (CM_MFL_Tastencode_1_Cx80_PerformanceHybridButton_Decrease), 129=Cx81_EV_Mode_Button (CM_MFL_Tastencode_1_Cx81_EV_Mode_Button), 130=Cx82_HUD_Button (CM_MFL_Tastencode_1_Cx82_HUD_Button), 131=Cx83_PASM_Wheel (CM_MFL_Tastencode_1_Cx83_PASM_Wheel), 132=Cx84_PASM_Button (CM_MFL_Tastencode_1_Cx84_PASM_Button), 133=Cx85_PTV_Wheel (CM_MFL_Tastencode_1_Cx85_PTV_Wheel), 134=Cx86_PTV_Button (CM_MFL_Tastencode_1_Cx86_PTV_Button), 135=Cx87_TC_ESC_Wheel (CM_MFL_Tastencode_1_Cx87_TC_ESC_Wheel), 136=Cx88_TC_ESC_Button (CM_MFL_Tastencode_1_Cx88_TC_ESC_Button), 137=Cx89_aLDW_Button (CM_MFL_Tastencode_1_Cx89_aLDW_Button), 169=Cxa9_VirtualGearbox_Button (CM_MFL_Tastencode_1_Cxa9_VirtualGearbox_Button), 170=Cxaa_VirtualGearbox_Wheel (CM_MFL_Tastencode_1_Cxaa_VirtualGearbox_Wheel), 240=Cxf0_Startup_Reset (CM_MFL_Tastencode_1_Cxf0_Startup_Reset), 241=Cxf1_Initialization (CM_MFL_Tastencode_1_Cxf1_Initialization)}, range raw 0..241, transfer-property=TRIGGERED-ON-CHANGE-WITHOUT-REPETITION, to Klima  # Beschreibt die Funktion einer fest zugeordneten Taste/Walze auf dem MFL. Bei Betätigung ändert sich der Wert von 0x0 auf den jeweiligen Tastencode.
          signal MFL_Tastencode_2_XIX_MFL_Tasten_Kon_01_XIX_E3V_EVCANFD: start 8, 8 bit, little-endian, data-type-policy=OVERRIDE, i-signal-type=PRIMITIVE, init-value=0, base-type=BT_MFL_Tastencode_2, compu {0=Cx0_Key_Released_No_Key (CM_MFL_Tastencode_2_Cx0_Key_Released_No_Key) (Key_Released__No_Key), 1=Cx1_Context_Menu (CM_MFL_Tastencode_2_Cx1_Context_Menu), 2=Cx2_Menu_Up_Next_Screen (CM_MFL_Tastencode_2_Cx2_Menu_Up_Next_Screen) (Menu_Up__Next_Screen), 3=Cx3_Menu_Down_Previous_Screen (CM_MFL_Tastencode_2_Cx3_Menu_Down_Previous_Screen) (Menu_Down__Previous_Screen), 4=Cx4_Up (CM_MFL_Tastencode_2_Cx4_Up), 5=Cx5_Down (CM_MFL_Tastencode_2_Cx5_Down), 6=Cx6_Up_Down_ThumbWheel (CM_MFL_Tastencode_2_Cx6_Up_Down_ThumbWheel) (Up__Down_ThumbWheel), 7=Cx7_OK_ThumbWheel_Button (CM_MFL_Tastencode_2_Cx7_OK_ThumbWheel_Button) (OK__ThumbWheel_Button), 8=Cx8_Cancel_Escape (CM_MFL_Tastencode_2_Cx8_Cancel_Escape) (Cancel__Escape), 9=Cx9_Main_Menu (CM_MFL_Tastencode_2_Cx9_Main_Menu), 10=Cxa_Side_Menu_left (CM_MFL_Tastencode_2_Cxa_Side_Menu_left), 11=Cxb_Side_Menu_right (CM_MFL_Tastencode_2_Cxb_Side_Menu_right), 12=Cxc_FAS_Menu (CM_MFL_Tastencode_2_Cxc_FAS_Menu), 13=Cxd_Left_Right_ThumbWheel (CM_MFL_Tastencode_2_Cxd_Left_Right_ThumbWheel) (Left__Right_ThumbWheel), 14=Cxe_FAS_Menu_ThumbWheel (CM_MFL_Tastencode_2_Cxe_FAS_Menu_ThumbWheel), 16=Cx10_Volume_Up (CM_MFL_Tastencode_2_Cx10_Volume_Up), 17=Cx11_Volume_Down (CM_MFL_Tastencode_2_Cx11_Volume_Down), 18=Cx12_Volume_Up_Down_ThumbWheel (CM_MFL_Tastencode_2_Cx12_Volume_Up_Down_ThumbWheel) (Volume_Up__Down_ThumbWheel), 19=Cx13_Volume_ThumbWheel_Button (CM_MFL_Tastencode_2_Cx13_Volume_ThumbWheel_Button), 20=Cx14_Audio_Source (CM_MFL_Tastencode_2_Cx14_Audio_Source), 21=Cx15_Arrow_A_Up_Right (CM_MFL_Tastencode_2_Cx15_Arrow_A_Up_Right) (Arrow_A_Up__Right), 22=Cx16_Arrow_A_Down_Left (CM_MFL_Tastencode_2_Cx16_Arrow_A_Down_Left) (Arrow_A_Down__Left), 23=Cx17_Arrow_B_Up_Right (CM_MFL_Tastencode_2_Cx17_Arrow_B_Up_Right) (Arrow_B_Up__Right), 24=Cx18_Arrow_B_Down_Left (CM_MFL_Tastencode_2_Cx18_Arrow_B_Down_Left) (Arrow_B_Down__Left), 25=Cx19_PTT_PushToTalk (CM_MFL_Tastencode_2_Cx19_PTT_PushToTalk) (PTT__PushToTalk), 26=Cx1a_PTT_Cancel (CM_MFL_Tastencode_2_Cx1a_PTT_Cancel), 27=Cx1b_Route_Info (CM_MFL_Tastencode_2_Cx1b_Route_Info), 28=Cx1c_Hook (CM_MFL_Tastencode_2_Cx1c_Hook), 29=Cx1d_Hang_Up (CM_MFL_Tastencode_2_Cx1d_Hang_Up), 30=Cx1e_Off_Hook (CM_MFL_Tastencode_2_Cx1e_Off_Hook), 31=Cx1f_Light_On_Off (CM_MFL_Tastencode_2_Cx1f_Light_On_Off) (Light_On__Off), 32=Cx20_Mute (CM_MFL_Tastencode_2_Cx20_Mute), 33=Cx21_Joker1 (CM_MFL_Tastencode_2_Cx21_Joker1), 34=Cx22_Joker2 (CM_MFL_Tastencode_2_Cx22_Joker2), 35=Cx23_View (CM_MFL_Tastencode_2_Cx23_View), 36=Cx24_Arrow_A_Up_Down_ThumbWheel (CM_MFL_Tastencode_2_Cx24_Arrow_A_Up_Down_ThumbWheel) (Arrow_A_Up__Down_ThumbWheel), 37=Cx25_Lenkradheizung (CM_MFL_Tastencode_2_Cx25_Lenkradheizung), 38=Cx26_Rekuperation (CM_MFL_Tastencode_2_Cx26_Rekuperation), 39=Cx27_Tube_Toggle (CM_MFL_Tastencode_2_Cx27_Tube_Toggle), 40=Cx28_DRS_Drag_Reduction_System (CM_MFL_Tastencode_2_Cx28_DRS_Drag_Reduction_System), 41=Cx29_Stopwatch_Start_Stop (CM_MFL_Tastencode_2_Cx29_Stopwatch_Start_Stop), 42=Cx2a_Stopwatch_Nextlap (CM_MFL_Tastencode_2_Cx2a_Stopwatch_Nextlap), 43=Cx2b_HDF_High_Downforce (CM_MFL_Tastencode_2_Cx2b_HDF_High_Downforce), 100=Cx64_MAP (CM_MFL_Tastencode_2_Cx64_MAP), 101=Cx65_MAP_Boost (CM_MFL_Tastencode_2_Cx65_MAP_Boost), 102=Cx66_Turn_signal_left (CM_MFL_Tastencode_2_Cx66_Turn_signal_left), 103=Cx67_Turn_signal_right (CM_MFL_Tastencode_2_Cx67_Turn_signal_right), 104=Cx68_Turn_signal_off (CM_MFL_Tastencode_2_Cx68_Turn_signal_off), 105=Cx69_Flashlight (CM_MFL_Tastencode_2_Cx69_Flashlight), 106=Cx6a_Highbeam (CM_MFL_Tastencode_2_Cx6a_Highbeam), 107=Cx6b_Washer_button (CM_MFL_Tastencode_2_Cx6b_Washer_button), 108=Cx6c_Wiper_button_left (CM_MFL_Tastencode_2_Cx6c_Wiper_button_left), 109=Cx6d_Wiper_button_right (CM_MFL_Tastencode_2_Cx6d_Wiper_button_right), 110=Cx6e_Wiper_button_cancel (CM_MFL_Tastencode_2_Cx6e_Wiper_button_cancel), 111=Cx6f_Exhaust_Sound (CM_MFL_Tastencode_2_Cx6f_Exhaust_Sound), 112=Cx70_Drive_Select_button (CM_MFL_Tastencode_2_Cx70_Drive_Select_button), 113=Cx71_Sport_button (CM_MFL_Tastencode_2_Cx71_Sport_button), 114=Cx72_ESP_Drift_Selection_ThumbWheel (CM_MFL_Tastencode_2_Cx72_ESP_Drift_Selection_ThumbWheel), 115=Cx73_PTT_special_vehicle (CM_MFL_Tastencode_2_Cx73_PTT_special_vehicle), 116=Cx74_TravelAssist (CM_MFL_Tastencode_2_Cx74_TravelAssist), 117=Cx75_Launch_Control (CM_MFL_Tastencode_2_Cx75_Launch_Control), 118=Cx76_Drift_Mode_Button_Increase (CM_MFL_Tastencode_2_Cx76_Drift_Mode_Button_Increase), 119=Cx77_Drift_Mode_Button_Decrease (CM_MFL_Tastencode_2_Cx77_Drift_Mode_Button_Decrease), 120=Cx78_Drift_Mode_Button_Select (CM_MFL_Tastencode_2_Cx78_Drift_Mode_Button_Select), 121=Cx79_Drive_Mode_Button_Increase (CM_MFL_Tastencode_2_Cx79_Drive_Mode_Button_Increase), 122=Cx7a_Drive_Mode_Button_Decrease (CM_MFL_Tastencode_2_Cx7a_Drive_Mode_Button_Decrease), 123=Cx7b_Drive_Mode_Button_Select (CM_MFL_Tastencode_2_Cx7b_Drive_Mode_Button_Select), 124=Cx7c_E_Boost_Button_Increase (CM_MFL_Tastencode_2_Cx7c_E_Boost_Button_Increase), 125=Cx7d_E_Boost_Button_Decrease (CM_MFL_Tastencode_2_Cx7d_E_Boost_Button_Decrease), 126=Cx7e_E_Boost_Button_Select (CM_MFL_Tastencode_2_Cx7e_E_Boost_Button_Select), 127=Cx7f_PerformanceHybridButton_Increase (CM_MFL_Tastencode_2_Cx7f_PerformanceHybridButton_Increase), 128=Cx80_PerformanceHybridButton_Decrease (CM_MFL_Tastencode_2_Cx80_PerformanceHybridButton_Decrease), 129=Cx81_EV_Mode_Button (CM_MFL_Tastencode_2_Cx81_EV_Mode_Button), 130=Cx82_HUD_Button (CM_MFL_Tastencode_2_Cx82_HUD_Button), 131=Cx83_PASM_Wheel (CM_MFL_Tastencode_2_Cx83_PASM_Wheel), 132=Cx84_PASM_Button (CM_MFL_Tastencode_2_Cx84_PASM_Button), 133=Cx85_PTV_Wheel (CM_MFL_Tastencode_2_Cx85_PTV_Wheel), 134=Cx86_PTV_Button (CM_MFL_Tastencode_2_Cx86_PTV_Button), 135=Cx87_TC_ESC_Wheel (CM_MFL_Tastencode_2_Cx87_TC_ESC_Wheel), 136=Cx88_TC_ESC_Button (CM_MFL_Tastencode_2_Cx88_TC_ESC_Button), 137=Cx89_aLDW_Button (CM_MFL_Tastencode_2_Cx89_aLDW_Button), 169=Cxa9_VirtualGearbox_Button (CM_MFL_Tastencode_2_Cxa9_VirtualGearbox_Button), 170=Cxaa_VirtualGearbox_Wheel (CM_MFL_Tastencode_2_Cxaa_VirtualGearbox_Wheel), 240=Cxf0_Startup_Reset (CM_MFL_Tastencode_2_Cxf0_Startup_Reset), 241=Cxf1_Initialization (CM_MFL_Tastencode_2_Cxf1_Initialization)}, range raw 0..241, transfer-property=TRIGGERED-ON-CHANGE-WITHOUT-REPETITION, to Klima  # Beschreibt die Funktion einer fest zugeordneten Taste/Walze auf dem MFL. Ist MFL_Tastencode_1 wegen Betätigung einer Taste/Walze bereits mit einem Wert ungleich 0x0 belegt, so ändert sich bei Betätigung einer weiteren Taste/Walze der Wert dieses Signals von 0x0 auf den jeweiligen Tastencode.
          signal MFL_Eventcode_1_XIX_MFL_Tasten_Kon_01_XIX_E3V_EVCANFD: start 16, 4 bit, little-endian, data-type-policy=OVERRIDE, i-signal-type=PRIMITIVE, init-value=0, base-type=BT_MFL_Eventcode_1, compu {0=Cx0_W_no_event_T_no_event (CM_MFL_Eventcode_1_Cx0_W_no_event_T_no_event) (W_no_event____T_no_event), 1=Cx1_W_1_Tick_up_T_pressed_normal (CM_MFL_Eventcode_1_Cx1_W_1_Tick_up_T_pressed_normal) (W_1_Tick_up__T_pressed_normal), 2=Cx2_W_2_Ticks_up_T_touched (CM_MFL_Eventcode_1_Cx2_W_2_Ticks_up_T_touched) (W_2_Ticks_up__T_touched), 3=Cx3_W_3_Ticks_up_T_double_click_nor (CM_MFL_Eventcode_1_Cx3_W_3_Ticks_up_T_double_click_nor) (W_3_Ticks_up__T_double_click_nor), 4=Cx4_W_4_Ticks_up_T_long_press_nor_1 (CM_MFL_Eventcode_1_Cx4_W_4_Ticks_up_T_long_press_nor_1) (W_4_Ticks_up__T_long_press_nor_1), 5=Cx5_W_5_Ticks_up_T_long_press_nor_2 (CM_MFL_Eventcode_1_Cx5_W_5_Ticks_up_T_long_press_nor_2) (W_5_Ticks_up__T_long_press_nor_2), 6=Cx6_W_6_Ticks_up_T_long_press_nor_3 (CM_MFL_Eventcode_1_Cx6_W_6_Ticks_up_T_long_press_nor_3) (W_6_Ticks_up__T_long_press_nor_3), 7=Cx7_W_7_Ticks_up (CM_MFL_Eventcode_1_Cx7_W_7_Ticks_up), 9=Cx9_W_7_Ticks_dn_T_pressed_strong (CM_MFL_Eventcode_1_Cx9_W_7_Ticks_dn_T_pressed_strong) (W_7_Ticks_dn__T_pressed_strong), 10=Cxa_W_6_Ticks_dn (CM_MFL_Eventcode_1_Cxa_W_6_Ticks_dn), 11=Cxb_W_5_Ticks_dn_T_double_click_str (CM_MFL_Eventcode_1_Cxb_W_5_Ticks_dn_T_double_click_str) (W_5_Ticks_dn__T_double_click_str), 12=Cxc_W_4_Ticks_dn_T_long_press_str_1 (CM_MFL_Eventcode_1_Cxc_W_4_Ticks_dn_T_long_press_str_1) (W_4_Ticks_dn__T_long_press_str_1), 13=Cxd_W_3_Ticks_dn_T_long_press_str_2 (CM_MFL_Eventcode_1_Cxd_W_3_Ticks_dn_T_long_press_str_2) (W_3_Ticks_dn__T_long_press_str_2), 14=Cxe_W_2_Ticks_dn_T_long_press_str_3 (CM_MFL_Eventcode_1_Cxe_W_2_Ticks_dn_T_long_press_str_3) (W_2_Ticks_dn__T_long_press_str_3), 15=Cxf_W_1_Tick_dn (CM_MFL_Eventcode_1_Cxf_W_1_Tick_dn)}, range raw 0..15, transfer-property=TRIGGERED-ON-CHANGE-WITHOUT-REPETITION, to Klima  # Siehe Q-LAH MFL-Protokoll
          signal MFL_Eventcode_2_XIX_MFL_Tasten_Kon_01_XIX_E3V_EVCANFD: start 20, 4 bit, little-endian, data-type-policy=OVERRIDE, i-signal-type=PRIMITIVE, init-value=0, base-type=BT_MFL_Eventcode_2, compu {0=Cx0_W_no_event_T_no_event (CM_MFL_Eventcode_2_Cx0_W_no_event_T_no_event) (W_no_event____T_no_event), 1=Cx1_W_1_Tick_up_T_pressed_normal (CM_MFL_Eventcode_2_Cx1_W_1_Tick_up_T_pressed_normal) (W_1_Tick_up__T_pressed_normal), 2=Cx2_W_2_Ticks_up_T_touched (CM_MFL_Eventcode_2_Cx2_W_2_Ticks_up_T_touched) (W_2_Ticks_up__T_touched), 3=Cx3_W_3_Ticks_up_T_double_click_nor (CM_MFL_Eventcode_2_Cx3_W_3_Ticks_up_T_double_click_nor) (W_3_Ticks_up__T_double_click_nor), 4=Cx4_W_4_Ticks_up_T_long_press_nor_1 (CM_MFL_Eventcode_2_Cx4_W_4_Ticks_up_T_long_press_nor_1) (W_4_Ticks_up__T_long_press_nor_1), 5=Cx5_W_5_Ticks_up_T_long_press_nor_2 (CM_MFL_Eventcode_2_Cx5_W_5_Ticks_up_T_long_press_nor_2) (W_5_Ticks_up__T_long_press_nor_2), 6=Cx6_W_6_Ticks_up_T_long_press_nor_3 (CM_MFL_Eventcode_2_Cx6_W_6_Ticks_up_T_long_press_nor_3) (W_6_Ticks_up__T_long_press_nor_3), 7=Cx7_W_7_Ticks_up (CM_MFL_Eventcode_2_Cx7_W_7_Ticks_up), 9=Cx9_W_7_Ticks_dn_T_pressed_strong (CM_MFL_Eventcode_2_Cx9_W_7_Ticks_dn_T_pressed_strong) (W_7_Ticks_dn__T_pressed_strong), 10=Cxa_W_6_Ticks_dn (CM_MFL_Eventcode_2_Cxa_W_6_Ticks_dn), 11=Cxb_W_5_Ticks_dn_T_double_click_str (CM_MFL_Eventcode_2_Cxb_W_5_Ticks_dn_T_double_click_str) (W_5_Ticks_dn__T_double_click_str), 12=Cxc_W_4_Ticks_dn_T_long_press_str_1 (CM_MFL_Eventcode_2_Cxc_W_4_Ticks_dn_T_long_press_str_1) (W_4_Ticks_dn__T_long_press_str_1), 13=Cxd_W_3_Ticks_dn_T_long_press_str_2 (CM_MFL_Eventcode_2_Cxd_W_3_Ticks_dn_T_long_press_str_2) (W_3_Ticks_dn__T_long_press_str_2), 14=Cxe_W_2_Ticks_dn_T_long_press_str_3 (CM_MFL_Eventcode_2_Cxe_W_2_Ticks_dn_T_long_press_str_3) (W_2_Ticks_dn__T_long_press_str_3), 15=Cxf_W_1_Tick_dn (CM_MFL_Eventcode_2_Cxf_W_1_Tick_dn)}, range raw 0..15, transfer-property=TRIGGERED-ON-CHANGE-WITHOUT-REPETITION, to Klima  # Siehe Q-LAH MFL-Protokoll
          signal MFL_Marke_XIX_MFL_Tasten_Kon_01_XIX_E3V_EVCANFD: start 24, 4 bit, little-endian, data-type-policy=OVERRIDE, i-signal-type=PRIMITIVE, base-type=BT_MFL_Marke, compu {0=Cx0_VW (CM_MFL_Marke_Cx0_VW), 1=Cx1_Audi (CM_MFL_Marke_Cx1_Audi), 2=Cx2_Seat (CM_MFL_Marke_Cx2_Seat), 3=Cx3_Skoda (CM_MFL_Marke_Cx3_Skoda), 4=Cx4_VW_Nutzf (CM_MFL_Marke_Cx4_VW_Nutzf), 5=Cx5_Bugatti (CM_MFL_Marke_Cx5_Bugatti), 6=Cx6_Lamborghini (CM_MFL_Marke_Cx6_Lamborghini), 7=Cx7_Bentley (CM_MFL_Marke_Cx7_Bentley), 8=Cx8_Rolls_Royce (CM_MFL_Marke_Cx8_Rolls_Royce) (Rolls Royce), 9=Cx9_Quattro (CM_MFL_Marke_Cx9_Quattro), 10=Cxa_kein_Hersteller_1 (CM_MFL_Marke_Cxa_kein_Hersteller_1), 11=Cxb_kein_Hersteller_2 (CM_MFL_Marke_Cxb_kein_Hersteller_2), 12=Cxc_kein_Hersteller_3 (CM_MFL_Marke_Cxc_kein_Hersteller_3), 13=Cxd_kein_Hersteller_4 (CM_MFL_Marke_Cxd_kein_Hersteller_4), 14=Cxe_Ford (CM_MFL_Marke_Cxe_Ford), 15=Cxf_Porsche (CM_MFL_Marke_Cxf_Porsche)}, range raw 0..15, transfer-property=PENDING  # Marke für markenspezifische Variantennummer des MFL
          signal MFL_Variante_XIX_MFL_Tasten_Kon_01_XIX_E3V_EVCANFD: start 28, 4 bit, little-endian, data-type-policy=OVERRIDE, i-signal-type=PRIMITIVE, base-type=BT_MFL_Variante, compu {phys=raw for raw 0..15}, range phys 0..15, raw 0..15, transfer-property=PENDING, to Klima  # Markenspezifische Variantennummer des MFL
      frame MIK_01_XIX_E3V_EVCANFD: id 0x12DD5571, to Klima, frame-length=32, can-addressing-mode=EXTENDED, can-frame-rx-behavior=CAN-FD, can-frame-tx-behavior=CAN-FD
        pdu MIK_01_XIX_E3V_EVCANFD: length=32, transmission-mode-true-timing=cyclic-timing={time-offset=0, time-period=0.1}, unused-bit-pattern=0
          signal MIK_01_CRC_XIX_MIK_01_XIX_E3V_EVCANFD: start 0, 8 bit, little-endian, data-type-policy=OVERRIDE, i-signal-type=PRIMITIVE, base-type=BT_MIK_01_CRC, compu {phys=raw for raw 0..255}, range phys 0..255, raw 0..255, transfer-property=PENDING  # Für MLB: Berechnung siehe Lastenheft "Kommunikationsabsicherung für FlexRay und CAN" Ab MQB und MLBevo: Berechnung siehe Lastenheft "End-to-End Kommunikationsabsicherung" Endwerte siehe Begleitdokument "S-PDU Kennungsfolgen"
          signal MIK_01_BZ_XIX_MIK_01_XIX_E3V_EVCANFD: start 8, 4 bit, little-endian, data-type-policy=OVERRIDE, i-signal-type=PRIMITIVE, base-type=BT_MIK_01_BZ, compu {phys=raw for raw 0..15}, range phys 0..15, raw 0..15, transfer-property=PENDING  # 4bit Botschaftszähler, wird mit jeder Sendebotschaft inkrementiert
          signal MIK_Fahrer_erkannt_XIX_MIK_01_XIX_E3V_EVCANFD: start 12, 2 bit, little-endian, data-type-policy=OVERRIDE, i-signal-type=PRIMITIVE, init-value=0, base-type=BT_MIK_Fahrer_erkannt, invalid-value=Invalid_MIK_Fahrer_erkannt_XIX_MIK_01_XIX_E3V_EVCANFD:3, compu {0=Cx0_Init (CM_MIK_Fahrer_erkannt_Cx0_Init), 1=Cx1_Fahrer_nicht_erkannt (CM_MIK_Fahrer_erkannt_Cx1_Fahrer_nicht_erkannt), 2=Cx2_Fahrer_erkannt (CM_MIK_Fahrer_erkannt_Cx2_Fahrer_erkannt), 3=Cx3_Fehler (CM_MIK_Fahrer_erkannt_Cx3_Fehler)}, range raw 0..3, transfer-property=PENDING  # Erkennung der Anwesenheit einer Person auf der Fahrerseite vorne durch die MIK.
          signal MIK_TotDurEyesNotOnTfc_XIX_MIK_01_XIX_E3V_EVCANFD: start 14, 10 bit, little-endian, data-type-policy=OVERRIDE, i-signal-type=PRIMITIVE, init-value=1022, base-type=BT_MIK_TotDurEyesNotOnTfc, compu {phys=raw*0.1 for raw 0..1020, 1021=Cx3fd_Unknown (CM_MIK_TotDurEyesNotOnTfc_Cx3fd_Unknown), 1022=Cx3fe_Init (CM_MIK_TotDurEyesNotOnTfc_Cx3fe_Init), 1023=Cx3ff_Error (CM_MIK_TotDurEyesNotOnTfc_Cx3ff_Error); unit Unit_Secon}, range phys 0..102 Unit_Secon, raw 0..1023, unit=Unit_Secon, transfer-property=PENDING  # Total duration the driver has not paid attention to traffic within a fixed time window including both continuous glances and short glances.
          signal MIK_BlinkRate_XIX_MIK_01_XIX_E3V_EVCANFD: start 24, 5 bit, little-endian, data-type-policy=OVERRIDE, i-signal-type=PRIMITIVE, init-value=30, base-type=BT_MIK_BlinkRate, compu {phys=raw for raw 0..27, 28=Cx1c_Max_value_reached (CM_MIK_BlinkRate_Cx1c_Max_value_reached), 29=Cx1d_Unknown (CM_MIK_BlinkRate_Cx1d_Unknown), 30=Cx1e_Init (CM_MIK_BlinkRate_Cx1e_Init), 31=Cx1f_Error (CM_MIK_BlinkRate_Cx1f_Error); unit Unit_None}, range phys 0..27 Unit_None, raw 0..31, unit=Unit_None, transfer-property=PENDING  # Number of blinks detected within a fixed time window.
          signal MIK_Status_XIX_MIK_01_XIX_E3V_EVCANFD: start 29, 3 bit, little-endian, data-type-policy=OVERRIDE, i-signal-type=PRIMITIVE, init-value=6, base-type=BT_MIK_Status, compu {0=Cx0_Inactive (CM_MIK_Status_Cx0_Inactive), 1=Cx1_Running (CM_MIK_Status_Cx1_Running), 2=Cx2_Not_available (CM_MIK_Status_Cx2_Not_available), 6=Cx6_Init (CM_MIK_Status_Cx6_Init), 7=Cx7_Error (CM_MIK_Status_Cx7_Error)}, range raw 0..7, transfer-property=PENDING  # General status of the driver monitoring system.
          signal MIK_LeftHandPos_XIX_MIK_01_XIX_E3V_EVCANFD: start 32, 4 bit, little-endian, data-type-policy=OVERRIDE, i-signal-type=PRIMITIVE, init-value=14, base-type=BT_MIK_LeftHandPos, compu {0=Cx0_Unknown (CM_MIK_LeftHandPos_Cx0_Unknown), 1=Cx1_Infotainment_display (CM_MIK_LeftHandPos_Cx1_Infotainment_display), 2=Cx2_Center_console (CM_MIK_LeftHandPos_Cx2_Center_console), 3=Cx3_Armrest (CM_MIK_LeftHandPos_Cx3_Armrest), 4=Cx4_Head (CM_MIK_LeftHandPos_Cx4_Head), 5=Cx5_Body (CM_MIK_LeftHandPos_Cx5_Body), 6=Cx6_Rear_view_mirror (CM_MIK_LeftHandPos_Cx6_Rear_view_mirror), 7=Cx7_Sun_visor (CM_MIK_LeftHandPos_Cx7_Sun_visor), 8=Cx8_Driver_door (CM_MIK_LeftHandPos_Cx8_Driver_door), 9=Cx9_Light_switch (CM_MIK_LeftHandPos_Cx9_Light_switch), 10=Cxa_Steering_wheel (CM_MIK_LeftHandPos_Cxa_Steering_wheel), 11=Cxb_Sidewindow_driver (CM_MIK_LeftHandPos_Cxb_Sidewindow_driver), 12=Cxc_Codriver_side (CM_MIK_LeftHandPos_Cxc_Codriver_side), 14=Cxe_Init (CM_MIK_LeftHandPos_Cxe_Init), 15=Cxf_Error (CM_MIK_LeftHandPos_Cxf_Error)}, range raw 0..15, transfer-property=PENDING  # Determines the most likely area of the driver´s left hand.
          signal MIK_LeftHandPosQual_XIX_MIK_01_XIX_E3V_EVCANFD: start 36, 4 bit, little-endian, data-type-policy=OVERRIDE, i-signal-type=PRIMITIVE, init-value=14, base-type=BT_MIK_LeftHandPosQual, compu {phys=raw*10 for raw 0..10, 13=Cxd_Unknown (CM_MIK_LeftHandPosQual_Cxd_Unknown), 14=Cxe_Init (CM_MIK_LeftHandPosQual_Cxe_Init), 15=Cxf_Error (CM_MIK_LeftHandPosQual_Cxf_Error); unit Unit_PerCent}, range phys 0..100 Unit_PerCent, raw 0..15, unit=Unit_PerCent, transfer-property=PENDING  # Confidence factor of signal MIK_LeftHandPos.
          signal MIK_RightHandPos_XIX_MIK_01_XIX_E3V_EVCANFD: start 40, 4 bit, little-endian, data-type-policy=OVERRIDE, i-signal-type=PRIMITIVE, init-value=14, base-type=BT_MIK_RightHandPos, compu {0=Cx0_Unknown (CM_MIK_RightHandPos_Cx0_Unknown), 1=Cx1_Infotainment_display (CM_MIK_RightHandPos_Cx1_Infotainment_display), 2=Cx2_Center_console (CM_MIK_RightHandPos_Cx2_Center_console), 3=Cx3_Armrest (CM_MIK_RightHandPos_Cx3_Armrest), 4=Cx4_Head (CM_MIK_RightHandPos_Cx4_Head), 5=Cx5_Body (CM_MIK_RightHandPos_Cx5_Body), 6=Cx6_Rear_view_mirror (CM_MIK_RightHandPos_Cx6_Rear_view_mirror), 7=Cx7_Sun_visor (CM_MIK_RightHandPos_Cx7_Sun_visor), 8=Cx8_Driver_door (CM_MIK_RightHandPos_Cx8_Driver_door), 9=Cx9_Light_switch (CM_MIK_RightHandPos_Cx9_Light_switch), 10=Cxa_Steering_wheel (CM_MIK_RightHandPos_Cxa_Steering_wheel), 11=Cxb_Sidewindow_driver (CM_MIK_RightHandPos_Cxb_Sidewindow_driver), 12=Cxc_Codriver_side (CM_MIK_RightHandPos_Cxc_Codriver_side), 14=Cxe_Init (CM_MIK_RightHandPos_Cxe_Init), 15=Cxf_Error (CM_MIK_RightHandPos_Cxf_Error)}, range raw 0..15, transfer-property=PENDING  # Determines the most likely area of the driver´s right hand.
          signal MIK_RightHandPosQual_XIX_MIK_01_XIX_E3V_EVCANFD: start 44, 4 bit, little-endian, data-type-policy=OVERRIDE, i-signal-type=PRIMITIVE, init-value=14, base-type=BT_MIK_RightHandPosQual, compu {phys=raw*10 for raw 0..10, 13=Cxd_Unknown (CM_MIK_RightHandPosQual_Cxd_Unknown), 14=Cxe_Init (CM_MIK_RightHandPosQual_Cxe_Init), 15=Cxf_Error (CM_MIK_RightHandPosQual_Cxf_Error); unit Unit_PerCent}, range phys 0..100 Unit_PerCent, raw 0..15, unit=Unit_PerCent, transfer-property=PENDING  # Confidence factor of signal MIK_RightHandPos.
          signal MIK_DrowsinessLevel_XIX_MIK_01_XIX_E3V_EVCANFD: start 48, 4 bit, little-endian, data-type-policy=OVERRIDE, i-signal-type=PRIMITIVE, init-value=14, base-type=BT_MIK_DrowsinessLevel, compu {0=Cx0_Extremely_alert (CM_MIK_DrowsinessLevel_Cx0_Extremely_alert), 1=Cx1_Very_alert (CM_MIK_DrowsinessLevel_Cx1_Very_alert), 2=Cx2_Alert (CM_MIK_DrowsinessLevel_Cx2_Alert), 3=Cx3_Fairly_alert (CM_MIK_DrowsinessLevel_Cx3_Fairly_alert), 4=Cx4_Neither_alert_nor_sleepy (CM_MIK_DrowsinessLevel_Cx4_Neither_alert_nor_sleepy), 5=Cx5_Signs_of_sleepiness (CM_MIK_DrowsinessLevel_Cx5_Signs_of_sleepiness), 6=Cx6_Sleepy_no_effort (CM_MIK_DrowsinessLevel_Cx6_Sleepy_no_effort), 7=Cx7_Sleepy_some_effort (CM_MIK_DrowsinessLevel_Cx7_Sleepy_some_effort), 8=Cx8_Very_Sleepy (CM_MIK_DrowsinessLevel_Cx8_Very_Sleepy), 13=Cxd_Unknown (CM_MIK_DrowsinessLevel_Cxd_Unknown), 14=Cxe_Init (CM_MIK_DrowsinessLevel_Cxe_Init), 15=Cxf_Error (CM_MIK_DrowsinessLevel_Cxf_Error)}, range raw 0..15, transfer-property=PENDING  # Camera-based drowsiness level of the driver.
          signal MIK_DrowsinessLevelQual_XIX_MIK_01_XIX_E3V_EVCANFD: start 52, 4 bit, little-endian, data-type-policy=OVERRIDE, i-signal-type=PRIMITIVE, init-value=14, base-type=BT_MIK_DrowsinessLevelQual, compu {phys=raw*10 for raw 0..10, 13=Cxd_Unknown (CM_MIK_DrowsinessLevelQual_Cxd_Unknown), 14=Cxe_Init (CM_MIK_DrowsinessLevelQual_Cxe_Init), 15=Cxf_Error (CM_MIK_DrowsinessLevelQual_Cxf_Error); unit Unit_PerCent}, range phys 0..100 Unit_PerCent, raw 0..15, unit=Unit_PerCent, transfer-property=PENDING  # Confidence factor of signal MIK_DrowsinessLevel.
          signal MIK_DriverSmoking_XIX_MIK_01_XIX_E3V_EVCANFD: start 56, 3 bit, little-endian, data-type-policy=OVERRIDE, i-signal-type=PRIMITIVE, init-value=6, base-type=BT_MIK_DriverSmoking, compu {0=Cx0_No_driver_smoking (CM_MIK_DriverSmoking_Cx0_No_driver_smoking), 1=Cx1_Driver_smoking (CM_MIK_DriverSmoking_Cx1_Driver_smoking), 5=Cx5_Unknown (CM_MIK_DriverSmoking_Cx5_Unknown), 6=Cx6_Init (CM_MIK_DriverSmoking_Cx6_Init), 7=Cx7_Error (CM_MIK_DriverSmoking_Cx7_Error)}, range raw 0..7, transfer-property=PENDING  # Determines whether the driver is smoking.
          signal MIK_PassengerPresence_XIX_MIK_01_XIX_E3V_EVCANFD: start 59, 1 bit, little-endian, data-type-policy=OVERRIDE, i-signal-type=PRIMITIVE, init-value=0, base-type=BT_MIK_PassengerPresence, compu {0=Cx0_No_passenger_present (CM_MIK_PassengerPresence_Cx0_No_passenger_present), 1=Cx1_Passenger_present (CM_MIK_PassengerPresence_Cx1_Passenger_present)}, range raw 0..1, transfer-property=PENDING  # Determines whether passengers have been detected in the car.
          signal MIK_DriverSmokingQual_XIX_MIK_01_XIX_E3V_EVCANFD: start 60, 4 bit, little-endian, data-type-policy=OVERRIDE, i-signal-type=PRIMITIVE, init-value=14, base-type=BT_MIK_DriverSmokingQual, compu {phys=raw*10 for raw 0..10, 13=Cxd_Unknown (CM_MIK_DriverSmokingQual_Cxd_Unknown), 14=Cxe_Init (CM_MIK_DriverSmokingQual_Cxe_Init), 15=Cxf_Error (CM_MIK_DriverSmokingQual_Cxf_Error); unit Unit_PerCent}, range phys 0..100 Unit_PerCent, raw 0..15, unit=Unit_PerCent, transfer-property=PENDING  # Confidence factor of signal MIK_DriverSmoking.
          signal MIK_DriverTelephoneUsage_XIX_MIK_01_XIX_E3V_EVCANFD: start 64, 3 bit, little-endian, data-type-policy=OVERRIDE, i-signal-type=PRIMITIVE, init-value=6, base-type=BT_MIK_DriverTelephoneUsage, compu {0=Cx0_No_telephone_usage (CM_MIK_DriverTelephoneUsage_Cx0_No_telephone_usage), 1=Cx1_Telephone_usage (CM_MIK_DriverTelephoneUsage_Cx1_Telephone_usage), 5=Cx5_Unknown (CM_MIK_DriverTelephoneUsage_Cx5_Unknown), 6=Cx6_Init (CM_MIK_DriverTelephoneUsage_Cx6_Init), 7=Cx7_Error (CM_MIK_DriverTelephoneUsage_Cx7_Error)}, range raw 0..7, transfer-property=PENDING  # Determines whether the driver use continuously the mobile phone.
          signal MIK_DriverSpeaking_XIX_MIK_01_XIX_E3V_EVCANFD: start 67, 1 bit, little-endian, data-type-policy=OVERRIDE, i-signal-type=PRIMITIVE, init-value=0, base-type=BT_MIK_DriverSpeaking, compu {0=Cx0_Driver_not_speaking (CM_MIK_DriverSpeaking_Cx0_Driver_not_speaking), 1=Cx1_Driver_speaking (CM_MIK_DriverSpeaking_Cx1_Driver_speaking)}, range raw 0..1, transfer-property=PENDING  # Determines whether the driver is speaking.
          signal MIK_DriverTelephoneUsageQual_XIX_MIK_01_XIX_E3V_EVCANFD: start 68, 4 bit, little-endian, data-type-policy=OVERRIDE, i-signal-type=PRIMITIVE, init-value=14, base-type=BT_MIK_DriverTelephoneUsageQual, compu {phys=raw*10 for raw 0..10, 13=Cxd_Unknown (CM_MIK_DriverTelephoneUsageQual_Cxd_Unknown), 14=Cxe_Init (CM_MIK_DriverTelephoneUsageQual_Cxe_Init), 15=Cxf_Error (CM_MIK_DriverTelephoneUsageQual_Cxf_Error); unit Unit_PerCent}, range phys 0..100 Unit_PerCent, raw 0..15, unit=Unit_PerCent, transfer-property=PENDING  # Confidence factor of signal MIK_DriverTelephoneUsage.
          signal MIK_DriverYawning_XIX_MIK_01_XIX_E3V_EVCANFD: start 72, 3 bit, little-endian, data-type-policy=OVERRIDE, i-signal-type=PRIMITIVE, init-value=6, base-type=BT_MIK_DriverYawning, compu {0=Cx0_No_driver_yawning (CM_MIK_DriverYawning_Cx0_No_driver_yawning), 1=Cx1_Driver_yawning (CM_MIK_DriverYawning_Cx1_Driver_yawning), 5=Cx5_Unknown (CM_MIK_DriverYawning_Cx5_Unknown), 6=Cx6_Init (CM_MIK_DriverYawning_Cx6_Init), 7=Cx7_Error (CM_MIK_DriverYawning_Cx7_Error)}, range raw 0..7, transfer-property=PENDING  # Determines whether the driver is yawning.
          signal FaceRec_Auth_Challenge_Request_XIX_MIK_01_XIX_E3V_EVCANFD: start 75, 1 bit, little-endian, data-type-policy=OVERRIDE, i-signal-type=PRIMITIVE, init-value=0, base-type=BT_FaceRec_Auth_Challenge_Request, compu {0=Cx0_SEND_NOTHING (CM_FaceRec_Auth_Challenge_Request_Cx0_SEND_NOTHING), 1=Cx1_SEND_CHALLENGE (CM_FaceRec_Auth_Challenge_Request_Cx1_SEND_CHALLENGE)}, range raw 0..1, transfer-property=PENDING  # When IAA receives this signal it will provide a challenge via SOK_FR_Auth_NAD_Challenge.
          signal MIK_DriverYawningQual_XIX_MIK_01_XIX_E3V_EVCANFD: start 76, 4 bit, little-endian, data-type-policy=OVERRIDE, i-signal-type=PRIMITIVE, init-value=14, base-type=BT_MIK_DriverYawningQual, compu {phys=raw*10 for raw 0..10, 13=Cxd_Unknown (CM_MIK_DriverYawningQual_Cxd_Unknown), 14=Cxe_Init (CM_MIK_DriverYawningQual_Cxe_Init), 15=Cxf_Error (CM_MIK_DriverYawningQual_Cxf_Error); unit Unit_PerCent}, range phys 0..100 Unit_PerCent, raw 0..15, unit=Unit_PerCent, transfer-property=PENDING  # Confidence factor of signal MIK_DriverYawning.
          signal MIK_Microsleep_XIX_MIK_01_XIX_E3V_EVCANFD: start 80, 3 bit, little-endian, data-type-policy=OVERRIDE, i-signal-type=PRIMITIVE, init-value=6, base-type=BT_MIK_Microsleep, compu {0=Cx0_No_microsleep_detected (CM_MIK_Microsleep_Cx0_No_microsleep_detected), 1=Cx1_Microsleep_imminent (CM_MIK_Microsleep_Cx1_Microsleep_imminent), 2=Cx2_Microsleep_detected (CM_MIK_Microsleep_Cx2_Microsleep_detected), 5=Cx5_Unknown (CM_MIK_Microsleep_Cx5_Unknown), 6=Cx6_Init (CM_MIK_Microsleep_Cx6_Init), 7=Cx7_Error (CM_MIK_Microsleep_Cx7_Error)}, range raw 0..7, transfer-property=PENDING  # Camera-based microsleep detection.
          signal MIK_MicrosleepQual_XIX_MIK_01_XIX_E3V_EVCANFD: start 84, 4 bit, little-endian, data-type-policy=OVERRIDE, i-signal-type=PRIMITIVE, init-value=14, base-type=BT_MIK_MicrosleepQual, compu {phys=raw*10 for raw 0..10, 13=Cxd_Unknown (CM_MIK_MicrosleepQual_Cxd_Unknown), 14=Cxe_Init (CM_MIK_MicrosleepQual_Cxe_Init), 15=Cxf_Error (CM_MIK_MicrosleepQual_Cxf_Error); unit Unit_PerCent}, range phys 0..100 Unit_PerCent, raw 0..15, unit=Unit_PerCent, transfer-property=PENDING  # Confidence factor of signal MIK_Microsleep.
          signal MIK_UnusualHeadPose_XIX_MIK_01_XIX_E3V_EVCANFD: start 88, 3 bit, little-endian, data-type-policy=OVERRIDE, i-signal-type=PRIMITIVE, init-value=6, base-type=BT_MIK_UnusualHeadPose, compu {0=Cx0_No_unusual_head_pose (CM_MIK_UnusualHeadPose_Cx0_No_unusual_head_pose), 1=Cx1_Unusual_head_pose (CM_MIK_UnusualHeadPose_Cx1_Unusual_head_pose), 5=Cx5_Unknown (CM_MIK_UnusualHeadPose_Cx5_Unknown), 6=Cx6_Init (CM_MIK_UnusualHeadPose_Cx6_Init), 7=Cx7_Error (CM_MIK_UnusualHeadPose_Cx7_Error)}, range raw 0..7, transfer-property=PENDING  # Determines whether the driver's head is detected to be in an unusual pose.
          signal MIK_PetsMode_state_XIX_MIK_01_XIX_E3V_EVCANFD: start 91, 1 bit, little-endian, data-type-policy=OVERRIDE, i-signal-type=PRIMITIVE, init-value=0, base-type=BT_MIK_PetsMode_state, compu {0=Cx0_Off (CM_MIK_PetsMode_state_Cx0_Off), 1=Cx1_On (CM_MIK_PetsMode_state_Cx1_On)}, range raw 0..1, transfer-property=PENDING, to Klima(timeout 1 s)  # pets mode state
          signal MIK_UnusualHeadPoseQual_XIX_MIK_01_XIX_E3V_EVCANFD: start 92, 4 bit, little-endian, data-type-policy=OVERRIDE, i-signal-type=PRIMITIVE, init-value=14, base-type=BT_MIK_UnusualHeadPoseQual, compu {phys=raw*10 for raw 0..10, 13=Cxd_Unknown (CM_MIK_UnusualHeadPoseQual_Cxd_Unknown), 14=Cxe_Init (CM_MIK_UnusualHeadPoseQual_Cxe_Init), 15=Cxf_Error (CM_MIK_UnusualHeadPoseQual_Cxf_Error); unit Unit_PerCent}, range phys 0..100 Unit_PerCent, raw 0..15, unit=Unit_PerCent, transfer-property=PENDING  # Confidence factor of signal MIK_UnusualHeadPose.
          signal MIK_VisualDistractionLevel_XIX_MIK_01_XIX_E3V_EVCANFD: start 96, 3 bit, little-endian, data-type-policy=OVERRIDE, i-signal-type=PRIMITIVE, init-value=6, base-type=BT_MIK_VisualDistractionLevel, compu {0=Cx0_Not_distracted (CM_MIK_VisualDistractionLevel_Cx0_Not_distracted), 1=Cx1_Slightly_distracted (CM_MIK_VisualDistractionLevel_Cx1_Slightly_distracted), 2=Cx2_Distracted (CM_MIK_VisualDistractionLevel_Cx2_Distracted), 3=Cx3_Very_distracted (CM_MIK_VisualDistractionLevel_Cx3_Very_distracted), 5=Cx5_Unknown (CM_MIK_VisualDistractionLevel_Cx5_Unknown), 6=Cx6_Init (CM_MIK_VisualDistractionLevel_Cx6_Init), 7=Cx7_Error (CM_MIK_VisualDistractionLevel_Cx7_Error)}, range raw 0..7, transfer-property=PENDING  # Camera-based visual distraction of the driver.
          signal MIK_VisualDistractionLevelQual_XIX_MIK_01_XIX_E3V_EVCANFD: start 100, 4 bit, little-endian, data-type-policy=OVERRIDE, i-signal-type=PRIMITIVE, init-value=14, base-type=BT_MIK_VisualDistractionLevelQual, compu {phys=raw*10 for raw 0..10, 13=Cxd_Unknown (CM_MIK_VisualDistractionLevelQual_Cxd_Unknown), 14=Cxe_Init (CM_MIK_VisualDistractionLevelQual_Cxe_Init), 15=Cxf_Error (CM_MIK_VisualDistractionLevelQual_Cxf_Error); unit Unit_PerCent}, range phys 0..100 Unit_PerCent, raw 0..15, unit=Unit_PerCent, transfer-property=PENDING  # Confidence factor of signal MIK_VisualDistractionLevel.
          signal MIK_DurEyesNotOnTfc_XIX_MIK_01_XIX_E3V_EVCANFD: start 104, 9 bit, little-endian, data-type-policy=OVERRIDE, i-signal-type=PRIMITIVE, init-value=510, base-type=BT_MIK_DurEyesNotOnTfc, compu {phys=raw*0.1 for raw 0..507, 508=Cx1fc_Max_value_reached (CM_MIK_DurEyesNotOnTfc_Cx1fc_Max_value_reached), 509=Cx1fd_Unknown (CM_MIK_DurEyesNotOnTfc_Cx1fd_Unknown), 510=Cx1fe_Init (CM_MIK_DurEyesNotOnTfc_Cx1fe_Init), 511=Cx1ff_Error (CM_MIK_DurEyesNotOnTfc_Cx1ff_Error); unit Unit_Secon}, range phys 0..50.7 Unit_Secon, raw 0..511, unit=Unit_Secon, transfer-property=PENDING  # Duration the driver has continuously not paid attention to traffic.
          signal MIK_DurEyesCl_XIX_MIK_01_XIX_E3V_EVCANFD: start 113, 7 bit, little-endian, data-type-policy=OVERRIDE, i-signal-type=PRIMITIVE, init-value=126, base-type=BT_MIK_DurEyesCl, compu {phys=raw*0.1 for raw 0..123, 124=Cx7c_Max_value_reached (CM_MIK_DurEyesCl_Cx7c_Max_value_reached), 125=Cx7d_Unknown (CM_MIK_DurEyesCl_Cx7d_Unknown), 126=Cx7e_Init (CM_MIK_DurEyesCl_Cx7e_Init), 127=Cx7f_Error (CM_MIK_DurEyesCl_Cx7f_Error); unit Unit_Secon}, range phys 0..12.3 Unit_Secon, raw 0..127, unit=Unit_Secon, transfer-property=PENDING  # Duration the driver's eyes have been continuously closed.
          signal MIK_PercentageEyesOnTraffic_XIX_MIK_01_XIX_E3V_EVCANFD: start 120, 7 bit, little-endian, data-type-policy=OVERRIDE, i-signal-type=PRIMITIVE, init-value=126, base-type=BT_MIK_PercentageEyesOnTraffic, compu {phys=raw for raw 0..100, 125=Cx7d_Unknown (CM_MIK_PercentageEyesOnTraffic_Cx7d_Unknown), 126=Cx7e_Init (CM_MIK_PercentageEyesOnTraffic_Cx7e_Init), 127=Cx7f_Error (CM_MIK_PercentageEyesOnTraffic_Cx7f_Error); unit Unit_PerCent}, range phys 0..100 Unit_PerCent, raw 0..127, unit=Unit_PerCent, transfer-property=PENDING  # Relative duration the driver has monitored the traffic within a fixed time window.
          signal MIK_SpaAttDstrAr_01_XIX_MIK_01_XIX_E3V_EVCANFD: start 127, 5 bit, little-endian, data-type-policy=OVERRIDE, i-signal-type=PRIMITIVE, init-value=30, base-type=BT_MIK_SpaAttDstrAr_01, compu {0=Cx0_Unknown (CM_MIK_SpaAttDstrAr_01_Cx0_Unknown), 1=Cx1_Sidewindow_driver (CM_MIK_SpaAttDstrAr_01_Cx1_Sidewindow_driver), 2=Cx2_Windshield_top_roof (CM_MIK_SpaAttDstrAr_01_Cx2_Windshield_top_roof), 3=Cx3_Windshield_driver_side (CM_MIK_SpaAttDstrAr_01_Cx3_Windshield_driver_side), 4=Cx4_Rear (CM_MIK_SpaAttDstrAr_01_Cx4_Rear), 5=Cx5_Windshield_codriver_side (CM_MIK_SpaAttDstrAr_01_Cx5_Windshield_codriver_side), 6=Cx6_Sidewindow_codriver (CM_MIK_SpaAttDstrAr_01_Cx6_Sidewindow_codriver), 7=Cx7_Bottom_codriver (CM_MIK_SpaAttDstrAr_01_Cx7_Bottom_codriver), 8=Cx8_Sidemirror_driver (CM_MIK_SpaAttDstrAr_01_Cx8_Sidemirror_driver), 9=Cx9_Sidemirror_codriver (CM_MIK_SpaAttDstrAr_01_Cx9_Sidemirror_codriver), 10=Cxa_Rear_view_mirror (CM_MIK_SpaAttDstrAr_01_Cxa_Rear_view_mirror), 11=Cxb_Instrument_cluster (CM_MIK_SpaAttDstrAr_01_Cxb_Instrument_cluster), 12=Cxc_Dashboard_top (CM_MIK_SpaAttDstrAr_01_Cxc_Dashboard_top), 13=Cxd_Steering_wheel (CM_MIK_SpaAttDstrAr_01_Cxd_Steering_wheel), 14=Cxe_Infotainment_display (CM_MIK_SpaAttDstrAr_01_Cxe_Infotainment_display), 15=Cxf_Center_console (CM_MIK_SpaAttDstrAr_01_Cxf_Center_console), 16=Cx10_Bottom_driver (CM_MIK_SpaAttDstrAr_01_Cx10_Bottom_driver), 17=Cx11_Glovebox_dashboard_codriver (CM_MIK_SpaAttDstrAr_01_Cx11_Glovebox_dashboard_codriver), 18=Cx12_Door_driver (CM_MIK_SpaAttDstrAr_01_Cx12_Door_driver), 19=Cx13_Door_codriver (CM_MIK_SpaAttDstrAr_01_Cx13_Door_codriver), 30=Cx1e_Init (CM_MIK_SpaAttDstrAr_01_Cx1e_Init), 31=Cx1f_Error (CM_MIK_SpaAttDstrAr_01_Cx1f_Error)}, range raw 0..31, transfer-property=PENDING  # Spatial Attention Distribution Area 1: Most likely Area of Interest the driver is currently looking at.
          signal MIK_SpaAttDstrProb_01_XIX_MIK_01_XIX_E3V_EVCANFD: start 132, 4 bit, little-endian, data-type-policy=OVERRIDE, i-signal-type=PRIMITIVE, init-value=14, base-type=BT_MIK_SpaAttDstrProb_01, compu {phys=raw*10 for raw 0..10, 13=Cxd_Unknown (CM_MIK_SpaAttDstrProb_01_Cxd_Unknown), 14=Cxe_Init (CM_MIK_SpaAttDstrProb_01_Cxe_Init), 15=Cxf_Error (CM_MIK_SpaAttDstrProb_01_Cxf_Error); unit Unit_PerCent}, range phys 0..100 Unit_PerCent, raw 0..15, unit=Unit_PerCent, transfer-property=PENDING  # Spatial Attention Distribution Probability 1: Probability the driver is currently looking at the Area of Interest given in signal 'MIK_SpaAttDstrAr_01'.
          signal MIK_DetectionMode_XIX_MIK_01_XIX_E3V_EVCANFD: start 136, 3 bit, little-endian, data-type-policy=OVERRIDE, i-signal-type=PRIMITIVE, init-value=6, base-type=BT_MIK_DetectionMode, compu {0=Cx0_Gaze (CM_MIK_DetectionMode_Cx0_Gaze), 1=Cx1_Head_pose (CM_MIK_DetectionMode_Cx1_Head_pose), 2=Cx2_Combined (CM_MIK_DetectionMode_Cx2_Combined), 5=Cx5_Unknown (CM_MIK_DetectionMode_Cx5_Unknown), 6=Cx6_Init (CM_MIK_DetectionMode_Cx6_Init), 7=Cx7_Error (CM_MIK_DetectionMode_Cx7_Error)}, range raw 0..7, transfer-property=PENDING  # Indicates whether head pose, gaze, or a combination of head pose and gaze is used for visual perception estimation.
          signal MIK_DriverChange_XIX_MIK_01_XIX_E3V_EVCANFD: start 139, 1 bit, little-endian, data-type-policy=OVERRIDE, i-signal-type=PRIMITIVE, init-value=0, base-type=BT_MIK_DriverChange, compu {0=Cx0_No_driver_change_detected (CM_MIK_DriverChange_Cx0_No_driver_change_detected), 1=Cx1_Driver_change_detected (CM_MIK_DriverChange_Cx1_Driver_change_detected)}, range raw 0..1, transfer-property=PENDING  # Determines whether a driver change has been detected.
          signal MIK_DriverPresence_XIX_MIK_01_XIX_E3V_EVCANFD: start 140, 3 bit, little-endian, data-type-policy=OVERRIDE, i-signal-type=PRIMITIVE, init-value=6, base-type=BT_MIK_DriverPresence, compu {0=Cx0_No_driver_present (CM_MIK_DriverPresence_Cx0_No_driver_present), 1=Cx1_Driver_present (CM_MIK_DriverPresence_Cx1_Driver_present), 2=Cx2_Driver_present_and_buckled (CM_MIK_DriverPresence_Cx2_Driver_present_and_buckled), 5=Cx5_Unknown (CM_MIK_DriverPresence_Cx5_Unknown), 6=Cx6_Init (CM_MIK_DriverPresence_Cx6_Init), 7=Cx7_Error (CM_MIK_DriverPresence_Cx7_Error)}, range raw 0..7, transfer-property=PENDING  # Determines whether a driver has been detected on the driver seat and whether the driver is buckled up.
          signal MIK_FakeDetected_XIX_MIK_01_XIX_E3V_EVCANFD: start 143, 1 bit, little-endian, data-type-policy=OVERRIDE, i-signal-type=PRIMITIVE, init-value=0, base-type=BT_MIK_FakeDetected, compu {0=Cx0_No_fake_detected (CM_MIK_FakeDetected_Cx0_No_fake_detected), 1=Cx1_Fake_detected (CM_MIK_FakeDetected_Cx1_Fake_detected)}, range raw 0..1, transfer-property=PENDING  # Indicates whether or not the driver monitoring system has detected an attempt at deception (e.g. masks).
          signal MIK_ICV_Brightness_XIX_MIK_01_XIX_E3V_EVCANFD: start 144, 7 bit, little-endian, data-type-policy=OVERRIDE, i-signal-type=PRIMITIVE, init-value=126, base-type=BT_MIK_ICV_Brightness, compu {phys=raw for raw 0..100, 126=Cx7e_init (CM_MIK_ICV_Brightness_Cx7e_init); unit Unit_PerCent}, range phys 0..100 Unit_PerCent, raw 0..126, unit=Unit_PerCent, transfer-property=PENDING  # MIK_ICV_Brightness the brightness of the videostream shall be configurable (0....100%)
          signal MIK_ICV_FrameRate_XIX_MIK_01_XIX_E3V_EVCANFD: start 151, 5 bit, little-endian, data-type-policy=OVERRIDE, i-signal-type=PRIMITIVE, init-value=31, base-type=BT_MIK_ICV_FrameRate, compu {phys=raw for raw 15..30, 31=Cx1f_init (CM_MIK_ICV_FrameRate_Cx1f_init); unit Unit_SeconInver}, range phys 15..30 Unit_SeconInver, raw 15..31, unit=Unit_SeconInver, transfer-property=PENDING  # MIK_ICV_FrameRate [15...30 frames per second]
          signal MIK_ICV_FieldOfView_XIX_MIK_01_XIX_E3V_EVCANFD: start 156, 2 bit, little-endian, data-type-policy=OVERRIDE, i-signal-type=PRIMITIVE, init-value=0, base-type=BT_MIK_ICV_FieldOfView, compu {0=Cx0_init (CM_MIK_ICV_FieldOfView_Cx0_init), 1=Cx1_show_Driver (CM_MIK_ICV_FieldOfView_Cx1_show_Driver), 2=Cx2_show_CoDriver (CM_MIK_ICV_FieldOfView_Cx2_show_CoDriver), 3=Cx3_show_fullCabine (CM_MIK_ICV_FieldOfView_Cx3_show_fullCabine)}, range raw 0..3, transfer-property=PENDING  # MIK_ICV_FieldOfView is needed to report the selected field of view (driver, CoDriver and fullCabine)
          signal MIK_ICV_FunctionState_XIX_MIK_01_XIX_E3V_EVCANFD: start 158, 2 bit, little-endian, data-type-policy=OVERRIDE, i-signal-type=PRIMITIVE, init-value=0, base-type=BT_MIK_ICV_FunctionState, compu {0=Cx0_init (CM_MIK_ICV_FunctionState_Cx0_init), 1=Cx1_started (CM_MIK_ICV_FunctionState_Cx1_started), 2=Cx2_shutDown (CM_MIK_ICV_FunctionState_Cx2_shutDown), 3=Cx3_error (CM_MIK_ICV_FunctionState_Cx3_error)}, range raw 0..3, transfer-property=PENDING  # MIK_ICV_FunctionState is needed to report the current state of the MIK (started, shutDown or error)
          signal MIK_ICV_Resolution_XIX_MIK_01_XIX_E3V_EVCANFD: start 160, 3 bit, little-endian, data-type-policy=OVERRIDE, i-signal-type=PRIMITIVE, init-value=0, base-type=BT_MIK_ICV_Resolution, compu {0=Cx0_Init (CM_MIK_ICV_Resolution_Cx0_Init), 1=Cx1_Aufloesung_160x120 (CM_MIK_ICV_Resolution_Cx1_Aufloesung_160x120), 2=Cx2_Aufloesung_320x240 (CM_MIK_ICV_Resolution_Cx2_Aufloesung_320x240), 3=Cx3_Aufloesung_640x480 (CM_MIK_ICV_Resolution_Cx3_Aufloesung_640x480), 4=Cx4_Aufloesung_1280x720 (CM_MIK_ICV_Resolution_Cx4_Aufloesung_1280x720), 5=Cx5_Aufloesung_1920x1080 (CM_MIK_ICV_Resolution_Cx5_Aufloesung_1920x1080)}, range raw 0..5, transfer-property=PENDING  # the resolution of the videostream shall be configurable 160x120, 320x240, 640x480,1280x720, 1920x1080
          signal MIK_ICV_Videostream_State_XIX_MIK_01_XIX_E3V_EVCANFD: start 163, 3 bit, little-endian, data-type-policy=OVERRIDE, i-signal-type=PRIMITIVE, init-value=0, base-type=BT_MIK_ICV_Videostream_State, compu {0=Cx0_init (CM_MIK_ICV_Videostream_State_Cx0_init), 1=Cx1_on (CM_MIK_ICV_Videostream_State_Cx1_on), 2=Cx2_off (CM_MIK_ICV_Videostream_State_Cx2_off), 3=Cx3_blurred (CM_MIK_ICV_Videostream_State_Cx3_blurred), 4=Cx4_standby (CM_MIK_ICV_Videostream_State_Cx4_standby), 5=Cx5_freezed (CM_MIK_ICV_Videostream_State_Cx5_freezed), 6=Cx6_error (CM_MIK_ICV_Videostream_State_Cx6_error)}, range raw 0..6, transfer-property=PENDING  # MIK_ICV_Videostream_State is needed to report the state of the videostream.
          signal MIK_ICV_VideostreamResult_XIX_MIK_01_XIX_E3V_EVCANFD: start 166, 2 bit, little-endian, data-type-policy=OVERRIDE, i-signal-type=PRIMITIVE, init-value=0, base-type=BT_MIK_ICV_VideostreamResult, compu {0=Cx0_init (CM_MIK_ICV_VideostreamResult_Cx0_init), 1=Cx1_started (CM_MIK_ICV_VideostreamResult_Cx1_started), 2=Cx2_freezed (CM_MIK_ICV_VideostreamResult_Cx2_freezed), 3=Cx3_cancelled (CM_MIK_ICV_VideostreamResult_Cx3_cancelled)}, range raw 0..3, transfer-property=PENDING  # MIK_ICV_VideostreamResult is needed to provide the result of the videostream (started, cancelled or freezed)
          signal MIK_ICV_ColorMode_XIX_MIK_01_XIX_E3V_EVCANFD: start 168, 2 bit, little-endian, data-type-policy=OVERRIDE, i-signal-type=PRIMITIVE, init-value=0, base-type=BT_MIK_ICV_ColorMode, compu {0=Cx0_init (CM_MIK_ICV_ColorMode_Cx0_init), 1=Cx1_RGB (CM_MIK_ICV_ColorMode_Cx1_RGB), 2=Cx2_IR (CM_MIK_ICV_ColorMode_Cx2_IR)}, range raw 0..2, transfer-property=PENDING  # The color mode of the videostream shall be configurable (init, RGB, IR)
          signal MIK_ICV_HDR_XIX_MIK_01_XIX_E3V_EVCANFD: start 170, 2 bit, little-endian, data-type-policy=OVERRIDE, i-signal-type=PRIMITIVE, init-value=0, base-type=BT_MIK_ICV_HDR, compu {0=Cx0_init (CM_MIK_ICV_HDR_Cx0_init), 1=Cx1_on (CM_MIK_ICV_HDR_Cx1_on), 2=Cx2_off (CM_MIK_ICV_HDR_Cx2_off)}, range raw 0..2, transfer-property=PENDING  # The HDR (High Dynamic Range Image) of the videostream shall be configurable (init, on, off).
          signal MIK_ICV_Contrast_XIX_MIK_01_XIX_E3V_EVCANFD: start 172, 7 bit, little-endian, data-type-policy=OVERRIDE, i-signal-type=PRIMITIVE, init-value=126, base-type=BT_MIK_ICV_Contrast, compu {phys=raw for raw 0..100, 126=Cx7e_init (CM_MIK_ICV_Contrast_Cx7e_init); unit Unit_PerCent}, range phys 0..100 Unit_PerCent, raw 0..126, unit=Unit_PerCent, transfer-property=PENDING  # the contrast of the videostream shall be configurable [0...100%]
          signal MIK_Selfie_FunctionState_XIX_MIK_01_XIX_E3V_EVCANFD: start 179, 3 bit, little-endian, data-type-policy=OVERRIDE, i-signal-type=PRIMITIVE, init-value=0, base-type=BT_MIK_Selfie_FunctionState, compu {0=Cx0_init (CM_MIK_Selfie_FunctionState_Cx0_init), 1=Cx1_VideoShot_Start (CM_MIK_Selfie_FunctionState_Cx1_VideoShot_Start), 2=Cx2_VideoShot_Stop (CM_MIK_Selfie_FunctionState_Cx2_VideoShot_Stop), 3=Cx3_PhotoShot_Single (CM_MIK_Selfie_FunctionState_Cx3_PhotoShot_Single), 4=Cx4_PhotoShot_Continuous (CM_MIK_Selfie_FunctionState_Cx4_PhotoShot_Continuous), 5=Cx5_Cancel (CM_MIK_Selfie_FunctionState_Cx5_Cancel), 6=Cx6_Error (CM_MIK_Selfie_FunctionState_Cx6_Error)}, range raw 0..6, transfer-property=PENDING  # This signal is needed to report the Selfie function state(init, VideoShot_Start, VideoShot_Stop, PhotoShot_Single, PhotoShot_Continuous, Cancel, Error)
          signal MIK_Selfie_Resolution_XIX_MIK_01_XIX_E3V_EVCANFD: start 182, 2 bit, little-endian, data-type-policy=OVERRIDE, i-signal-type=PRIMITIVE, init-value=0, base-type=BT_MIK_Selfie_Resolution, compu {0=Cx0_init (CM_MIK_Selfie_Resolution_Cx0_init), 1=Cx1_Res_5M_pixels (CM_MIK_Selfie_Resolution_Cx1_Res_5M_pixels), 2=Cx2_Res_2M_pixels (CM_MIK_Selfie_Resolution_Cx2_Res_2M_pixels)}, range raw 0..2, transfer-property=PENDING  # This signal is needed to report the image's resolution (int, 5M pixels, 2M pixels)
          signal MIK_ICV_AspectRatio_XIX_MIK_01_XIX_E3V_EVCANFD: start 184, 3 bit, little-endian, data-type-policy=OVERRIDE, i-signal-type=PRIMITIVE, init-value=0, base-type=BT_MIK_ICV_AspectRatio, compu {0=Cx0_init (CM_MIK_ICV_AspectRatio_Cx0_init), 1=Cx1_AspectRatio_4_3 (CM_MIK_ICV_AspectRatio_Cx1_AspectRatio_4_3), 2=Cx2_AspectRatio_16_9 (CM_MIK_ICV_AspectRatio_Cx2_AspectRatio_16_9), 3=Cx3_AspectRatio_3_4 (CM_MIK_ICV_AspectRatio_Cx3_AspectRatio_3_4), 4=Cx4_AspectRatio_9_16 (CM_MIK_ICV_AspectRatio_Cx4_AspectRatio_9_16)}, range raw 0..4, transfer-property=PENDING  # This signal is needed to report the image and video's aspect ratio(init, 4:3, 16:9, 3:4, 9:16)
          signal MIK_ICV_VideoLength_XIX_MIK_01_XIX_E3V_EVCANFD: start 187, 3 bit, little-endian, data-type-policy=OVERRIDE, i-signal-type=PRIMITIVE, init-value=0, base-type=BT_MIK_ICV_VideoLength, compu {0=Cx0_init (CM_MIK_ICV_VideoLength_Cx0_init), 1=Cx1_Lenght_15s (CM_MIK_ICV_VideoLength_Cx1_Lenght_15s), 2=Cx2_Lenght_30s (CM_MIK_ICV_VideoLength_Cx2_Lenght_30s), 3=Cx3_Lenght_60s (CM_MIK_ICV_VideoLength_Cx3_Lenght_60s), 4=Cx4_customized (CM_MIK_ICV_VideoLength_Cx4_customized)}, range raw 0..4, transfer-property=PENDING  # This signal is needed to report the short video length to fits the social media directly. e.g. Tiktok, wechat. (init, 15s, 30s, 60s, customized)
          signal MIK_ChildStatus_XIX_MIK_01_XIX_E3V_EVCANFD: start 190, 2 bit, little-endian, data-type-policy=OVERRIDE, i-signal-type=PRIMITIVE, init-value=0, base-type=BT_MIK_ChildStatus, compu {0=Cx0_init (CM_MIK_ChildStatus_Cx0_init), 1=Cx1_awake (CM_MIK_ChildStatus_Cx1_awake), 2=Cx2_sleep (CM_MIK_ChildStatus_Cx2_sleep)}, range raw 0..2, transfer-property=PENDING  # child status signal
          signal MIK_PetPresence_XIX_MIK_01_XIX_E3V_EVCANFD: start 192, 2 bit, little-endian, data-type-policy=OVERRIDE, i-signal-type=PRIMITIVE, init-value=2, base-type=BT_MIK_PetPresence, compu {0=Cx0_no_pet_present (CM_MIK_PetPresence_Cx0_no_pet_present), 1=Cx1_pet_present (CM_MIK_PetPresence_Cx1_pet_present), 2=Cx2_init (CM_MIK_PetPresence_Cx2_init)}, range raw 0..2, transfer-property=PENDING  # pet presence signal
          signal MIK_CabinCare_state_XIX_MIK_01_XIX_E3V_EVCANFD: start 194, 3 bit, little-endian, data-type-policy=OVERRIDE, i-signal-type=PRIMITIVE, init-value=0, base-type=BT_MIK_CabinCare_state, compu {0=Cx0_Off (CM_MIK_CabinCare_state_Cx0_Off), 1=Cx1_Initialization (CM_MIK_CabinCare_state_Cx1_Initialization), 2=Cx2_Standby (CM_MIK_CabinCare_state_Cx2_Standby), 3=Cx3_Active (CM_MIK_CabinCare_state_Cx3_Active), 4=Cx4_error (CM_MIK_CabinCare_state_Cx4_error)}, range raw 0..4, transfer-property=PENDING  # current state of the cabin care function
          signal MIK_PetsMode_Active_XIX_MIK_01_XIX_E3V_EVCANFD: start 197, 1 bit, little-endian, data-type-policy=OVERRIDE, i-signal-type=PRIMITIVE, init-value=0, base-type=BT_MIK_PetsMode_Active, compu {0=Cx0_Function_disabled (CM_MIK_PetsMode_Active_Cx0_Function_disabled), 1=Cx1_Function_enabled (CM_MIK_PetsMode_Active_Cx1_Function_enabled)}, range raw 0..1, transfer-property=PENDING  # MIK ECU to HMI to transmit the de-/activation by the customer.
          signal MIK_ChildPresence_XIX_MIK_01_XIX_E3V_EVCANFD: start 198, 2 bit, little-endian, data-type-policy=OVERRIDE, i-signal-type=PRIMITIVE, init-value=2, base-type=BT_MIK_ChildPresence, compu {0=Cx0_no_child_present (CM_MIK_ChildPresence_Cx0_no_child_present), 1=Cx1_child_present (CM_MIK_ChildPresence_Cx1_child_present), 2=Cx2_init (CM_MIK_ChildPresence_Cx2_init)}, range raw 0..2, transfer-property=PENDING  # child presence signal
          signal MIK_CabinCare_Active_XIX_MIK_01_XIX_E3V_EVCANFD: start 200, 1 bit, little-endian, data-type-policy=OVERRIDE, i-signal-type=PRIMITIVE, base-type=BT_MIK_CabinCare_Active, compu {0=Cx0_Function_disabled (CM_MIK_CabinCare_Active_Cx0_Function_disabled), 1=Cx1_Function_enabled (CM_MIK_CabinCare_Active_Cx1_Function_enabled)}, range raw 0..1, transfer-property=PENDING  # MIK ECU to HMI to transmit the de-/activation by the customer.
          signal MIK_ZR_ActivationState_XIX_MIK_01_XIX_E3V_EVCANFD: start 201, 2 bit, little-endian, data-type-policy=OVERRIDE, i-signal-type=PRIMITIVE, init-value=3, base-type=BT_MIK_ZR_ActivationState, compu {0=Cx0_deactivated (CM_MIK_ZR_ActivationState_Cx0_deactivated), 1=Cx1_activated (CM_MIK_ZR_ActivationState_Cx1_activated), 2=Cx2_can_not_be_modified (CM_MIK_ZR_ActivationState_Cx2_can_not_be_modified), 3=Cx3_waiting_for_ZR_Status (CM_MIK_ZR_ActivationState_Cx3_waiting_for_ZR_Status)}, range raw 0..3, transfer-property=PENDING  # Das Signal sendet den Aktivierungsstatus der MIK nach Aufforderung vom ZR
          signal MIK_LeftEyeClosed_XIX_MIK_01_XIX_E3V_EVCANFD: start 203, 2 bit, little-endian, data-type-policy=OVERRIDE, i-signal-type=PRIMITIVE, base-type=BT_MIK_LeftEyeClosed, compu {0=Cx0_eye_not_closed (CM_MIK_LeftEyeClosed_Cx0_eye_not_closed), 1=Cx1_eye_closed (CM_MIK_LeftEyeClosed_Cx1_eye_closed), 2=Cx2_unknown_eye_state (CM_MIK_LeftEyeClosed_Cx2_unknown_eye_state), 3=Cx3_no_eye_detected (CM_MIK_LeftEyeClosed_Cx3_no_eye_detected)}, range raw 0..3, transfer-property=PENDING  # Auge links geschlossen oder geöffnet
          signal MIK_LeftEyeDetected_XIX_MIK_01_XIX_E3V_EVCANFD: start 205, 1 bit, little-endian, data-type-policy=OVERRIDE, i-signal-type=PRIMITIVE, base-type=BT_MIK_LeftEyeDetected, compu {0=Cx0_eye_not_detected (CM_MIK_LeftEyeDetected_Cx0_eye_not_detected), 1=Cx1_eye_detected (CM_MIK_LeftEyeDetected_Cx1_eye_detected)}, range raw 0..1, transfer-property=PENDING  # Auge links erkannt oder nicht
          signal MIK_LeftEyeDetectionQual_XIX_MIK_01_XIX_E3V_EVCANFD: start 206, 7 bit, little-endian, data-type-policy=OVERRIDE, i-signal-type=PRIMITIVE, base-type=BT_MIK_LeftEyeDetectionQual, compu {phys=raw for raw 0..100; unit Unit_PerCent}, range phys 0..100 Unit_PerCent, raw 0..100, unit=Unit_PerCent, transfer-property=PENDING  # Qualitätssignal für die Erkennung des linken Auges
          signal MIK_RightEyeClosed_XIX_MIK_01_XIX_E3V_EVCANFD: start 213, 2 bit, little-endian, data-type-policy=OVERRIDE, i-signal-type=PRIMITIVE, base-type=BT_MIK_RightEyeClosed, compu {0=Cx0_eye_not_closed (CM_MIK_RightEyeClosed_Cx0_eye_not_closed), 1=Cx1_eye_closed (CM_MIK_RightEyeClosed_Cx1_eye_closed), 2=Cx2_unknown_eye_state (CM_MIK_RightEyeClosed_Cx2_unknown_eye_state), 3=Cx3_no_eye_detected (CM_MIK_RightEyeClosed_Cx3_no_eye_detected)}, range raw 0..3, transfer-property=PENDING  # Auge rechts geschlossen oder geöffnet
          signal MIK_RightEyeDetected_XIX_MIK_01_XIX_E3V_EVCANFD: start 215, 1 bit, little-endian, data-type-policy=OVERRIDE, i-signal-type=PRIMITIVE, base-type=BT_MIK_RightEyeDetected, compu {0=Cx0_eye_not_detected (CM_MIK_RightEyeDetected_Cx0_eye_not_detected), 1=Cx1_eye_detected (CM_MIK_RightEyeDetected_Cx1_eye_detected)}, range raw 0..1, transfer-property=PENDING  # Auge rechts erkannt oder nicht
          signal MIK_RightEyeDetectionQual_XIX_MIK_01_XIX_E3V_EVCANFD: start 216, 7 bit, little-endian, data-type-policy=OVERRIDE, i-signal-type=PRIMITIVE, base-type=BT_MIK_RightEyeDetectionQual, compu {phys=raw for raw 0..100; unit Unit_PerCent}, range phys 0..100 Unit_PerCent, raw 0..100, unit=Unit_PerCent, transfer-property=PENDING  # Qualitätssignal für die Erkennung des rechten Auges
      frame Motor_14_XIX_E3V_EVCANFD: id 0x3BE, to Klima, frame-length=8, can-addressing-mode=STANDARD, can-frame-rx-behavior=CAN-FD, can-frame-tx-behavior=CAN-FD
        pdu Motor_14_XIX_E3V_EVCANFD: length=8, minimum-delay=0.01, transmission-mode-true-timing={cyclic-timing={time-offset=0.0, time-period=0.1}, event-controlled-timing={number-of-repetitions=0, repetition-period=0.0}}, unused-bit-pattern=0
          signal Motor_14_CRC_XIX_Motor_14_XIX_E3V_EVCANFD: start 0, 8 bit, little-endian, data-type-policy=OVERRIDE, i-signal-type=PRIMITIVE, base-type=BT_Motor_14_CRC, compu {phys=raw for raw 0..255}, range phys 0..255, raw 0..255, transfer-property=PENDING  # Ab MQB und MLBevo: "Berechnung siehe Lastenheft "End-to-End Kommunikationsabsicherung" Endwerte siehe Begleitdokument "S-PDU Kennungsfolgen"
          signal Motor_14_BZ_XIX_Motor_14_XIX_E3V_EVCANFD: start 8, 4 bit, little-endian, data-type-policy=OVERRIDE, i-signal-type=PRIMITIVE, base-type=BT_Motor_14_BZ, compu {phys=raw for raw 0..15}, range phys 0..15, raw 0..15, transfer-property=PENDING
          signal MO_StartStopp_Status_XIX_Motor_14_XIX_E3V_EVCANFD: start 12, 2 bit, little-endian, data-type-policy=OVERRIDE, i-signal-type=PRIMITIVE, init-value=0, base-type=BT_MO_StartStopp_Status, compu {0=Cx0_System_in_diesem_KL15_Zyklus_nicht_verfuegbar (CM_MO_StartStopp_Status_Cx0_System_in_diesem_KL15_Zyklus_nicht_verfuegbar), 1=Cx1_System_aktiv_keine_Freigabe_durch_StartStop_Koordinator (CM_MO_StartStopp_Status_Cx1_System_aktiv_keine_Freigabe_durch_StartStop_Koordinator), 2=Cx2_System_aktiv_alle_Freigaben_liegen_vor (CM_MO_StartStopp_Status_Cx2_System_aktiv_alle_Freigaben_liegen_vor), 3=Cx3_System_aktiv_mindestens_eine_Freigabe_fehlt (CM_MO_StartStopp_Status_Cx3_System_aktiv_mindestens_eine_Freigabe_fehlt)}, range raw 0..3, transfer-property=PENDING  # Aktivitätsstatus Start/Stopp-Koordinator HYBRID: Wenn MO_Hybridfahrzeug = 1 gilt: Signal bezieht sich nur auf den Verbrennungsmotor, nicht auf den Hybridantrieb
          signal MO_StartStopp_Wiederstart_XIX_Motor_14_XIX_E3V_EVCANFD: start 14, 1 bit, little-endian, data-type-policy=OVERRIDE, i-signal-type=PRIMITIVE, init-value=0, base-type=BT_MO_StartStopp_Wiederstart, compu {0=Cx0_Wiederstart_inaktiv (CM_MO_StartStopp_Wiederstart_Cx0_Wiederstart_inaktiv), 1=Cx1_Wiederstart_aktiv (CM_MO_StartStopp_Wiederstart_Cx1_Wiederstart_aktiv)}, range raw 0..1, transfer-property=TRIGGERED-ON-CHANGE-WITHOUT-REPETITION  # Motorwiederstart durch Start/Stopp-Koordinator HYBRID: Wenn MO_Hybridfahrzeug =1 gilt: Warnung vor Spannungseinbruch beim Zustart des Verbrennungsmotors. -nicht relevant, da derzeit kein Start über 12V-Starter geplant- Dieses Signal wird nur vom Hybrid-Koordintor gesetzt, wenn durch den Wiederstart ein Spannungseinbruch zu erwarten ist
          signal MO_StartStopp_Motorstopp_XIX_Motor_14_XIX_E3V_EVCANFD: start 15, 1 bit, little-endian, data-type-policy=OVERRIDE, i-signal-type=PRIMITIVE, init-value=0, base-type=BT_MO_StartStopp_Motorstopp, compu {0=Cx0_Motor_Stop_inaktiv (CM_MO_StartStopp_Motorstopp_Cx0_Motor_Stop_inaktiv), 1=Cx1_Motor_Stop_aktiv (CM_MO_StartStopp_Motorstopp_Cx1_Motor_Stop_aktiv)}, range raw 0..1, transfer-property=TRIGGERED-ON-CHANGE-WITHOUT-REPETITION  # Motor-Stopp durch Start/Stopp-Koordinator HYBRID: Wenn MO_Hybridfahrzeug = 1 gilt: Verbrennungsmotor durch Hybrid-Koordinator im MSG ausgeschaltet. Die definierten Start/Stopp-Signale beziehen sich nur auf den Verbrennungsmotor!
          signal MO_Freig_Reku_XIX_Motor_14_XIX_E3V_EVCANFD: start 16, 2 bit, little-endian, data-type-policy=OVERRIDE, i-signal-type=PRIMITIVE, init-value=0, base-type=BT_MO_Freig_Reku, compu {0=Cx0_Rekuperations_Modus_aus (CM_MO_Freig_Reku_Cx0_Rekuperations_Modus_aus) (Rekuperations-Modus aus), 1=Cx1_Empfehlung_Spannungsanhebung (CM_MO_Freig_Reku_Cx1_Empfehlung_Spannungsanhebung) (Empfehlung Spannungsanhebung), 2=Cx2_Empfehlung_Spannungsabsenkung (CM_MO_Freig_Reku_Cx2_Empfehlung_Spannungsabsenkung) (Empfehlung Spannungsabsenkung), 3=Cx3_Rekuperationsmodus_aktiv_Spannungsvariation_nicht_notwendig (CM_MO_Freig_Reku_Cx3_Rekuperationsmodus_aktiv_Spannungsvariation_nicht_notwendig) (Rekuperationsmodus aktiv, Spannungsvariation nicht notwendig)}, range raw 0..3, transfer-property=PENDING  # Empfehlung des Motor-SG's zur Spannungsabsenkung/-anhebung für den Rekuperationsbetrieb
          signal MO_Kl_75_XIX_Motor_14_XIX_E3V_EVCANFD: start 18, 1 bit, little-endian, data-type-policy=OVERRIDE, i-signal-type=PRIMITIVE, init-value=0, base-type=BT_MO_Kl_75, compu {0=Cx0_Aus (CM_MO_Kl_75_Cx0_Aus), 1=Cx1_Ein (CM_MO_Kl_75_Cx1_Ein)}, range raw 0..1, transfer-property=TRIGGERED-ON-CHANGE-WITHOUT-REPETITION  # Klemme X
          signal MO_Kl_50_XIX_Motor_14_XIX_E3V_EVCANFD: start 19, 1 bit, little-endian, data-type-policy=OVERRIDE, i-signal-type=PRIMITIVE, init-value=0, base-type=BT_MO_Kl_50, compu {0=Cx0_aus (CM_MO_Kl_50_Cx0_aus), 1=Cx1_KL50_ein_Startausfuehrung_Fahrer (CM_MO_Kl_50_Cx1_KL50_ein_Startausfuehrung_Fahrer)}, range raw 0..1, transfer-property=TRIGGERED-ON-CHANGE-WITHOUT-REPETITION  # Klemme 50: Startausführung durch Ritzelstarter MLB: nicht von allen Motoren gesendet MQB/MLBevo: gesendet von allen Motoren
          signal MO_Gangposition_XIX_Motor_14_XIX_E3V_EVCANFD: start 20, 4 bit, little-endian, data-type-policy=OVERRIDE, i-signal-type=PRIMITIVE, init-value=14, base-type=BT_MO_Gangposition, invalid-value=Invalid_MO_Gangposition_XIX_Motor_14_XIX_E3V_EVCANFD:15, compu {0=Cx0_Gang_N (CM_MO_Gangposition_Cx0_Gang_N), 1=Cx1_Gang_1 (CM_MO_Gangposition_Cx1_Gang_1), 2=Cx2_Gang_2 (CM_MO_Gangposition_Cx2_Gang_2), 3=Cx3_Gang_3 (CM_MO_Gangposition_Cx3_Gang_3), 4=Cx4_Gang_4 (CM_MO_Gangposition_Cx4_Gang_4), 5=Cx5_Gang_5 (CM_MO_Gangposition_Cx5_Gang_5), 6=Cx6_Gang_6 (CM_MO_Gangposition_Cx6_Gang_6), 7=Cx7_Gang_7 (CM_MO_Gangposition_Cx7_Gang_7), 8=Cx8_Gang_8 (CM_MO_Gangposition_Cx8_Gang_8), 9=Cx9_Automat_P (CM_MO_Gangposition_Cx9_Automat_P), 10=Cxa_Automat_Vorwaerts_S (CM_MO_Gangposition_Cxa_Automat_Vorwaerts_S), 11=Cxb_Automat_Vorwaerts_D_E (CM_MO_Gangposition_Cxb_Automat_Vorwaerts_D_E) (Automat_Vorwaerts_D/E), 12=Cxc_Zwischenstellung (CM_MO_Gangposition_Cxc_Zwischenstellung), 13=Cxd_Gang_R (CM_MO_Gangposition_Cxd_Gang_R), 14=Cxe_Istgang_nicht_definiert (CM_MO_Gangposition_Cxe_Istgang_nicht_definiert), 15=Cxf_Fehler (CM_MO_Gangposition_Cxf_Fehler)}, range raw 0..15, transfer-property=TRIGGERED-ON-CHANGE-WITHOUT-REPETITION  # MLB: Stellung des Wählhebels in der Schaltgasse des Handschaltgetriebes. MLBevo: Ausweitung der Bedienung auch auf Automatikgetriebe; Routing des Signals GE_Fahrstufe: 1. Position_R (dez. 6) auf MO_Gangposition: Gang_R (dez. 13) wegen Entfall Signals BCM1_Rueckfahrlicht_Schalter; 2. Position_N (4) auf GangN (0) 3. Zwischenstellung (0) auf Zwischenstellung (12) 4. Init (1) auf Init (14) 5. Fehler (15) auf Fehler (15) oder Timeout der relevanten Getriebe-PDU 6. Position_S und Tipp_in_S auf Automat_Vorwärts_S (10) 7. Position_D, Effizienz und Tipp_in_D auf Automat_Vorwärts_D/E (11) 8. Position_P (5) auf Automat_P (9) Handschaltgetriebe wie MLB MQB: Abhängig vom Signal MO_Signalquelle_Gangposition: Stellung des Wählhebels in der Schaltgasse des Handschaltgetriebes aus Gangpositionssensor oder Modellwert aus Motordrehzahl und Fahrzeuggeschwindigkeit (ggf. unter Hinzuziehung des Neutralgangsensors und Rückfahrlichtschalters); bei betätigter Kupplung (MO_Kuppl_schalter=1) ist das der Modellwert nicht verwendbar. Der Modellwert ist für Plausibilisierungen nicht geeignet. Bei verbautem Automatikgetriebe wird der Initwert (14=Istgang nicht definiert) ausgegeben.
          signal MO_StartStopp_Fahrerwunsch_XIX_Motor_14_XIX_E3V_EVCANFD: start 24, 2 bit, little-endian, data-type-policy=OVERRIDE, i-signal-type=PRIMITIVE, init-value=0, base-type=BT_MO_StartStopp_Fahrerwunsch, compu {0=Cx0_Init (CM_MO_StartStopp_Fahrerwunsch_Cx0_Init), 1=Cx1_Stoppverbot_durch_Fahrer (CM_MO_StartStopp_Fahrerwunsch_Cx1_Stoppverbot_durch_Fahrer), 2=Cx2_Stoppfreigabe_durch_Fahrer (CM_MO_StartStopp_Fahrerwunsch_Cx2_Stoppfreigabe_durch_Fahrer), 3=Cx3_Stoppanforderung_durch_Fahrer (CM_MO_StartStopp_Fahrerwunsch_Cx3_Stoppanforderung_durch_Fahrer)}, range raw 0..3, transfer-property=PENDING  # Fahreraktivität Start/Stop
          signal MO_HYB_Fahrbereitschaft_XIX_Motor_14_XIX_E3V_EVCANFD: start 26, 1 bit, little-endian, data-type-policy=OVERRIDE, i-signal-type=PRIMITIVE, init-value=0, base-type=BT_MO_HYB_Fahrbereitschaft, compu {0=Cx0_keine_Fahrbereitschaft (CM_MO_HYB_Fahrbereitschaft_Cx0_keine_Fahrbereitschaft), 1=Cx1_Fahrbereitschaft (CM_MO_HYB_Fahrbereitschaft_Cx1_Fahrbereitschaft)}, range raw 0..1, transfer-property=PENDING, to Klima(timeout 1 s)  # Signal steuert u.a. in der Lenkhilfe zusammen mit weiteren Informationen den Modewechsel in den "Drivemode" Grüne Anzeige im Kombiinstrument zur Signalisierung der Bereitschaft des Hybridsystems.
          signal MO_Ext_E_Fahrt_aktiv_XIX_Motor_14_XIX_E3V_EVCANFD: start 27, 1 bit, little-endian, data-type-policy=OVERRIDE, i-signal-type=PRIMITIVE, init-value=0, base-type=BT_MO_Ext_E_Fahrt_aktiv, compu {0=Cx0_Rueckmeldung_E_Taster_aus (CM_MO_Ext_E_Fahrt_aktiv_Cx0_Rueckmeldung_E_Taster_aus), 1=Cx1_Rueckmeldung_E_Taster_ein (CM_MO_Ext_E_Fahrt_aktiv_Cx1_Rueckmeldung_E_Taster_ein)}, range raw 0..1, transfer-property=TRIGGERED-ON-CHANGE-WITHOUT-REPETITION  # Funktionsrückmeldung zum erw. E-Fahr-Betrieb über Lampe/LED im E-Mode-Taster
          signal MO_Fahrer_bremst_XIX_Motor_14_XIX_E3V_EVCANFD: start 28, 1 bit, little-endian, data-type-policy=OVERRIDE, i-signal-type=PRIMITIVE, init-value=0, base-type=BT_MO_Fahrer_bremst, compu {0=Cx0_kein_Bremsen (CM_MO_Fahrer_bremst_Cx0_kein_Bremsen), 1=Cx1_Bremse_betaetigt (CM_MO_Fahrer_bremst_Cx1_Bremse_betaetigt)}, range raw 0..1, transfer-property=TRIGGERED-ON-CHANGE-WITHOUT-REPETITION  # Redundante Bremsinformation vom Motor. MLB: AUDI D4: Zykluszeit: 10ms (siehe Zykluszeit schnell/Cycletime Fast) Im AUDI B8 wird in diesem Bit der Wert der ESP-CAN-Information "ESP_Fahrer_bremst" ausgegeben. Achtung: Reduktion der Zykluszeit Motor_03 auf 10ms geplant. Projektabhängig soll künftig mit 10ms gesendet werden. Empfänger die in weiteren Konzern-Projekten eingesetzt werden müssen dazu beide Zykluszeiten (10/20ms) unterstützen. Empfänger muss in diesem Fall für die Timeoutdiagnose und CAN-Messwerteblöcke mit 20ms auslegen.
          signal MO_QBit_Fahrer_bremst_XIX_Motor_14_XIX_E3V_EVCANFD: start 29, 1 bit, little-endian, data-type-policy=OVERRIDE, i-signal-type=PRIMITIVE, init-value=1, base-type=BT_MO_QBit_Fahrer_bremst, compu {0=Cx0_gueltiger_Wert (CM_MO_QBit_Fahrer_bremst_Cx0_gueltiger_Wert), 1=Cx1_Ersatz_Init_oder_Fehlerwert (CM_MO_QBit_Fahrer_bremst_Cx1_Ersatz_Init_oder_Fehlerwert)}, range raw 0..1, transfer-property=TRIGGERED-ON-CHANGE-WITHOUT-REPETITION  # MLB: AUDI D4: Zykluszeit: 10ms (siehe Zykluszeit schnell/Cycletime Fast) Achtung: Reduktion der Zykluszeit Motor_03 auf 10ms geplant. Projektabhängig soll künftig mit 10ms gesendet werden. Empfänger die in weiteren Konzern-Projekten eingesetzt werden müssen dazu beide Zykluszeiten (10/20ms) unterstützen. Empfänger muss in diesem Fall für die Timeoutdiagnose und CAN-Messwerteblöcke mit 20ms auslegen.
          signal MO_BLS_XIX_Motor_14_XIX_E3V_EVCANFD: start 30, 1 bit, little-endian, data-type-policy=OVERRIDE, i-signal-type=PRIMITIVE, init-value=0, base-type=BT_MO_BLS, compu {0=Cx0_kein_Bremsen (CM_MO_BLS_Cx0_kein_Bremsen), 1=Cx1_Bremse_betaetigt (CM_MO_BLS_Cx1_Bremse_betaetigt)}, range raw 0..1, transfer-property=TRIGGERED-ON-CHANGE-WITHOUT-REPETITION  # Ungefiltertes Rohsignal des Bremslichtschalters, nur wenn HW-Eingang bestückt und ausgewertet wird. Bei Motoren ohne genutzten HW-Eingang wird kein Ersatzwert (bspw. SW-Signal über CAN) ausgegeben! Bei AUDI muss das Signal wg. Bremslichtfunktion immer bedient werden. MLB: AUDI D4: Zykluszeit: 10ms (siehe Zykluszeit schnell/Cycletime Fast) Achtung: Reduktion der Zykluszeit Motor_03 auf 10ms geplant. Projektabhängig soll künftig mit 10ms gesendet werden. Empfänger die in weiteren Konzern-Projekten eingesetzt werden müssen dazu beide Zykluszeiten (10/20ms) unterstützen. Empfänger muss in diesem Fall für die Timeoutdiagnose und CAN-Messwerteblöcke mit 20ms auslegen.
          signal MO_Konsistenz_Bremsped_XIX_Motor_14_XIX_E3V_EVCANFD: start 31, 1 bit, little-endian, data-type-policy=OVERRIDE, i-signal-type=PRIMITIVE, init-value=0, base-type=BT_MO_Konsistenz_Bremsped, compu {0=Cx0_Bremspedalinformation_plausibel (CM_MO_Konsistenz_Bremsped_Cx0_Bremspedalinformation_plausibel), 1=Cx1_Bremspedalinformation_unplausibel (CM_MO_Konsistenz_Bremsped_Cx1_Bremspedalinformation_unplausibel)}, range raw 0..1, transfer-property=TRIGGERED-ON-CHANGE-WITHOUT-REPETITION  # MLB: AUDI D4: Zykluszeit: 10ms (siehe Zykluszeit schnell/Cycletime Fast) Siehe "Funktionsspezifikation Bremslichtinfo B8" Achtung: Reduktion der Zykluszeit Motor_03 auf 10ms geplant. Projektabhängig soll künftig mit 10ms gesendet werden. Empfänger die in weiteren Konzern-Projekten eingesetzt werden müssen dazu beide Zykluszeiten (10/20ms) unterstützen. Empfänger muss in diesem Fall für die Timeoutdiagnose und CAN-Messwerteblöcke mit 20ms auslegen.
          signal MO_Timeout_ESP_XIX_Motor_14_XIX_E3V_EVCANFD: start 32, 1 bit, little-endian, data-type-policy=OVERRIDE, i-signal-type=PRIMITIVE, init-value=0, base-type=BT_MO_Timeout_ESP, compu {0=Cx0_Empfang_iO (CM_MO_Timeout_ESP_Cx0_Empfang_iO), 1=Cx1_Timeout (CM_MO_Timeout_ESP_Cx1_Timeout)}, range raw 0..1, transfer-property=TRIGGERED-ON-CHANGE-WITHOUT-REPETITION  # 500 ms Timeout auf Bremsen-Botschaft ist >= 1 mal aufgelaufen, Löschen des Bits nach Neustart (KL15). MLB: AUDI D4: Zykluszeit: 10ms (siehe Zykluszeit schnell/Cycletime Fast) Achtung: Reduktion der Zykluszeit Motor_03 auf 10ms geplant. Projektabhängig soll künftig mit 10ms gesendet werden. Empfänger die in weiteren Konzern-Projekten eingesetzt werden müssen dazu beide Zykluszeiten (10/20ms) unterstützen. Empfänger muss in diesem Fall für die Timeoutdiagnose und CAN-Messwerteblöcke mit 20ms auslegen.
          signal MO_Klima_Eingr_XIX_Motor_14_XIX_E3V_EVCANFD: start 33, 2 bit, little-endian, data-type-policy=OVERRIDE, i-signal-type=PRIMITIVE, init-value=0, base-type=BT_MO_Klima_Eingr, compu {0=Cx0_kein_Eingriff (CM_MO_Klima_Eingr_Cx0_kein_Eingriff) (kein Eingriff), 1=Cx1_Klimakompressor_ausschalten (CM_MO_Klima_Eingr_Cx1_Klimakompressor_ausschalten) (Klimakompressor ausschalten), 2=Cx2_Klimakompressor_Leistungsreduzierung (CM_MO_Klima_Eingr_Cx2_Klimakompressor_Leistungsreduzierung) (Klimakompressor Leistungsreduzierung), 3=Cx3_Klimakompressor_aufgrund_der_Heissleuchtenvorwarnung_ausschalten (CM_MO_Klima_Eingr_Cx3_Klimakompressor_aufgrund_der_Heissleuchtenvorwarnung_ausschalten) (Klimakompressor aufgrund der Heissleuchtenvorwarnung ausschalten)}, range raw 0..3, transfer-property=TRIGGERED-ON-CHANGE-WITHOUT-REPETITION  # Eingriffe des Motor bei der Klima
          signal MO_Aussp_Anlass_XIX_Motor_14_XIX_E3V_EVCANFD: start 35, 1 bit, little-endian, data-type-policy=OVERRIDE, i-signal-type=PRIMITIVE, init-value=0, base-type=BT_MO_Aussp_Anlass, compu {0=Cx0_Anlasser_darf_angesteuert_werden (CM_MO_Aussp_Anlass_Cx0_Anlasser_darf_angesteuert_werden), 1=Cx1_Anlasser_ausspuren_Ansteuerung_nicht_moeglich (CM_MO_Aussp_Anlass_Cx1_Anlasser_ausspuren_Ansteuerung_nicht_moeglich) (Anlasser_ausspuren__Ansteuerung_nicht_moeglich)}, range raw 0..1, transfer-property=TRIGGERED-ON-CHANGE-WITHOUT-REPETITION  # Das Signal zeigt an, ob die Wiederholstartsperre aktiv ist. D. h. eine Ansteuerung des Anlassers wird auch bei erfüllten Startvoraussetzungen (HS: Interlock betätigt bzw. AT: P/N eingelegt und Bremse betätigt) nicht erfolgen.
          signal MO_Freig_Anlass_XIX_Motor_14_XIX_E3V_EVCANFD: start 36, 1 bit, little-endian, data-type-policy=OVERRIDE, i-signal-type=PRIMITIVE, init-value=0, base-type=BT_MO_Freig_Anlass, compu {0=Cx0_Start_nicht_zulaessig (CM_MO_Freig_Anlass_Cx0_Start_nicht_zulaessig), 1=Cx1_Startfreigabe (CM_MO_Freig_Anlass_Cx1_Startfreigabe)}, range raw 0..1, transfer-property=TRIGGERED-ON-CHANGE-WITHOUT-REPETITION  # Bit wird gesetzt, wenn der Motor beim Automatikstart gestartet werden darf (Motorstillstand, Emissionsmaßnahmen sind erfüllt).
          signal MO_Kuppl_schalter_XIX_Motor_14_XIX_E3V_EVCANFD: start 37, 1 bit, little-endian, data-type-policy=OVERRIDE, i-signal-type=PRIMITIVE, init-value=0, base-type=BT_MO_Kuppl_schalter, compu {0=Cx0_Schalter_sagt_ausgekuppelt (CM_MO_Kuppl_schalter_Cx0_Schalter_sagt_ausgekuppelt), 1=Cx1_Schalter_sagt_eingekuppelt (CM_MO_Kuppl_schalter_Cx1_Schalter_sagt_eingekuppelt)}, range raw 0..1, transfer-property=TRIGGERED-ON-CHANGE-WITHOUT-REPETITION  # MLB: Das Motorsteuergerät gibt die Information aus, ab wann der Kupplungsschalter durch das Motorsteuergerät als getreten gesehen wird 0x0: Schalter sagt betätigt (Ausgekuppelt) 0x1: Schalter sagt nicht betätigt (Eingekuppelt) MQB: Nur Handschalter; aktiv, wenn Schalter verbaut; sonst konstant auf "0" gesetzt; Bit wird gesetzt, wenn Kupplungspedal nicht betätigt wird (Kupplungsschalter hoch), Triebstrang kann noch eingekuppelt sein.
          signal MO_Interlock_XIX_Motor_14_XIX_E3V_EVCANFD: start 38, 1 bit, little-endian, data-type-policy=OVERRIDE, i-signal-type=PRIMITIVE, init-value=0, base-type=BT_MO_Interlock, compu {0=Cx0_Interlockschalter_nicht_betaetigt (CM_MO_Interlock_Cx0_Interlockschalter_nicht_betaetigt), 1=Cx1_Interlockschalter_betaetigt (CM_MO_Interlock_Cx1_Interlockschalter_betaetigt)}, range raw 0..1, transfer-property=TRIGGERED-ON-CHANGE-WITHOUT-REPETITION  # Das Motorsteuergerät gibt die Information aus, ab wann der Kupplungsschalter durch das Motorsteuergerät als getreten gesehen wird. Bei Systemen für Start Stopp muss das Interlocksignal für einen Start durch das MSG generiert werden, sobald der Schalthebel in Neutralposition (kein Kraftschluß) und ein Wiederstart vom StartStopp-Koordinator angefordert wird.
          signal MO_Motor_laeuft_XIX_Motor_14_XIX_E3V_EVCANFD: start 39, 1 bit, little-endian, data-type-policy=OVERRIDE, i-signal-type=PRIMITIVE, init-value=0, base-type=BT_MO_Motor_laeuft, compu {0=Cx0_Motor_laeuft_nicht (CM_MO_Motor_laeuft_Cx0_Motor_laeuft_nicht), 1=Cx1_Motor_laeuft_autark_und_stabil_und_darf_mechanisch_belastet_werden (CM_MO_Motor_laeuft_Cx1_Motor_laeuft_autark_und_stabil_und_darf_mechanisch_belastet_werden)}, range raw 0..1, transfer-property=TRIGGERED-ON-CHANGE-WITHOUT-REPETITION  # Das Motorsteuergerät gibt die Information aus, ab wann der Motor verbrennungsbedingt autark läuft und durch zuschaltbare Nebenaggregate mechanisch belastbar ist (z.B. durch Generator, Klimakompressor, etc.). Die "Motor läuft" Information wird ausgegeben, wenn für eine (projektspezifisch) applizierbare Zeit (~500 - 600ms) die (projektspezifische) Motor-Startende-Drehzahl überschritten wird. Diese Drehzahlschwelle ist von der Kühlwassertemperatur und dem Umgebungsdruck (Diesel Motor) abhängig. Das Bit wird auch gesetzt, nach MSG-Reset und wenn der Motor angeschleppt wird (wenn während der Fahrt Kl. 15 aus --> ein erfolgt) HYBRID: Wenn MO_Hybridfahrzeug = 1 gilt: Hybridantrieb läuft und ist belastbar, es kann ein Moment abgegeben werden (erzeugt durch ELM oder / und VKM). Rücknahme des Signals im Fehlerfall, wenn das Hybridsystem die Versorgung des Bordnetzes deutlich begrenzen bzw. abschalten muss. Achtung: Das Signal kann nicht mehr dazu dienen, ob Komponenten am Riementrieb des Verbrennungsmotors den Verbrennungsmotor belasten können.
          signal MO_Kickdown_XIX_Motor_14_XIX_E3V_EVCANFD: start 40, 1 bit, little-endian, data-type-policy=OVERRIDE, i-signal-type=PRIMITIVE, init-value=0, base-type=BT_MO_Kickdown, compu {0=Cx0_kein_Kickdown (CM_MO_Kickdown_Cx0_kein_Kickdown), 1=Cx1_Kickdown (CM_MO_Kickdown_Cx1_Kickdown)}, range raw 0..1, transfer-property=TRIGGERED-ON-CHANGE-WITHOUT-REPETITION  # Es gilt: Signalspec MO_Kickdown v1.0
          signal MO_QBit_KL_75_XIX_Motor_14_XIX_E3V_EVCANFD: start 41, 1 bit, little-endian, data-type-policy=OVERRIDE, i-signal-type=PRIMITIVE, init-value=1, base-type=BT_MO_QBit_KL_75, compu {0=Cx0_gueltiger_Wert (CM_MO_QBit_KL_75_Cx0_gueltiger_Wert), 1=Cx1_Ersatz_Init_oder_Fehlerwert (CM_MO_QBit_KL_75_Cx1_Ersatz_Init_oder_Fehlerwert)}, range raw 0..1, transfer-property=TRIGGERED-ON-CHANGE-WITHOUT-REPETITION  # Q - Bit für das KL 75 Signal zur Vermeidung der fehlerhaften Erkennung von Motorstarts. Wird auf 1 gesetzt, solange das Motorsteuergerät KL15 = AUS erkannt hat.
          signal MO_EKlKomLeiRed_XIX_Motor_14_XIX_E3V_EVCANFD: start 42, 2 bit, little-endian, data-type-policy=OVERRIDE, i-signal-type=PRIMITIVE, init-value=0, base-type=BT_MO_EKlKomLeiRed, compu {0=Cx0_keine_Leistungsbegr (CM_MO_EKlKomLeiRed_Cx0_keine_Leistungsbegr), 1=Cx1_Leistungsbegr_75 (CM_MO_EKlKomLeiRed_Cx1_Leistungsbegr_75), 2=Cx2_Leistungsbegr_50 (CM_MO_EKlKomLeiRed_Cx2_Leistungsbegr_50), 3=Cx3_Leistungsbegr_25 (CM_MO_EKlKomLeiRed_Cx3_Leistungsbegr_25)}, range raw 0..3, transfer-property=PENDING  # Anforderung an die Klimasteuerung, die Leistungsaufnahme des E-Kompressors bei schlechtem SOC und in bestimmten Fahrsituationen zu begrenzen. (Das bereits bestehende Signal "Klimakompressor aus" als stets umzusetzende Anforderung bleibt unverändert bestehen.) 0 keine Leistungsbegr. gewünscht 1 Leistungsbegr. auf 75% der max. Leistung 2 Leistungsbegr. auf 50% der max. Leistung 3 Leistungsbegr. auf 25% der max. Leistung
          signal MO_Handshake_STH_XIX_Motor_14_XIX_E3V_EVCANFD: start 44, 1 bit, little-endian, data-type-policy=OVERRIDE, i-signal-type=PRIMITIVE, init-value=0, base-type=BT_MO_Handshake_STH, compu {0=Cx0_keine_EKP_Ansteuerung_durch_STH_Anforderung (CM_MO_Handshake_STH_Cx0_keine_EKP_Ansteuerung_durch_STH_Anforderung) (keine EKP-Ansteuerung durch STH-Anforderung), 1=Cx1_EKP_Ansteuerung_durch_STH_Anforderung (CM_MO_Handshake_STH_Cx1_EKP_Ansteuerung_durch_STH_Anforderung) (EKP-Ansteuerung durch STH-Anforderung)}, range raw 0..1, transfer-property=PENDING  # Es gilt: Signalspec MO_Handshake v1.0 Handshake zwischen MSG und STH. Wenn das MSG die EKP aufgrund einer STH-Anforderung ansteuert und kein Fehlereintrag bzgl. EKP/KPE/NDR vorliegt, wird das Bit gesetzt.
          signal MO_BKV_Unterdruckwarnung_XIX_Motor_14_XIX_E3V_EVCANFD: start 45, 1 bit, little-endian, data-type-policy=OVERRIDE, i-signal-type=PRIMITIVE, init-value=0, base-type=BT_MO_BKV_Unterdruckwarnung, compu {0=Cx0_Unterdruckhaushalt_iO (CM_MO_BKV_Unterdruckwarnung_Cx0_Unterdruckhaushalt_iO), 1=Cx1_Unterdruckhaushalt_niO (CM_MO_BKV_Unterdruckwarnung_Cx1_Unterdruckhaushalt_niO)}, range raw 0..1, transfer-property=PENDING  # Über die Unterdruckwarnung signalisiert das MSG dem ESP, dass kein ausreichender Unterdruck für den BKV zur Verfügung gestellt werden kann.
          signal MO_Freigabe_Segeln_XIX_Motor_14_XIX_E3V_EVCANFD: start 46, 1 bit, little-endian, data-type-policy=OVERRIDE, i-signal-type=PRIMITIVE, init-value=0, base-type=BT_MO_Freigabe_Segeln, compu {0=Cx0_Segelbetrieb_nicht_freigegeben (CM_MO_Freigabe_Segeln_Cx0_Segelbetrieb_nicht_freigegeben), 1=Cx1_Segelbetrieb_freigegeben (CM_MO_Freigabe_Segeln_Cx1_Segelbetrieb_freigegeben)}, range raw 0..1, transfer-property=PENDING  # Freigabebit des Segelbetriebs im Getriebe. Bedingt durch bestimmte Diagnosen und Adaptionen des MSGs, die nur im Schub möglich sind, darf nicht jede Schubphase für einen Segelbetrieb genutzt werden. Eine Freigabe bleibt auch außerhalb einer Schubphase bestehen. D.h. das Signal kennzeichnet nicht die Schubphase sondern sagt nur aus, dass aus Motorsicht nichts gegen einen Segelbetrieb in einer der nächsten Schubphasen spricht.
          signal MO_PTC_Status_XIX_Motor_14_XIX_E3V_EVCANFD: start 47, 3 bit, little-endian, data-type-policy=OVERRIDE, i-signal-type=PRIMITIVE, init-value=0, base-type=BT_MO_PTC_Status, compu {0=Cx0_nicht_unterstuetzt (CM_MO_PTC_Status_Cx0_nicht_unterstuetzt), 1=Cx1_Stufe_0 (CM_MO_PTC_Status_Cx1_Stufe_0), 2=Cx2_Stufe_1 (CM_MO_PTC_Status_Cx2_Stufe_1), 3=Cx3_Stufe_2 (CM_MO_PTC_Status_Cx3_Stufe_2), 4=Cx4_Stufe_3 (CM_MO_PTC_Status_Cx4_Stufe_3), 7=Cx7_PTC_am_BCM (CM_MO_PTC_Status_Cx7_PTC_am_BCM)}, range raw 0..7, transfer-property=PENDING  # Status-Rückmeldung vom MSG zum aktuellen PTC-Status (stufiges PTC, Relais am MSG). Bei Ansteuerung eines stufigen PTC durch ein anderes SG beschreibt das Signal die vom MSG freigegebene PTC-Stufe.
          signal MO_QBit_Gangposition_XIX_Motor_14_XIX_E3V_EVCANFD: start 50, 1 bit, little-endian, data-type-policy=OVERRIDE, i-signal-type=PRIMITIVE, init-value=1, base-type=BT_MO_QBit_Gangposition, compu {0=Cx0_gueltiger_Wert (CM_MO_QBit_Gangposition_Cx0_gueltiger_Wert), 1=Cx1_Ersatz_Init_oder_Fehlerwert (CM_MO_QBit_Gangposition_Cx1_Ersatz_Init_oder_Fehlerwert)}, range raw 0..1, transfer-property=TRIGGERED-ON-CHANGE-WITHOUT-REPETITION  # Qualitätsbit zum Signal MO_Gangposition
          signal MO_Signalquelle_Gangposition_XIX_Motor_14_XIX_E3V_EVCANFD: start 51, 1 bit, little-endian, data-type-policy=OVERRIDE, i-signal-type=PRIMITIVE, init-value=0, base-type=BT_MO_Signalquelle_Gangposition, compu {0=Cx0_Sensorsignal (CM_MO_Signalquelle_Gangposition_Cx0_Sensorsignal), 1=Cx1_Modellsignal (CM_MO_Signalquelle_Gangposition_Cx1_Modellsignal)}, range raw 0..1, transfer-property=PENDING  # Signalquelle des Signals MO_Gangposition 0: Signalquelle Gangpositionssensor 1: Signalquelle Modellwert (v/n)
          signal MO_Remotestart_Betrieb_XIX_Motor_14_XIX_E3V_EVCANFD: start 52, 1 bit, little-endian, data-type-policy=OVERRIDE, i-signal-type=PRIMITIVE, init-value=0, base-type=BT_MO_Remotestart_Betrieb, compu {0=Cx0_MSG_nicht_bereit_fuer_RS_Betrieb (CM_MO_Remotestart_Betrieb_Cx0_MSG_nicht_bereit_fuer_RS_Betrieb), 1=Cx1_MSG_bereit_fuer_oder_im_RS_Betrieb (CM_MO_Remotestart_Betrieb_Cx1_MSG_bereit_fuer_oder_im_RS_Betrieb)}, range raw 0..1, transfer-property=TRIGGERED-ON-CHANGE-WITHOUT-REPETITION  # Das MSG ist für den Remotestart-Betrieb bereit. Nach Empfang der Motorstartanforderung für RSt-Betrieb durch BCM wird der Fahrzeugmotor gestartet und solange der Motor läuft, bleibt dieses Bit aktiv. Dieses Signal ist nur zur Verwendung durch das BCM zur RemoteStart-Freigabe.
          signal MO_Remotestart_moeglich_XIX_Motor_14_XIX_E3V_EVCANFD: start 53, 1 bit, little-endian, data-type-policy=OVERRIDE, i-signal-type=PRIMITIVE, init-value=0, base-type=BT_MO_Remotestart_moeglich, compu {0=Cx0_Remotestart_nicht_moeglich (CM_MO_Remotestart_moeglich_Cx0_Remotestart_nicht_moeglich), 1=Cx1_Remotestart_moeglich (CM_MO_Remotestart_moeglich_Cx1_Remotestart_moeglich)}, range raw 0..1, transfer-property=PENDING  # Wenn Bit gesetzt, würde das MSG bei entsprechender Anforderung durch das BCM den Remotestartbetrieb einleiten, d.h. das MSG ist remotestartfähig und es liegen aktuell keine relevanten Fehler oder andere Abbruchgründe vor.
          signal MO_FMAus_aktiv_XIX_Motor_14_XIX_E3V_EVCANFD: start 55, 1 bit, little-endian, data-type-policy=OVERRIDE, i-signal-type=PRIMITIVE, init-value=0, base-type=BT_MO_FMAus_aktiv, compu {0=Cx0_inaktiv (CM_MO_FMAus_aktiv_Cx0_inaktiv), 1=Cx1_Segeln_mit_Motor_aus_aktiv (CM_MO_FMAus_aktiv_Cx1_Segeln_mit_Motor_aus_aktiv)}, range raw 0..1, transfer-property=TRIGGERED-ON-CHANGE-WITHOUT-REPETITION  # Das Signal gibt Rückmeldung ob Freilauf Motor aus aktiv ist. Beleibt auch 0km/h (unterhalb der StartStopp Schwelle) weiterhin aktiv.
          signal MO_FMAus_Startvariante_XIX_Motor_14_XIX_E3V_EVCANFD: start 56, 2 bit, little-endian, data-type-policy=OVERRIDE, i-signal-type=PRIMITIVE, init-value=0, base-type=BT_MO_FMAus_Startvariante, compu {0=Cx0_kein_Motorstart (CM_MO_FMAus_Startvariante_Cx0_kein_Motorstart), 1=Cx1_Motorstart_elektrischer_Starter (CM_MO_FMAus_Startvariante_Cx1_Motorstart_elektrischer_Starter), 2=Cx2_GetriebeAnschleppstart (CM_MO_FMAus_Startvariante_Cx2_GetriebeAnschleppstart), 3=Cx3_GetriebeNotAnschleppstart (CM_MO_FMAus_Startvariante_Cx3_GetriebeNotAnschleppstart)}, range raw 0..3, transfer-property=TRIGGERED-ON-CHANGE-WITHOUT-REPETITION  # Startvariante beim Motorstart aus der Freilauf-Motor-AUS Phase
          signal MO_BMS_NV_Anf_stuetzen_XIX_Motor_14_XIX_E3V_EVCANFD: start 58, 1 bit, little-endian, data-type-policy=OVERRIDE, i-signal-type=PRIMITIVE, init-value=0, base-type=BT_MO_BMS_NV_Anf_stuetzen, compu {0=Cx0_nicht_notwendig (CM_MO_BMS_NV_Anf_stuetzen_Cx0_nicht_notwendig), 1=Cx1_notwendig (CM_MO_BMS_NV_Anf_stuetzen_Cx1_notwendig)}, range raw 0..1, transfer-property=TRIGGERED-ON-CHANGE-WITHOUT-REPETITION  # Garantierte Unterstützung des Zusatzspeichers ist erforderlich. Zusatzspeicher muss an das Versorgungsnezt angebunden werden.
          signal MO_Zylinderabschaltung_XIX_Motor_14_XIX_E3V_EVCANFD: start 59, 2 bit, little-endian, data-type-policy=OVERRIDE, i-signal-type=PRIMITIVE, init-value=0, base-type=BT_MO_Zylinderabschaltung, compu {0=Cx0_Vollmotorbetrieb_VMB (CM_MO_Zylinderabschaltung_Cx0_Vollmotorbetrieb_VMB), 1=Cx1_Uebergang_HMB_in_VMB (CM_MO_Zylinderabschaltung_Cx1_Uebergang_HMB_in_VMB), 2=Cx2_Uebergang_VMB_in_HMB (CM_MO_Zylinderabschaltung_Cx2_Uebergang_VMB_in_HMB), 3=Cx3_Halbmotorbetrieb_HMB (CM_MO_Zylinderabschaltung_Cx3_Halbmotorbetrieb_HMB)}, range raw 0..3, transfer-property=TRIGGERED-ON-CHANGE-WITHOUT-REPETITION  # Status Zylinderabschaltung Motor
          signal MO_HYB_VM_aktiv_XIX_Motor_14_XIX_E3V_EVCANFD: start 61, 1 bit, little-endian, data-type-policy=OVERRIDE, i-signal-type=PRIMITIVE, init-value=0, base-type=BT_MO_HYB_VM_aktiv, compu {0=Cx0_VM_nicht_aktiv (CM_MO_HYB_VM_aktiv_Cx0_VM_nicht_aktiv), 1=Cx1_VM_aktiv (CM_MO_HYB_VM_aktiv_Cx1_VM_aktiv)}, range raw 0..1, transfer-property=TRIGGERED-ON-CHANGE-WITHOUT-REPETITION  # 0 = VMotor wird nicht aktiv gehalten (nVM < n_min und keine LL-Regelung aktiv) 1 = VMotor aktiv (ab der ersten Einspritzung; gilt auch für Schubbetrieb, wenn VMotor spätestens durch LLRegelung befeuert würde) Verwendet zur Bestimmung des Ist-Zustandes
          signal MO_StartVorauss_erfuellt_XIX_Motor_14_XIX_E3V_EVCANFD: start 62, 2 bit, little-endian, data-type-policy=OVERRIDE, i-signal-type=PRIMITIVE, init-value=1, base-type=BT_MO_StartVorauss_erfuellt, compu {0=Cx0_Signal_nicht_bedient (CM_MO_StartVorauss_erfuellt_Cx0_Signal_nicht_bedient), 1=Cx1_StartVorauss_nicht_ueberpruefbar (CM_MO_StartVorauss_erfuellt_Cx1_StartVorauss_nicht_ueberpruefbar), 2=Cx2_StartVorauss_nicht_erfuellt (CM_MO_StartVorauss_erfuellt_Cx2_StartVorauss_nicht_erfuellt), 3=Cx3_StartVorauss_erfuellt (CM_MO_StartVorauss_erfuellt_Cx3_StartVorauss_erfuellt)}, range raw 0..3, transfer-property=TRIGGERED-ON-CHANGE-WITHOUT-REPETITION  # Dient der Fallunterscheidung bei ZAT-Betätigung im Zustand "KL15 ein" (bei nicht gesetztem Signal folgt KL15 aus, bei gesetztem Signal folgt setzen KL50-Anf.) 0: Signal nicht bedient 1: Voraussetzungen zur Antriebsstrangaktivierung / Startvoraussetzungen nicht überprüfbar, Initwert Bildung: -MQB Handschalter: solange 'Kl15 aus' und für die ersten 50ms bei 'Kl15 ein' -MQB Automaten: solange 'Kl15 aus' und für die ersten 50-400ms bei 'Kl15 ein' -MLB Handschalter: solange 'Kl87 aus' und für die ersten 50ms bei 'Kl87 ein', wobei bei 'Kl15 ein' immer auch 'Kl87 ein' -MLB Automaten: solange 'Kl87 aus' oder Getriebe-SG nicht wach sowie für die ersten 50-400ms bei gleichzeitigem 'Kl87 ein' und 'Getriebe-SG wach' 2: Voraussetzungen zur Antriebsstrangaktivierung / Startvoraussetzungen nicht erfüllt 3: Voraussetzungen zur Antriebsstrangaktivierung / Startvoraussetzungen erfüllt
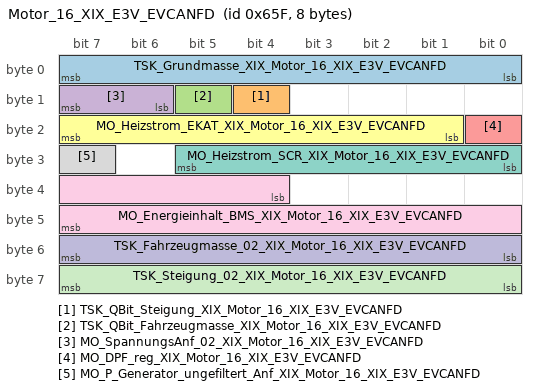
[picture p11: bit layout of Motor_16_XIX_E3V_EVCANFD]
      frame Motor_16_XIX_E3V_EVCANFD: id 0x65F, to Klima, frame-length=8, can-addressing-mode=STANDARD, can-frame-rx-behavior=CAN-FD, can-frame-tx-behavior=CAN-FD
        pdu Motor_16_XIX_E3V_EVCANFD: length=8, transmission-mode-true-timing=cyclic-timing={time-offset=0.0, time-period=0.5}, unused-bit-pattern=0
          signal TSK_Grundmasse_XIX_Motor_16_XIX_E3V_EVCANFD: start 0, 8 bit, little-endian, data-type-policy=OVERRIDE, i-signal-type=PRIMITIVE, init-value=0, base-type=BT_TSK_Grundmasse, compu {phys=raw*32 for raw 0..254; unit Unit_KiloGram}, range phys 0..8128 Unit_KiloGram, raw 0..254, unit=Unit_KiloGram, transfer-property=PENDING  # Fahrzeuggrundmasse in kg. Das Signal dient der Anpassung der Sollbeschleunigung vom ACC Hinweis: Ehemaliger Fehlerwert 0x7F wird senderseitig nicht unterstützt. Diesen Wert aus Kompatibilitätsgründen nicht neu belegen!
          signal TSK_QBit_Steigung_XIX_Motor_16_XIX_E3V_EVCANFD: start 12, 1 bit, little-endian, data-type-policy=OVERRIDE, i-signal-type=PRIMITIVE, init-value=1, base-type=BT_TSK_QBit_Steigung, compu {0=Cx0_gueltiger_Wert (CM_TSK_QBit_Steigung_Cx0_gueltiger_Wert), 1=Cx1_Ersatz_Init_oder_Fehlerwert (CM_TSK_QBit_Steigung_Cx1_Ersatz_Init_oder_Fehlerwert)}, range raw 0..1, transfer-property=PENDING, to Klima(timeout 5 s)
          signal TSK_QBit_Fahrzeugmasse_XIX_Motor_16_XIX_E3V_EVCANFD: start 13, 1 bit, little-endian, data-type-policy=OVERRIDE, i-signal-type=PRIMITIVE, init-value=1, base-type=BT_TSK_QBit_Fahrzeugmasse, compu {0=Cx0_gueltiger_Wert (CM_TSK_QBit_Fahrzeugmasse_Cx0_gueltiger_Wert), 1=Cx1_Ersatz_Init_oder_Fehlerwert (CM_TSK_QBit_Fahrzeugmasse_Cx1_Ersatz_Init_oder_Fehlerwert)}, range raw 0..1, transfer-property=PENDING
          signal MO_SpannungsAnf_02_XIX_Motor_16_XIX_E3V_EVCANFD: start 14, 2 bit, little-endian, data-type-policy=OVERRIDE, i-signal-type=PRIMITIVE, init-value=0, base-type=BT_MO_SpannungsAnf_02, compu {0=Cx0_keine_Anforderung (CM_MO_SpannungsAnf_02_Cx0_keine_Anforderung), 1=Cx1_Anforderung_Stufe_1 (CM_MO_SpannungsAnf_02_Cx1_Anforderung_Stufe_1), 2=Cx2_Anforderung_Stufe_2 (CM_MO_SpannungsAnf_02_Cx2_Anforderung_Stufe_2), 3=Cx3_Anforderung_Stufe_3 (CM_MO_SpannungsAnf_02_Cx3_Anforderung_Stufe_3)}, range raw 0..3, transfer-property=PENDING  # Forderung des Motor-SG's zur Spannungsanhebung
          signal MO_DPF_reg_XIX_Motor_16_XIX_E3V_EVCANFD: start 16, 1 bit, little-endian, data-type-policy=OVERRIDE, i-signal-type=PRIMITIVE, init-value=0, base-type=BT_MO_DPF_reg, compu {0=Cx0_DPF_regeneriert_nicht (CM_MO_DPF_reg_Cx0_DPF_regeneriert_nicht), 1=Cx1_DPF_regeneriert (CM_MO_DPF_reg_Cx1_DPF_regeneriert)}, range raw 0..1, transfer-property=PENDING  # Regeneration Diesel-Partikel-Filter
          signal MO_Heizstrom_EKAT_XIX_Motor_16_XIX_E3V_EVCANFD: start 17, 7 bit, little-endian, data-type-policy=OVERRIDE, i-signal-type=PRIMITIVE, init-value=0, base-type=BT_MO_Heizstrom_EKAT, invalid-value=Invalid_MO_Heizstrom_EKAT_XIX_Motor_16_XIX_E3V_EVCANFD:127, compu {phys=raw for raw 0..126, 127=Cx7f_Fehler (CM_MO_Heizstrom_EKAT_Cx7f_Fehler); unit Unit_Amper}, range phys 0..126 Unit_Amper, raw 0..127, unit=Unit_Amper, transfer-property=PENDING  # Aktuelle Gesamtstromaufnahme des E-Katalysators
          signal MO_Heizstrom_SCR_XIX_Motor_16_XIX_E3V_EVCANFD: start 24, 6 bit, little-endian, data-type-policy=OVERRIDE, i-signal-type=PRIMITIVE, init-value=0, base-type=BT_MO_Heizstrom_SCR, invalid-value=Invalid_MO_Heizstrom_SCR_XIX_Motor_16_XIX_E3V_EVCANFD:63, compu {phys=raw for raw 0..62, 63=Cx3f_Fehler (CM_MO_Heizstrom_SCR_Cx3f_Fehler); unit Unit_Amper}, range phys 0..62 Unit_Amper, raw 0..63, unit=Unit_Amper, transfer-property=PENDING  # Aktuelle Gesamtstromaufnahme der Tank-, Fördermodul- und Leitungsheizung des SCR-Systems
          signal MO_P_Generator_ungefiltert_Anf_XIX_Motor_16_XIX_E3V_EVCANFD: start 31, 1 bit, little-endian, data-type-policy=OVERRIDE, i-signal-type=PRIMITIVE, init-value=0, base-type=BT_MO_P_Generator_ungefiltert_Anf, compu {0=Cx0_nicht_angefordert (CM_MO_P_Generator_ungefiltert_Anf_Cx0_nicht_angefordert), 1=Cx1_angefordert (CM_MO_P_Generator_ungefiltert_Anf_Cx1_angefordert)}, range raw 0..1, transfer-property=PENDING  # Bei Empfang der Anforderung soll der Sender BEM_P_Generator ungefiltert befüllen.
          signal MO_Energieinhalt_BMS_XIX_Motor_16_XIX_E3V_EVCANFD: start 36, 12 bit, little-endian, data-type-policy=OVERRIDE, i-signal-type=PRIMITIVE, init-value=4094, base-type=BT_MO_Energieinhalt_BMS, invalid-value=Invalid_MO_Energieinhalt_BMS_XIX_Motor_16_XIX_E3V_EVCANFD:4095, compu {phys=raw*25 for raw 0..4093, 4094=Cxffe_Init (CM_MO_Energieinhalt_BMS_Cxffe_Init), 4095=Cxfff_Fehler (CM_MO_Energieinhalt_BMS_Cxfff_Fehler); unit Unit_WattHour}, range phys 0..102325 Unit_WattHour, raw 0..4095, unit=Unit_WattHour, transfer-property=PENDING  # Restenergieinhalt der Traktionsbatterie, beeinflusst durch Fahrstrategie und weiteren Faktoren der Antriebssteuerung.
          signal TSK_Fahrzeugmasse_02_XIX_Motor_16_XIX_E3V_EVCANFD: start 48, 8 bit, little-endian, data-type-policy=OVERRIDE, i-signal-type=PRIMITIVE, init-value=0, base-type=BT_TSK_Fahrzeugmasse_02, invalid-value=Invalid_TSK_Fahrzeugmasse_02_XIX_Motor_16_XIX_E3V_EVCANFD:255, compu {phys=raw*32 for raw 0..254, 255=Cxff_Fehler (CM_TSK_Fahrzeugmasse_02_Cxff_Fehler); unit Unit_KiloGram}, range phys 0..8128 Unit_KiloGram, raw 0..255, unit=Unit_KiloGram, transfer-property=PENDING  # Neue Definition ab D4 Fahrzeugmasse in kg. Das Signal dient der Anpassung der Sollbeschleunigung vom ACC
          signal TSK_Steigung_02_XIX_Motor_16_XIX_E3V_EVCANFD: start 56, 8 bit, little-endian, data-type-policy=OVERRIDE, i-signal-type=PRIMITIVE, init-value=0, base-type=BT_TSK_Steigung_02, invalid-value=Invalid_TSK_Steigung_02_XIX_Motor_16_XIX_E3V_EVCANFD:255, compu {0=Cx0_Init_oder_nicht_verbaut (CM_TSK_Steigung_02_Cx0_Init_oder_nicht_verbaut), phys=raw*0.8-101.6 for raw 1..254, 255=Cxff_Fehler (CM_TSK_Steigung_02_Cxff_Fehler); unit Unit_PerCent}, range phys -100.8..101.6 Unit_PerCent, raw 0..255, unit=Unit_PerCent, transfer-property=PENDING, to Klima(timeout 5 s)  # Steigung in % Berg. Das Signal dient der Anpassung der Sollbeschleunigung vom ACC Positive Werte > bergauf; Negative Werte < bergab Fehler: Die Steigung aufgrund eines Fehlers (mit KD-Fehlereintrag) nicht mehr berechnet werden
      frame Motor_26_XIX_E3V_EVCANFD: id 0x3C7, to Klima, frame-length=8, can-addressing-mode=STANDARD, can-frame-rx-behavior=CAN-FD, can-frame-tx-behavior=CAN-FD
        multiplexed i pdu Motor_26_XIX_E3V_EVCANFD:
          length=8
          dynamic-part{segment-position{segment-byte-order=little-endian, segment-length=8, segment-position=0}, dynamic-part-alternatives=[{i-pdu=Motor_26_Mx00_XIX_E3V_EVCANFD, initial-dynamic-part=true, selector-field-code=0}, {i-pdu=Motor_26_Mx01_XIX_E3V_EVCANFD, initial-dynamic-part=false, selector-field-code=1}]}
          selector-field-byte-order=little-endian
          selector-field-length=1
          selector-field-start-position=0
          static-part{segment-position{segment-byte-order=little-endian, segment-length=56, segment-position=8}, i-pdu=Motor_26_MxStatic_XIX_E3V_EVCANFD}
          trigger-mode=STATIC-OR-DYNAMIC-PART-TRIGGER
          unused-bit-pattern=0
